VERSION "HNNBNNNYNNNNNNNNNNNNNNNNNNNNNNNNNNNNNNNNNN/4/%%%/4/'%**4NNN///"

NS_ :

BS_:

BU_: ABT_1_MIB_ab_Gen3 ABT_1_MQB BAP_Tester BT_1_MQB DU_1_MQB DU_2 DU_3 DU_4 ExBox Kombi_TT3 LSR_1 SCC1 SCC2 SDC1 SDC2 SFA TVTuner_ab_Gen3_JPN WLC_01 WLC_02 ZR_Entry ZR_High ZR_High_Korea ZR_High_TT3 ZR_MIB_OPTION_ab_Gen3 ZR_MIB_TOP_ab_Gen3 ZR_Standard

BO_ 2549940736 OBDC_Funktionaler_Req_All: 8 ZR_MIB_TOP_ab_Gen3
 SG_ OBDC_Funktionaler_Req_All_Data : 0|64@1+ (1,0) [0|1.84467440737096E+019] ""  WLC_02,WLC_01

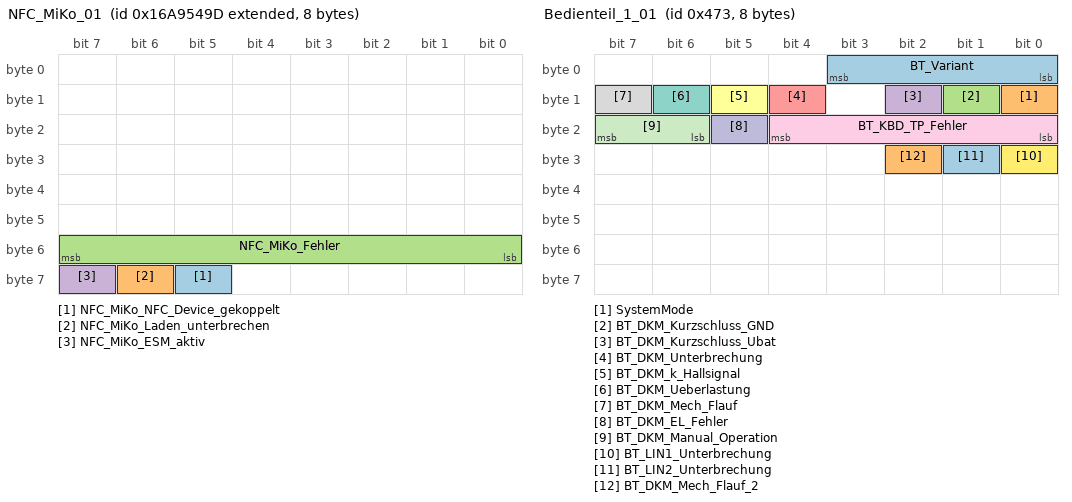
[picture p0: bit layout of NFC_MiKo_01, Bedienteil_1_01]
BO_ 2527679645 NFC_MiKo_01: 8 ZR_MIB_TOP_ab_Gen3
 SG_ NFC_MiKo_NFC_Device_gekoppelt : 61|1@1+ (1,0) [0|1] ""  WLC_01
 SG_ NFC_MiKo_Laden_unterbrechen : 62|1@1+ (1,0) [0|1] ""  WLC_01
 SG_ NFC_MiKo_Fehler : 48|8@1+ (1,0) [0|255] "" Vector__XXX
 SG_ NFC_MiKo_ESM_aktiv : 63|1@1+ (1,0) [0|1] "" Vector__XXX

BO_ 2583752965 ABT_1_SWDL_Req: 8 ABT_1_MQB
 SG_ ABT_1_SWDL_Req_Data : 0|64@1+ (1,0) [0|1.84467440737096E+019] ""  ZR_High,ZR_High_Korea,ZR_High_TT3,ZR_MIB_OPTION_ab_Gen3,ZR_MIB_TOP_ab_Gen3,ZR_Standard

BO_ 2583884037 ABT_1_SWDL_Resp: 8 ZR_High
 SG_ ABT_1_SWDL_Resp_Data : 0|64@1+ (1,0) [0|1.84467440737096E+019] ""  ABT_1_MQB

BO_ 2536714496 BAP_Audio_ASG_01: 8 Kombi_TT3
 SG_ BAP_Audio_ASG_01_Header : 0|8@1+ (1,0) [0|255] ""  ZR_High_TT3

BO_ 2536714497 BAP_Audio_ASG_02: 8 Kombi_TT3
 SG_ BAP_Audio_ASG_02_Header : 0|8@1+ (1,0) [0|255] ""  ZR_High_TT3

BO_ 2536714512 BAP_Audio_FSG_01: 8 ZR_High_TT3
 SG_ BAP_Audio_FSG_01_Header : 0|8@1+ (1,0) [0|255] ""  Kombi_TT3

BO_ 2536714513 BAP_Audio_FSG_02: 8 ZR_High_TT3
 SG_ BAP_Audio_FSG_02_Header : 0|8@1+ (1,0) [0|255] ""  Kombi_TT3

BO_ 2536767264 BAP_Debug_Cmd: 8 BAP_Tester
 SG_ BAP_Debug_Cmd : 0|16@1+ (1,0) [0|65535] ""  ExBox,Kombi_TT3,ZR_High_Korea,ZR_High_TT3

BO_ 2536767280 BAP_Debug_Data: 8 ExBox
 SG_ BAP_Debug_Data : 0|64@1+ (1,0) [0|1.84467440737096E+019] ""  BAP_Tester

BO_ 2536716288 BAP_ExBox_ASG_01: 8 ZR_High_Korea
 SG_ BAP_ExBox_ASG_01_Header : 0|8@1+ (1,0) [0|255] ""  ExBox

BO_ 2536716304 BAP_ExBox_FSG_01: 8 ExBox
 SG_ BAP_ExBox_FSG_01_Header : 0|8@1+ (1,0) [0|255] ""  ZR_High_Korea

BO_ 2536715264 BAP_MFL_ASG_01: 8 Kombi_TT3
 SG_ BAP_MFL_ASG_01_Header : 0|8@1+ (1,0) [0|255] ""  ZR_High_TT3

BO_ 2536715280 BAP_MFL_FSG_01: 8 ZR_High_TT3
 SG_ BAP_MFL_FSG_01_Header : 0|8@1+ (1,0) [0|255] ""  Kombi_TT3

BO_ 2536714752 BAP_Navigation_ASG_01: 8 Kombi_TT3
 SG_ BAP_Navigation_ASG_01_Header : 0|8@1+ (1,0) [0|255] ""  ExBox,ZR_High_TT3

BO_ 2536714753 BAP_Navigation_ASG_02: 8 Kombi_TT3
 SG_ BAP_Navigation_ASG_02_Header : 0|8@1+ (1,0) [0|255] ""  ExBox,ZR_High_TT3

BO_ 2536714754 BAP_Navigation_ASG_03: 8 ZR_High_Korea
 SG_ BAP_Navigation_ASG_03_Header : 0|8@1+ (1,0) [0|255] ""  ExBox

BO_ 2536714755 BAP_Navigation_ASG_04: 8 ZR_High_Korea
 SG_ BAP_Navigation_ASG_04_Header : 0|8@1+ (1,0) [0|255] ""  ExBox

BO_ 2536714768 BAP_Navigation_FSG_01: 8 ExBox
 SG_ BAP_Navigation_FSG_01_Header : 0|8@1+ (1,0) [0|255] ""  Kombi_TT3,ZR_High_Korea

BO_ 2536714769 BAP_Navigation_FSG_02: 8 ExBox
 SG_ BAP_Navigation_FSG_02_Header : 0|8@1+ (1,0) [0|255] ""  Kombi_TT3,ZR_High_Korea

BO_ 2536712448 BAP_Telefon2_ASG_01: 8 Kombi_TT3
 SG_ BAP_Telefon2_ASG_01_Header : 0|8@1+ (1,0) [0|255] ""  ExBox,ZR_High_TT3

BO_ 2536712464 BAP_Telefon2_FSG_01: 8 ExBox
 SG_ BAP_Telefon2_FSG_01_Header : 0|8@1+ (1,0) [0|255] ""  Kombi_TT3

BO_ 2536712192 BAP_Telefon_ASG_01: 8 Kombi_TT3
 SG_ BAP_Telefon_ASG_01_Header : 0|8@1+ (1,0) [0|255] ""  ExBox,ZR_High_TT3

BO_ 2536712193 BAP_Telefon_ASG_02: 8 Kombi_TT3
 SG_ BAP_Telefon_ASG_02_Header : 0|8@1+ (1,0) [0|255] ""  ExBox,ZR_High_TT3

BO_ 2536712194 BAP_Telefon_ASG_03: 8 ZR_High_Korea
 SG_ BAP_Telefon_ASG_03_Header : 0|8@1+ (1,0) [0|255] "Unit_None"  ExBox

BO_ 2536712195 BAP_Telefon_ASG_04: 8 ZR_High_Korea
 SG_ BAP_Telefon_ASG_04_Header : 0|8@1+ (1,0) [0|255] "Unit_None"  ExBox

BO_ 2536712208 BAP_Telefon_FSG_01: 8 ExBox
 SG_ BAP_Telefon_FSG_01_Header : 0|8@1+ (1,0) [0|255] ""  Kombi_TT3,ZR_High_Korea

BO_ 2536712209 BAP_Telefon_FSG_02: 8 ExBox
 SG_ BAP_Telefon_FSG_02_Header : 0|8@1+ (1,0) [0|255] ""  Kombi_TT3,ZR_High_Korea

BO_ 1139 Bedienteil_1_01: 8 BT_1_MQB
 SG_ BT_Variant : 0|4@1+ (1,0) [7|15] ""  ZR_Entry,ZR_High,ZR_High_Korea,ZR_High_TT3,ZR_MIB_OPTION_ab_Gen3,ZR_MIB_TOP_ab_Gen3,ZR_Standard
 SG_ SystemMode : 8|1@1+ (1,0) [0|1] ""  ZR_Entry,ZR_High,ZR_High_Korea,ZR_High_TT3,ZR_MIB_OPTION_ab_Gen3,ZR_MIB_TOP_ab_Gen3,ZR_Standard
 SG_ BT_DKM_Kurzschluss_GND : 9|1@1+ (1,0) [0|1] ""  ZR_Entry,ZR_High,ZR_High_Korea,ZR_High_TT3,ZR_MIB_OPTION_ab_Gen3,ZR_MIB_TOP_ab_Gen3,ZR_Standard
 SG_ BT_DKM_Kurzschluss_Ubat : 10|1@1+ (1,0) [0|1] ""  ZR_Entry,ZR_High,ZR_High_Korea,ZR_High_TT3,ZR_MIB_OPTION_ab_Gen3,ZR_MIB_TOP_ab_Gen3,ZR_Standard
 SG_ BT_DKM_Unterbrechung : 12|1@1+ (1,0) [0|1] ""  ZR_Entry,ZR_High,ZR_High_Korea,ZR_High_TT3,ZR_MIB_OPTION_ab_Gen3,ZR_MIB_TOP_ab_Gen3,ZR_Standard
 SG_ BT_DKM_k_Hallsignal : 13|1@1+ (1,0) [0|1] ""  ZR_Entry,ZR_High,ZR_High_Korea,ZR_High_TT3,ZR_MIB_OPTION_ab_Gen3,ZR_MIB_TOP_ab_Gen3,ZR_Standard
 SG_ BT_DKM_Ueberlastung : 14|1@1+ (1,0) [0|1] ""  ZR_Entry,ZR_High,ZR_High_Korea,ZR_High_TT3,ZR_MIB_OPTION_ab_Gen3,ZR_MIB_TOP_ab_Gen3,ZR_Standard
 SG_ BT_DKM_Mech_Flauf : 15|1@1+ (1,0) [0|1] ""  ZR_Entry,ZR_High,ZR_High_Korea,ZR_High_TT3,ZR_MIB_OPTION_ab_Gen3,ZR_MIB_TOP_ab_Gen3,ZR_Standard
 SG_ BT_KBD_TP_Fehler : 16|5@1+ (1,0) [1|31] ""  ZR_Entry,ZR_High,ZR_High_Korea,ZR_High_TT3,ZR_MIB_OPTION_ab_Gen3,ZR_MIB_TOP_ab_Gen3,ZR_Standard
 SG_ BT_DKM_EL_Fehler : 21|1@1+ (1,0) [0|1] ""  ZR_Entry,ZR_High,ZR_High_Korea,ZR_High_TT3,ZR_MIB_OPTION_ab_Gen3,ZR_MIB_TOP_ab_Gen3,ZR_Standard
 SG_ BT_DKM_Manual_Operation : 22|2@1+ (1,0) [0|3] ""  ZR_Entry,ZR_High,ZR_High_Korea,ZR_High_TT3,ZR_MIB_OPTION_ab_Gen3,ZR_MIB_TOP_ab_Gen3,ZR_Standard
 SG_ BT_LIN1_Unterbrechung : 24|1@1+ (1,0) [0|1] ""  ZR_Entry,ZR_High,ZR_High_Korea,ZR_High_TT3,ZR_MIB_OPTION_ab_Gen3,ZR_MIB_TOP_ab_Gen3,ZR_Standard
 SG_ BT_LIN2_Unterbrechung : 25|1@1+ (1,0) [0|1] ""  ZR_Entry,ZR_High,ZR_High_Korea,ZR_High_TT3,ZR_MIB_OPTION_ab_Gen3,ZR_MIB_TOP_ab_Gen3,ZR_Standard
 SG_ BT_DKM_Mech_Flauf_2 : 26|1@1+ (1,0) [0|1] ""  ZR_Entry,ZR_High,ZR_High_Korea,ZR_High_TT3,ZR_MIB_OPTION_ab_Gen3,ZR_MIB_TOP_ab_Gen3,ZR_Standard

BO_ 1635 BEM_02: 8 ZR_Entry
 SG_ BEM_02_Abschaltstufen : 0|3@1+ (1,0) [0|7] ""  ABT_1_MIB_ab_Gen3,ABT_1_MQB,BT_1_MQB,DU_3,DU_4,ExBox,LSR_1,SCC1,SCC2,SDC1,SDC2,WLC_01,WLC_02
 SG_ BEM_STH_Zielzeit : 3|4@1+ (5,0) [0|60] "Unit_Minut" Vector__XXX
 SG_ BEM_MMI_Vorwarnung : 7|1@1+ (1,0) [0|1] ""  BT_1_MQB,LSR_1,SCC1,SCC2,SDC1,SDC2
 SG_ BEM_HL_Kontingentierung : 8|6@1+ (50,-1000) [-1000|1000] "Unit_Watt" Vector__XXX
 SG_ NVEM_Freigabe_ZusBatt_Laden : 14|1@1+ (1,0) [0|1] "" Vector__XXX
 SG_ NVEM_Anf_SD_schalten : 15|1@1+ (1,0) [0|1] "" Vector__XXX
 SG_ BEM_Generatordiagnose : 16|2@1+ (1,0) [0|3] "" Vector__XXX
 SG_ BEM_Red_Innengeblaese : 18|2@1+ (1,0) [0|3] "" Vector__XXX
 SG_ BEM_STH_Einschaltverbot : 20|1@1+ (1,0) [0|1] "" Vector__XXX
 SG_ BEM_HL_Regelung_Status : 21|3@1+ (1,0) [0|7] "" Vector__XXX
 SG_ BEM_Ladezustand : 24|4@1+ (10,0) [0|100] "Unit_PerCent" Vector__XXX
 SG_ BEM_Batteriediagnose : 28|3@1+ (1,0) [0|7] "" Vector__XXX
 SG_ MIB_Stromsparmodus : 31|1@1+ (1,0) [0|1] "" Vector__XXX
 SG_ BEM_DFM : 32|5@1+ (3.225,0.025) [0.025|100] "" Vector__XXX
 SG_ BEM_REK_aktiv : 37|1@1+ (1,0) [0|1] "" Vector__XXX
 SG_ BEM_EMLIN_ungueltig : 38|1@1+ (1,0) [0|1] "" Vector__XXX
 SG_ BEM_Batt_Ab : 39|1@1+ (1,0) [0|1] "" Vector__XXX
 SG_ BEM_UBDM : 40|8@1+ (0.05,5) [5.05|17.7] "Unit_Volt" Vector__XXX
 SG_ BEM_UGenSoll : 48|6@1+ (0.1,10.6) [10.6|16] "Unit_Volt" Vector__XXX
 SG_ BEM_Anf_KL15_schalten : 54|2@1+ (1,0) [0|3] "" Vector__XXX
 SG_ NVEM_Batterie_Service : 56|2@1+ (1,0) [0|3] "" Vector__XXX
 SG_ NVEM_Freigabe_OnlineUpdate : 58|1@1+ (1,0) [0|1] "" Vector__XXX

BO_ 2583752709 BT_1_SWDL_Req: 8 BT_1_MQB
 SG_ BT_1_SWDL_Req_Data : 0|64@1+ (1,0) [0|1.84467440737096E+019] ""  ZR_Entry,ZR_High,ZR_High_Korea,ZR_High_TT3,ZR_MIB_OPTION_ab_Gen3,ZR_MIB_TOP_ab_Gen3,ZR_Standard

BO_ 2583883781 BT_1_SWDL_Resp: 8 ZR_Entry
 SG_ BT_1_SWDL_Resp_Data : 0|64@1+ (1,0) [0|1.84467440737096E+019] ""  BT_1_MQB

BO_ 2617215754 DEV_ABT_1_Gen3_Tx_01: 8 ABT_1_MIB_ab_Gen3
 SG_ DEV_ABT_1_Gen3_Tx_01_Data : 0|64@1+ (1,0) [0|1.84467440737096E+019] "" Vector__XXX

BO_ 2617215755 DEV_ABT_1_Gen3_Tx_02: 8 ABT_1_MIB_ab_Gen3
 SG_ DEV_ABT_1_Gen3_Tx_02_Data : 0|64@1+ (1,0) [0|1.84467440737096E+019] "" Vector__XXX

BO_ 2617215756 DEV_ABT_1_Gen3_Tx_03: 8 ABT_1_MIB_ab_Gen3
 SG_ DEV_ABT_1_Gen3_Tx_03_Data : 0|64@1+ (1,0) [0|1.84467440737096E+019] "" Vector__XXX

BO_ 2617215757 DEV_ABT_1_Gen3_Tx_04: 8 ABT_1_MIB_ab_Gen3
 SG_ DEV_ABT_1_Gen3_Tx_04_Data : 0|64@1+ (1,0) [0|1.84467440737096E+019] "" Vector__XXX

BO_ 2617215744 DEV_ABT_1_Req_00: 8 Vector__XXX
 SG_ DEV_ABT_1_Req_00 : 0|64@1+ (1,0) [0|1.84467440737096E+019] ""  ABT_1_MIB_ab_Gen3,ABT_1_MQB

BO_ 2617215748 DEV_ABT_1_Req_04: 8 Vector__XXX
 SG_ DEV_ABT_1_Req_04_Data : 0|64@1+ (1,0) [0|1.84467440737096E+019] ""  ABT_1_MIB_ab_Gen3,ABT_1_MQB

BO_ 2617215745 DEV_ABT_1_Resp_01: 8 ABT_1_MIB_ab_Gen3
 SG_ DEV_ABT_1_Resp_01 : 0|64@1+ (1,0) [0|1.84467440737096E+019] "" Vector__XXX

BO_ 2617215746 DEV_ABT_1_Resp_02: 8 ABT_1_MIB_ab_Gen3
 SG_ DEV_ABT_1_Resp_02 : 0|64@1+ (1,0) [0|1.84467440737096E+019] "" Vector__XXX

BO_ 2617215747 DEV_ABT_1_Resp_03: 8 ABT_1_MIB_ab_Gen3
 SG_ DEV_ABT_1_Resp_03 : 0|64@1+ (1,0) [0|1.84467440737096E+019] "" Vector__XXX

BO_ 2617215749 DEV_ABT_1_Resp_04: 8 ABT_1_MIB_ab_Gen3
 SG_ DEV_ABT_1_Resp_04_Data : 0|64@1+ (1,0) [0|1.84467440737096E+019] "" Vector__XXX

BO_ 2617213696 DEV_BT_1_Req_01: 8 Vector__XXX
 SG_ DEV_BT_1_Req_01 : 0|64@1+ (1,0) [0|1.84467440737096E+019] ""  BT_1_MQB

BO_ 2617213697 DEV_BT_1_Resp_01: 8 BT_1_MQB
 SG_ DEV_BT_1_Resp_01 : 0|64@1+ (1,0) [0|1.84467440737096E+019] "" Vector__XXX

BO_ 2617213698 DEV_BT_1_Tx_00: 8 BT_1_MQB
 SG_ DEV_BT_1_Tx_00 : 0|64@1+ (1,0) [0|1.84467440737096E+019] "" Vector__XXX

BO_ 2617213699 DEV_BT_1_Tx_01: 8 BT_1_MQB
 SG_ DEV_BT_1_Tx_01 : 0|64@1+ (1,0) [0|1.84467440737096E+019] "" Vector__XXX

BO_ 2617213700 DEV_BT_1_Tx_02: 8 BT_1_MQB
 SG_ DEV_BT_1_Tx_02 : 0|64@1+ (1,0) [0|1.84467440737096E+019] "" Vector__XXX

BO_ 2617217792 DEV_DU_1_Req_00: 8 Vector__XXX
 SG_ DEV_DU_1_Req_00_Data : 0|64@1+ (1,0) [0|1.84467440737096E+019] ""  DU_1_MQB

BO_ 2617217795 DEV_DU_1_Req_01: 8 Vector__XXX
 SG_ DEV_DU_1_Req_01_Data : 0|64@1+ (1,0) [0|1.84467440737096E+019] ""  DU_1_MQB

BO_ 2617217796 DEV_DU_1_Req_02: 8 Vector__XXX
 SG_ DEV_DU_1_Req_02_Data : 0|64@1+ (1,0) [0|1.84467440737096E+019] ""  DU_1_MQB

BO_ 2617217798 DEV_DU_1_Req_03: 8 Vector__XXX
 SG_ DEV_DU_1_Req_03_Data : 0|64@1+ (1,0) [0|1.84467440737096E+019] ""  DU_1_MQB

BO_ 2617217799 DEV_DU_1_Req_04: 8 Vector__XXX
 SG_ DEV_DU_1_Req_04_Data : 0|64@1+ (1,0) [0|1.84467440737096E+019] ""  DU_1_MQB

BO_ 2617217800 DEV_DU_1_Req_05: 8 Vector__XXX
 SG_ DEV_DU_1_Req_05_Data : 0|64@1+ (1,0) [0|1.84467440737096E+019] ""  DU_1_MQB

BO_ 2617217801 DEV_DU_1_Req_06: 8 Vector__XXX
 SG_ DEV_DU_1_Req_06_Data : 0|64@1+ (1,0) [0|1.84467440737096E+019] ""  DU_1_MQB

BO_ 2617217802 DEV_DU_1_Req_07: 8 Vector__XXX
 SG_ DEV_DU_1_Req_07_Data : 0|64@1+ (1,0) [0|1.84467440737096E+019] ""  DU_1_MQB

BO_ 2617217803 DEV_DU_1_Req_08: 8 Vector__XXX
 SG_ DEV_DU_1_Req_08_Data : 0|64@1+ (1,0) [0|1.84467440737096E+019] ""  DU_1_MQB

BO_ 2617217804 DEV_DU_1_Req_09: 8 Vector__XXX
 SG_ DEV_DU_1_Req_09_Data : 0|64@1+ (1,0) [0|1.84467440737096E+019] ""  DU_1_MQB

BO_ 2617217797 DEV_DU_1_Resp_00: 8 DU_1_MQB
 SG_ DEV_DU_1_Resp_00_Data : 0|64@1+ (1,0) [0|1.84467440737096E+019] "" Vector__XXX

BO_ 2617217793 DEV_DU_1_Resp_01: 8 DU_1_MQB
 SG_ DEV_DU_1_Resp_01_Data : 0|64@1+ (1,0) [0|1.84467440737096E+019] "" Vector__XXX

BO_ 2617217794 DEV_DU_1_Resp_02: 8 DU_1_MQB
 SG_ DEV_DU_1_Resp_02_Data : 0|64@1+ (1,0) [0|1.84467440737096E+019] "" Vector__XXX

BO_ 2617217805 DEV_DU_1_Resp_03: 8 DU_1_MQB
 SG_ DEV_DU_1_Resp_03_Data : 0|64@1+ (1,0) [0|1.84467440737096E+019] "" Vector__XXX

BO_ 2617217806 DEV_DU_1_Resp_04: 8 DU_1_MQB
 SG_ DEV_DU_1_Resp_04_Data : 0|64@1+ (1,0) [0|1.84467440737096E+019] "" Vector__XXX

BO_ 2617217807 DEV_DU_1_Resp_05: 8 DU_1_MQB
 SG_ DEV_DU_1_Resp_05_Data : 0|64@1+ (1,0) [0|1.84467440737096E+019] "" Vector__XXX

BO_ 2617217808 DEV_DU_1_Resp_06: 8 DU_1_MQB
 SG_ DEV_DU_1_Resp_06_Data : 0|64@1+ (1,0) [0|1.84467440737096E+019] "" Vector__XXX

BO_ 2617217809 DEV_DU_1_Resp_07: 8 DU_1_MQB
 SG_ DEV_DU_1_Resp_07_Data : 0|64@1+ (1,0) [0|1.84467440737096E+019] "" Vector__XXX

BO_ 2617217810 DEV_DU_1_Resp_08: 8 DU_1_MQB
 SG_ DEV_DU_1_Resp_08_Data : 0|64@1+ (1,0) [0|1.84467440737096E+019] "" Vector__XXX

BO_ 2617217811 DEV_DU_1_Resp_09: 8 DU_1_MQB
 SG_ DEV_DU_1_Resp_09_Data : 0|64@1+ (1,0) [0|1.84467440737096E+019] "" Vector__XXX

BO_ 2617223936 DEV_DU_2_Req_00: 8 Vector__XXX
 SG_ DEV_DU_2_Req_00_Data : 0|64@1+ (1,0) [0|1.84467440737096E+019] ""  DU_2

BO_ 2617223939 DEV_DU_2_Req_01: 8 Vector__XXX
 SG_ DEV_DU_2_Req_01_Data : 0|64@1+ (1,0) [0|1.84467440737096E+019] ""  DU_2

BO_ 2617223940 DEV_DU_2_Req_02: 8 Vector__XXX
 SG_ DEV_DU_2_Req_02_Data : 0|64@1+ (1,0) [0|1.84467440737096E+019] ""  DU_2

BO_ 2617223942 DEV_DU_2_Req_03: 8 Vector__XXX
 SG_ DEV_DU_2_Req_03_Data : 0|64@1+ (1,0) [0|1.84467440737096E+019] ""  DU_2

BO_ 2617223943 DEV_DU_2_Req_04: 8 Vector__XXX
 SG_ DEV_DU_2_Req_04_Data : 0|64@1+ (1,0) [0|1.84467440737096E+019] ""  DU_2

BO_ 2617223944 DEV_DU_2_Req_05: 8 Vector__XXX
 SG_ DEV_DU_2_Req_05_Data : 0|64@1+ (1,0) [0|1.84467440737096E+019] ""  DU_2

BO_ 2617223945 DEV_DU_2_Req_06: 8 Vector__XXX
 SG_ DEV_DU_2_Req_06_Data : 0|64@1+ (1,0) [0|1.84467440737096E+019] ""  DU_2

BO_ 2617223946 DEV_DU_2_Req_07: 8 Vector__XXX
 SG_ DEV_DU_2_Req_07_Data : 0|64@1+ (1,0) [0|1.84467440737096E+019] ""  DU_2

BO_ 2617223947 DEV_DU_2_Req_08: 8 Vector__XXX
 SG_ DEV_DU_2_Req_08_Data : 0|64@1+ (1,0) [0|1.84467440737096E+019] ""  DU_2

BO_ 2617223948 DEV_DU_2_Req_09: 8 Vector__XXX
 SG_ DEV_DU_2_Req_09_Data : 0|64@1+ (1,0) [0|1.84467440737096E+019] ""  DU_2

BO_ 2617223941 DEV_DU_2_Resp_00: 8 DU_2
 SG_ DEV_DU_2_Resp_00_Data : 0|64@1+ (1,0) [0|1.84467440737096E+019] "" Vector__XXX

BO_ 2617223937 DEV_DU_2_Resp_01: 8 DU_2
 SG_ DEV_DU_2_Resp_01_Data : 0|64@1+ (1,0) [0|1.84467440737096E+019] "" Vector__XXX

BO_ 2617223938 DEV_DU_2_Resp_02: 8 DU_2
 SG_ DEV_DU_2_Resp_02_Data : 0|64@1+ (1,0) [0|1.84467440737096E+019] "" Vector__XXX

BO_ 2617223949 DEV_DU_2_Resp_03: 8 DU_2
 SG_ DEV_DU_2_Resp_03_Data : 0|64@1+ (1,0) [0|1.84467440737096E+019] "" Vector__XXX

BO_ 2617223950 DEV_DU_2_Resp_04: 8 DU_2
 SG_ DEV_DU_2_Resp_04_Data : 0|64@1+ (1,0) [0|1.84467440737096E+019] "" Vector__XXX

BO_ 2617223951 DEV_DU_2_Resp_05: 8 DU_2
 SG_ DEV_DU_2_Resp_05_Data : 0|64@1+ (1,0) [0|1.84467440737096E+019] "" Vector__XXX

BO_ 2617223952 DEV_DU_2_Resp_06: 8 DU_2
 SG_ DEV_DU_2_Resp_06_Data : 0|64@1+ (1,0) [0|1.84467440737096E+019] "" Vector__XXX

BO_ 2617223953 DEV_DU_2_Resp_07: 8 DU_2
 SG_ DEV_DU_2_Resp_07_Data : 0|64@1+ (1,0) [0|1.84467440737096E+019] "" Vector__XXX

BO_ 2617223954 DEV_DU_2_Resp_08: 8 DU_2
 SG_ DEV_DU_2_Resp_08_Data : 0|64@1+ (1,0) [0|1.84467440737096E+019] "" Vector__XXX

BO_ 2617223955 DEV_DU_2_Resp_09: 8 DU_2
 SG_ DEV_DU_2_Resp_09_Data : 0|64@1+ (1,0) [0|1.84467440737096E+019] "" Vector__XXX

BO_ 2617152256 DEV_LSR_1_Req_01: 8 Vector__XXX
 SG_ DEV_LSR_1_Req_01 : 0|64@1+ (1,0) [0|1.84467440737096E+019] ""  LSR_1

BO_ 2617152257 DEV_LSR_1_Resp_01: 8 LSR_1
 SG_ DEV_LSR_1_Resp_01 : 0|64@1+ (1,0) [0|1.84467440737096E+019] "" Vector__XXX

BO_ 2617152258 DEV_LSR_1_Resp_02: 8 LSR_1
 SG_ DEV_LSR_1_Resp_02 : 0|64@1+ (1,0) [0|1.84467440737096E+019] "" Vector__XXX

BO_ 2617070336 DEV_SCC1_Req_00: 8 SCC1
 SG_ DEV_SCC_01_Req_00 : 0|64@1+ (1,0) [0|1.84467440737096E+019] "" Vector__XXX

BO_ 2617070337 DEV_SCC1_Resp_01: 8 SCC1
 SG_ DEV_SCC1_Resp_01 : 0|64@1+ (1,0) [0|1.84467440737096E+019] "" Vector__XXX

BO_ 2617070338 DEV_SCC1_Resp_02: 8 SCC1
 SG_ DEV_SCC1_Resp_02 : 0|64@1+ (1,0) [0|1.84467440737096E+019] "" Vector__XXX

BO_ 2617072384 DEV_SCC2_Req_00: 8 SCC2
 SG_ DEV_SCC2_Req_00 : 0|64@1+ (1,0) [0|1.84467440737096E+019] "" Vector__XXX

BO_ 2617072385 DEV_SCC2_Resp_01: 8 SCC2
 SG_ DEV_SCC2_Resp_01 : 0|64@1+ (1,0) [0|1.84467440737096E+019] "" Vector__XXX

BO_ 2617072386 DEV_SCC2_Resp_02: 8 SCC2
 SG_ DEV_SCC2_Resp_02 : 0|64@1+ (1,0) [0|1.84467440737096E+019] "" Vector__XXX

BO_ 2617064192 DEV_SDC1_Req_00: 8 Vector__XXX
 SG_ DEV_SDC1_Req_00 : 0|64@1+ (1,0) [0|1.84467440737096E+019] ""  SDC1

BO_ 2617064193 DEV_SDC1_Resp_01: 8 SDC1
 SG_ DEV_SDC1_Resp_01 : 0|64@1+ (1,0) [0|1.84467440737096E+019] "" Vector__XXX

BO_ 2617064194 DEV_SDC1_Resp_02: 8 SDC1
 SG_ DEV_SDC1_Resp_02 : 0|64@1+ (1,0) [0|1.84467440737096E+019] "" Vector__XXX

BO_ 2617066240 DEV_SDC2_Req_00: 8 Vector__XXX
 SG_ DEV_SDC2_Req_00 : 0|64@1+ (1,0) [0|1.84467440737096E+019] ""  SDC2

BO_ 2617066241 DEV_SDC2_Resp_01: 8 SDC2
 SG_ DEV_SDC2_Resp_01 : 0|64@1+ (1,0) [0|1.84467440737096E+019] "" Vector__XXX

BO_ 2617066242 DEV_SDC2_Resp_02: 8 SDC2
 SG_ DEV_SDC2_Resp_02 : 0|64@1+ (1,0) [0|1.84467440737096E+019] "" Vector__XXX

BO_ 2617219597 DEV_ZR_Req_0D: 8 Vector__XXX
 SG_ DEV_ZR_Req_0D_Data : 0|64@1+ (1,0) [0|1] ""  ZR_High_Korea,ZR_High_TT3

BO_ 2617219584 DEV_ZR_Resp_00: 8 ZR_High_Korea
 SG_ DEV_ZR_Resp_00_Data : 0|64@1+ (1,0) [0|1] "" Vector__XXX

BO_ 2617219604 DEV_ZR_Tx_14: 8 ZR_Entry
 SG_ DEV_ZR_Tx_14_Data : 0|64@1+ (1,0) [0|1] "" Vector__XXX

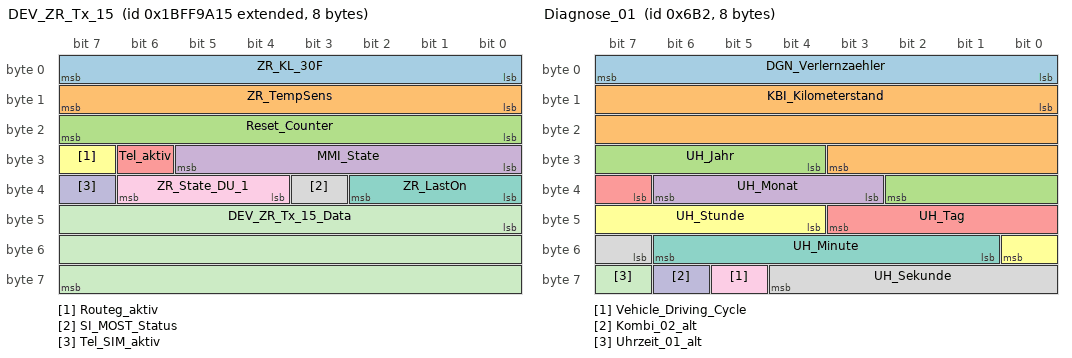
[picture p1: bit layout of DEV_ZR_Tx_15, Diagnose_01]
BO_ 2617219605 DEV_ZR_Tx_15: 8 ZR_Entry
 SG_ ZR_KL_30F : 0|8@1+ (0.1,0) [0|25.3] "Unit_Volt" Vector__XXX
 SG_ ZR_TempSens : 8|8@1+ (1,-55) [-55|127] "Unit_DegreCelsi" Vector__XXX
 SG_ Reset_Counter : 16|8@1+ (1,0) [0|253] "" Vector__XXX
 SG_ MMI_State : 24|6@1+ (1,0) [0|63] "" Vector__XXX
 SG_ Tel_aktiv : 30|1@1+ (1,0) [0|1] "" Vector__XXX
 SG_ Routeg_aktiv : 31|1@1+ (1,0) [0|1] "" Vector__XXX
 SG_ ZR_LastOn : 32|3@1+ (1,0) [0|6] "" Vector__XXX
 SG_ SI_MOST_Status : 35|1@1+ (1,0) [0|1] "" Vector__XXX
 SG_ ZR_State_DU_1 : 36|3@1+ (1,0) [0|7] "" Vector__XXX
 SG_ Tel_SIM_aktiv : 39|1@1+ (1,0) [0|1] "" Vector__XXX
 SG_ DEV_ZR_Tx_15_Data : 40|24@1+ (1,0) [0|1] "" Vector__XXX

BO_ 2549880334 DIA_ABT_1_Req: 8 Vector__XXX
 SG_ DIA_ABT_1_Req_Data : 0|64@1+ (1,0) [0|1.84467440737096E+019] ""  ABT_1_MIB_ab_Gen3

BO_ 2550011406 DIA_ABT_1_Resp: 8 ABT_1_MIB_ab_Gen3
 SG_ DIA_ABT_1_Resp_Data : 0|64@1+ (1,0) [0|1.84467440737096E+019] "" Vector__XXX

BO_ 2549880610 DIA_SCON1_Req: 8 ZR_High
 SG_ DIA_SCON1_Req_Data : 0|64@1+ (1,0) [0|1.84467440737096E+019] ""  SCC1

BO_ 2550011682 DIA_SCON1_Resp: 8 SCC1
 SG_ DIA_SCON1_Resp_Data : 0|64@1+ (1,0) [0|1.84467440737096E+019] ""  ZR_High

BO_ 2549880611 DIA_SCON2_Req: 8 ZR_High
 SG_ DIA_SCON2_Req_Data : 0|64@1+ (1,0) [0|1.84467440737096E+019] ""  SCC2

BO_ 2550011683 DIA_SCON2_Resp: 8 SCC2
 SG_ DIA_SCON2_Resp_Data : 0|64@1+ (1,0) [0|1.84467440737096E+019] ""  ZR_High

BO_ 2549880473 DIA_SD3_Req: 8 ZR_High
 SG_ DIA_SD3_Req_Data : 0|64@1+ (1,0) [0|1.84467440737096E+019] ""  SDC1

BO_ 2550011545 DIA_SD3_Resp: 8 SDC1
 SG_ DIA_SD3_Resp_Data : 0|64@1+ (1,0) [0|1.84467440737096E+019] ""  ZR_High

BO_ 2549880474 DIA_SD4_Req: 8 ZR_High
 SG_ DIA_SD4_Req_Data : 0|64@1+ (1,0) [0|1.84467440737096E+019] ""  SDC2

BO_ 2550011546 DIA_SD4_Resp: 8 SDC2
 SG_ DIA_SD4_Resp_Data : 0|64@1+ (1,0) [0|1.84467440737096E+019] ""  ZR_High

BO_ 2549876238 Diag_ABT_1_Req: 8 ZR_High
 SG_ Diag_ABT_1_Req_Data : 0|64@1+ (1,0) [0|1.84467440737096E+019] ""  ABT_1_MIB_ab_Gen3,ABT_1_MQB

BO_ 2550007310 Diag_ABT_1_Resp: 8 ABT_1_MIB_ab_Gen3
 SG_ Diag_ABT_1_Resp_Data : 0|64@1+ (1,0) [0|1.84467440737096E+019] ""  ZR_High,ZR_High_Korea,ZR_High_TT3,ZR_MIB_OPTION_ab_Gen3,ZR_MIB_TOP_ab_Gen3,ZR_Standard

BO_ 2549876295 Diag_BT_1_Req: 8 ZR_Entry
 SG_ Diag_BT_1_Req_Data : 0|64@1+ (1,0) [0|1.84467440737096E+019] ""  BT_1_MQB

BO_ 2550007367 Diag_BT_1_Resp: 8 BT_1_MQB
 SG_ Diag_BT_1_Resp_Data : 0|64@1+ (1,0) [0|1.84467440737096E+019] ""  ZR_Entry,ZR_High,ZR_High_Korea,ZR_High_TT3,ZR_MIB_OPTION_ab_Gen3,ZR_MIB_TOP_ab_Gen3,ZR_Standard

BO_ 2549876278 Diag_DU_1_Req: 8 ZR_Entry
 SG_ Diag_DU_1_Req_Data : 0|64@1+ (1,0) [0|1.84467440737096E+019] ""  DU_1_MQB

BO_ 2550007350 Diag_DU_1_Resp: 8 DU_1_MQB
 SG_ Diag_DU_1_Resp_Data : 0|64@1+ (1,0) [0|1.84467440737096E+019] ""  ZR_Entry,ZR_High,ZR_High_Korea,ZR_High_TT3,ZR_MIB_OPTION_ab_Gen3,ZR_MIB_TOP_ab_Gen3,ZR_Standard

BO_ 2549876379 Diag_DU_2_Req: 8 ZR_High
 SG_ Diag_DU_2_Req_Data : 0|64@1+ (1,0) [0|1.84467440737096E+019] ""  DU_2

BO_ 2550007451 Diag_DU_2_Resp: 8 DU_2
 SG_ Diag_DU_2_Resp_Data : 0|64@1+ (1,0) [0|1.84467440737096E+019] ""  ZR_High,ZR_MIB_OPTION_ab_Gen3,ZR_MIB_TOP_ab_Gen3,ZR_Standard

BO_ 2549876381 Diag_DU_3_Req: 8 ZR_High
 SG_ Diag_DU_3_Req_Data : 0|64@1+ (1,0) [0|1.84467440737096E+019] ""  DU_3

BO_ 2550007453 Diag_DU_3_Resp: 8 DU_3
 SG_ Diag_DU_3_Resp_Data : 0|64@1+ (1,0) [0|1.84467440737096E+019] ""  ZR_High,ZR_MIB_TOP_ab_Gen3

BO_ 2549876382 Diag_DU_4_Req: 8 ZR_High
 SG_ Diag_DU_4_Req_Data : 0|64@1+ (1,0) [0|1.84467440737096E+019] ""  DU_4

BO_ 2550007454 Diag_DU_4_Resp: 8 DU_4
 SG_ Diag_DU_4_Resp_Data : 0|64@1+ (1,0) [0|1.84467440737096E+019] ""  ZR_High

BO_ 2549876371 Diag_LSR_1_Req: 8 ZR_High
 SG_ Diag_LSR_1_Req_Data : 0|64@1+ (1,0) [0|1.84467440737096E+019] ""  LSR_1

BO_ 2550007443 Diag_LSR_1_Resp: 8 LSR_1
 SG_ Diag_LSR_1_Resp_Data : 0|64@1+ (1,0) [0|1.84467440737096E+019] ""  ZR_High,ZR_MIB_OPTION_ab_Gen3,ZR_MIB_TOP_ab_Gen3,ZR_Standard

BO_ 1714 Diagnose_01: 8 ZR_High
 SG_ DGN_Verlernzaehler : 0|8@1+ (1,0) [0|254] ""  ABT_1_MIB_ab_Gen3,ExBox,SCC1,SCC2,SDC1,SDC2
 SG_ KBI_Kilometerstand : 8|20@1+ (1,0) [0|1048573] "Unit_KiloMeter"  ABT_1_MIB_ab_Gen3,ExBox,SCC1,SCC2,SDC1,SDC2
 SG_ UH_Jahr : 28|7@1+ (1,2000) [2000|2127] "Unit_Year"  DU_1_MQB,DU_2,WLC_01,WLC_02,ABT_1_MIB_ab_Gen3,DU_4,ExBox,SCC1,SCC2,SDC1,SDC2,TVTuner_ab_Gen3_JPN
 SG_ UH_Monat : 35|4@1+ (1,0) [1|12] "Unit_Month"  DU_2,DU_1_MQB,WLC_01,WLC_02,ABT_1_MIB_ab_Gen3,DU_4,ExBox,SCC1,SCC2,SDC1,SDC2,TVTuner_ab_Gen3_JPN
 SG_ UH_Tag : 39|5@1+ (1,0) [1|31] "Unit_Day"  DU_1_MQB,DU_2,WLC_01,WLC_02,ABT_1_MIB_ab_Gen3,DU_4,ExBox,SCC1,SCC2,SDC1,SDC2,TVTuner_ab_Gen3_JPN
 SG_ UH_Stunde : 44|5@1+ (1,0) [0|23] "Unit_Hours"  DU_1_MQB,DU_2,WLC_01,WLC_02,ABT_1_MIB_ab_Gen3,DU_4,ExBox,SCC1,SCC2,SDC1,SDC2,TVTuner_ab_Gen3_JPN
 SG_ UH_Minute : 49|6@1+ (1,0) [0|59] "Unit_Minut"  DU_1_MQB,DU_2,WLC_01,WLC_02,ABT_1_MIB_ab_Gen3,DU_4,ExBox,SCC1,SCC2,SDC1,SDC2,TVTuner_ab_Gen3_JPN
 SG_ UH_Sekunde : 55|6@1+ (1,0) [0|59] "Unit_Secon"  DU_1_MQB,DU_2,WLC_01,WLC_02,ABT_1_MIB_ab_Gen3,DU_4,ExBox,SCC1,SCC2,SDC1,SDC2,TVTuner_ab_Gen3_JPN
 SG_ Vehicle_Driving_Cycle : 61|1@1+ (1,0) [0|1] ""  ABT_1_MIB_ab_Gen3
 SG_ Kombi_02_alt : 62|1@1+ (1,0) [0|1] ""  WLC_01,WLC_02,ABT_1_MIB_ab_Gen3,ExBox,SCC1,SCC2,SDC1,SDC2
 SG_ Uhrzeit_01_alt : 63|1@1+ (1,0) [0|1] ""  WLC_01,WLC_02,ABT_1_MIB_ab_Gen3,ExBox,SCC1,SCC2,SDC1,SDC2

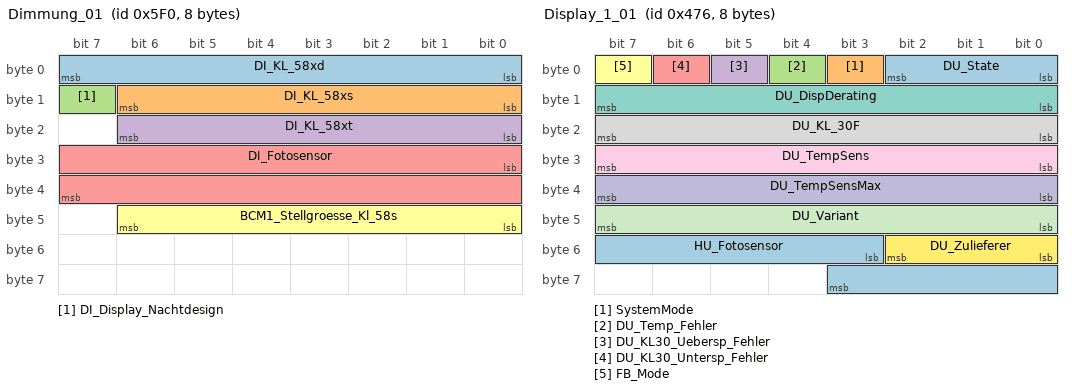
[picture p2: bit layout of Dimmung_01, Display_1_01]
BO_ 1520 Dimmung_01: 8 ZR_Entry
 SG_ DI_KL_58xd : 0|8@1+ (1,0) [0|253] ""  SCC1,ABT_1_MIB_ab_Gen3,ABT_1_MQB,BT_1_MQB,DU_1_MQB,DU_2,DU_3,DU_4,ExBox,LSR_1,SDC1,SDC2
 SG_ DI_KL_58xs : 8|7@1+ (1,0) [0|100] "Unit_PerCent"  SCC1,ABT_1_MIB_ab_Gen3,ABT_1_MQB,BT_1_MQB,DU_1_MQB,DU_2,DU_3,DU_4,ExBox,LSR_1,SDC1,SDC2
 SG_ DI_Display_Nachtdesign : 15|1@1+ (1,0) [0|1] ""  DU_2,DU_3,DU_4,ExBox
 SG_ DI_KL_58xt : 16|7@1+ (1,0) [0|100] "Unit_PerCent" Vector__XXX
 SG_ DI_Fotosensor : 24|16@1+ (1,0) [0|65535] "" Vector__XXX
 SG_ BCM1_Stellgroesse_Kl_58s : 40|7@1+ (1,0) [0|100] "" Vector__XXX

BO_ 1142 Display_1_01: 8 ABT_1_MIB_ab_Gen3
 SG_ DU_State : 0|3@1+ (1,0) [0|7] ""  ZR_Entry,ZR_High,ZR_High_Korea,ZR_High_TT3,ZR_MIB_OPTION_ab_Gen3,ZR_MIB_TOP_ab_Gen3,ZR_Standard
 SG_ SystemMode : 3|1@1+ (1,0) [0|1] ""  ZR_Entry,ZR_High,ZR_High_Korea,ZR_High_TT3,ZR_MIB_OPTION_ab_Gen3,ZR_MIB_TOP_ab_Gen3,ZR_Standard
 SG_ DU_Temp_Fehler : 4|1@1+ (1,0) [0|1] ""  ZR_Entry,ZR_High,ZR_High_Korea,ZR_High_TT3,ZR_MIB_OPTION_ab_Gen3,ZR_MIB_TOP_ab_Gen3,ZR_Standard
 SG_ DU_KL30_Uebersp_Fehler : 5|1@1+ (1,0) [0|1] ""  ZR_Entry,ZR_High,ZR_High_Korea,ZR_High_TT3,ZR_MIB_OPTION_ab_Gen3,ZR_MIB_TOP_ab_Gen3,ZR_Standard
 SG_ DU_KL30_Untersp_Fehler : 6|1@1+ (1,0) [0|1] ""  ZR_Entry,ZR_High,ZR_High_Korea,ZR_High_TT3,ZR_MIB_OPTION_ab_Gen3,ZR_MIB_TOP_ab_Gen3,ZR_Standard
 SG_ FB_Mode : 7|1@1+ (1,0) [0|1] "" Vector__XXX
 SG_ DU_DispDerating : 8|8@1+ (1,0) [0|100] "Unit_PerCent"  DU_2,DU_4,ZR_Entry,ZR_High,ZR_High_Korea,ZR_High_TT3,ZR_MIB_OPTION_ab_Gen3,ZR_MIB_TOP_ab_Gen3,ZR_Standard
 SG_ DU_KL_30F : 16|8@1+ (0.1,0) [0|25.3] "Unit_Volt"  ZR_Entry,ZR_High,ZR_High_Korea,ZR_High_TT3,ZR_MIB_OPTION_ab_Gen3,ZR_MIB_TOP_ab_Gen3,ZR_Standard
 SG_ DU_TempSens : 24|8@1+ (1,-55) [-55|127] "Unit_DegreCelsi"  BT_1_MQB,ZR_Entry,ZR_High,ZR_High_Korea,ZR_High_TT3,ZR_MIB_OPTION_ab_Gen3,ZR_MIB_TOP_ab_Gen3,ZR_Standard
 SG_ DU_TempSensMax : 32|8@1+ (1,-55) [-55|127] "Unit_DegreCelsi"  ZR_Entry,ZR_High,ZR_High_Korea,ZR_High_TT3,ZR_MIB_OPTION_ab_Gen3,ZR_MIB_TOP_ab_Gen3,ZR_Standard
 SG_ DU_Variant : 40|8@1+ (1,0) [0|253] ""  BT_1_MQB,ZR_Entry,ZR_High,ZR_High_Korea,ZR_High_TT3,ZR_MIB_OPTION_ab_Gen3,ZR_MIB_TOP_ab_Gen3,ZR_Standard
 SG_ DU_Zulieferer : 48|3@1+ (1,0) [0|7] ""  ZR_Entry,ZR_High,ZR_High_Korea,ZR_High_TT3,ZR_MIB_OPTION_ab_Gen3,ZR_MIB_TOP_ab_Gen3,ZR_Standard
 SG_ HU_Fotosensor : 51|9@1+ (0.25,0) [0|100] "Unit_PerCent"  ZR_High,ZR_MIB_OPTION_ab_Gen3,ZR_MIB_TOP_ab_Gen3,ZR_Standard

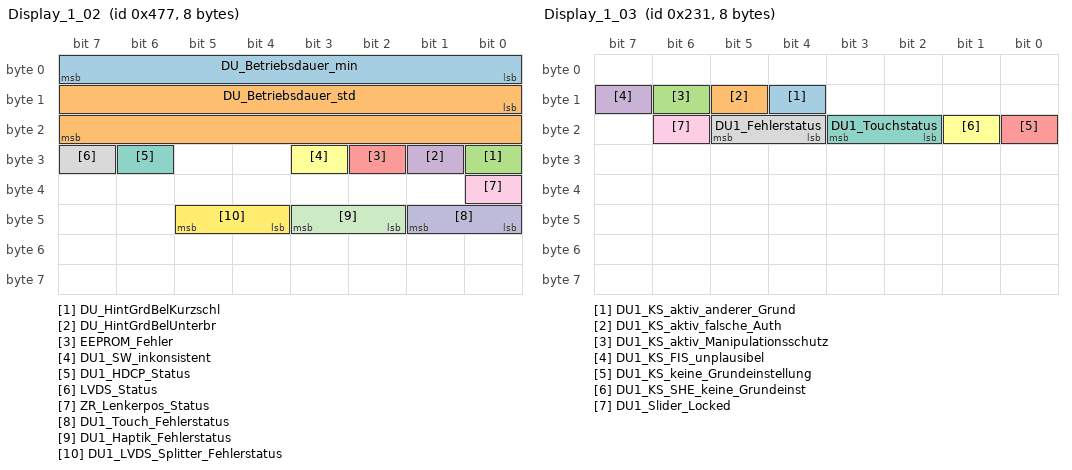
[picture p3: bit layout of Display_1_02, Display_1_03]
BO_ 1143 Display_1_02: 8 ABT_1_MIB_ab_Gen3
 SG_ DU_Betriebsdauer_min : 0|8@1+ (1,0) [0|59] "Unit_Minut"  ZR_Entry,ZR_High,ZR_High_Korea,ZR_High_TT3,ZR_MIB_OPTION_ab_Gen3,ZR_MIB_TOP_ab_Gen3,ZR_Standard
 SG_ DU_Betriebsdauer_std : 8|16@1+ (1,0) [0|65533] "Unit_Hours"  ZR_Entry,ZR_High,ZR_High_Korea,ZR_High_TT3,ZR_MIB_OPTION_ab_Gen3,ZR_MIB_TOP_ab_Gen3,ZR_Standard
 SG_ DU_HintGrdBelKurzschl : 24|1@1+ (1,0) [0|1] ""  ZR_Entry,ZR_High,ZR_High_Korea,ZR_High_TT3,ZR_MIB_OPTION_ab_Gen3,ZR_MIB_TOP_ab_Gen3,ZR_Standard
 SG_ DU_HintGrdBelUnterbr : 25|1@1+ (1,0) [0|1] ""  ZR_Entry,ZR_High,ZR_High_Korea,ZR_High_TT3,ZR_MIB_OPTION_ab_Gen3,ZR_MIB_TOP_ab_Gen3,ZR_Standard
 SG_ EEPROM_Fehler : 26|1@1+ (1,0) [0|1] ""  ZR_Entry,ZR_High,ZR_High_Korea,ZR_High_TT3,ZR_MIB_OPTION_ab_Gen3,ZR_MIB_TOP_ab_Gen3,ZR_Standard
 SG_ DU1_SW_inkonsistent : 27|1@1+ (1,0) [0|1] ""  ZR_Entry,ZR_High,ZR_High_Korea,ZR_High_TT3,ZR_MIB_OPTION_ab_Gen3,ZR_MIB_TOP_ab_Gen3,ZR_Standard
 SG_ DU1_HDCP_Status : 30|1@1+ (1,0) [0|1] ""  ZR_Entry,ZR_High,ZR_High_Korea,ZR_High_TT3,ZR_MIB_OPTION_ab_Gen3,ZR_MIB_TOP_ab_Gen3,ZR_Standard
 SG_ LVDS_Status : 31|1@1+ (1,0) [0|1] ""  ZR_Entry,ZR_High,ZR_High_Korea,ZR_High_TT3,ZR_MIB_OPTION_ab_Gen3,ZR_MIB_TOP_ab_Gen3,ZR_Standard
 SG_ ZR_Lenkerpos_Status : 32|1@1+ (1,0) [0|1] "" Vector__XXX
 SG_ DU1_Touch_Fehlerstatus : 40|2@1+ (1,0) [0|3] ""  ZR_Entry,ZR_High,ZR_High_Korea,ZR_High_TT3,ZR_MIB_OPTION_ab_Gen3,ZR_MIB_TOP_ab_Gen3,ZR_Standard
 SG_ DU1_Haptik_Fehlerstatus : 42|2@1+ (1,0) [0|3] ""  ZR_Entry,ZR_High,ZR_High_Korea,ZR_High_TT3,ZR_MIB_OPTION_ab_Gen3,ZR_MIB_TOP_ab_Gen3,ZR_Standard
 SG_ DU1_LVDS_Splitter_Fehlerstatus : 44|2@1+ (1,0) [0|3] ""  ZR_Entry,ZR_High,ZR_High_Korea,ZR_High_TT3,ZR_MIB_OPTION_ab_Gen3,ZR_MIB_TOP_ab_Gen3,ZR_Standard

BO_ 561 Display_1_03: 8 ABT_1_MIB_ab_Gen3
 SG_ DU1_KS_aktiv_anderer_Grund : 12|1@1+ (1,0) [0|1] ""  ZR_MIB_OPTION_ab_Gen3
 SG_ DU1_KS_aktiv_falsche_Auth : 13|1@1+ (1,0) [0|1] ""  ZR_MIB_OPTION_ab_Gen3
 SG_ DU1_KS_aktiv_Manipulationsschutz : 14|1@1+ (1,0) [0|1] ""  ZR_MIB_OPTION_ab_Gen3
 SG_ DU1_KS_FIS_unplausibel : 15|1@1+ (1,0) [0|1] ""  ZR_MIB_OPTION_ab_Gen3
 SG_ DU1_KS_keine_Grundeinstellung : 16|1@1+ (1,0) [0|1] ""  ZR_MIB_OPTION_ab_Gen3
 SG_ DU1_KS_SHE_keine_Grundeinst : 17|1@1+ (1,0) [0|1] ""  ZR_MIB_OPTION_ab_Gen3
 SG_ DU1_Touchstatus : 18|2@1+ (1,0) [0|3] "" Vector__XXX
 SG_ DU1_Fehlerstatus : 20|2@1+ (1,0) [0|3] "" Vector__XXX
 SG_ DU1_Slider_Locked : 22|1@1+ (1,0) [0|1] "" Vector__XXX

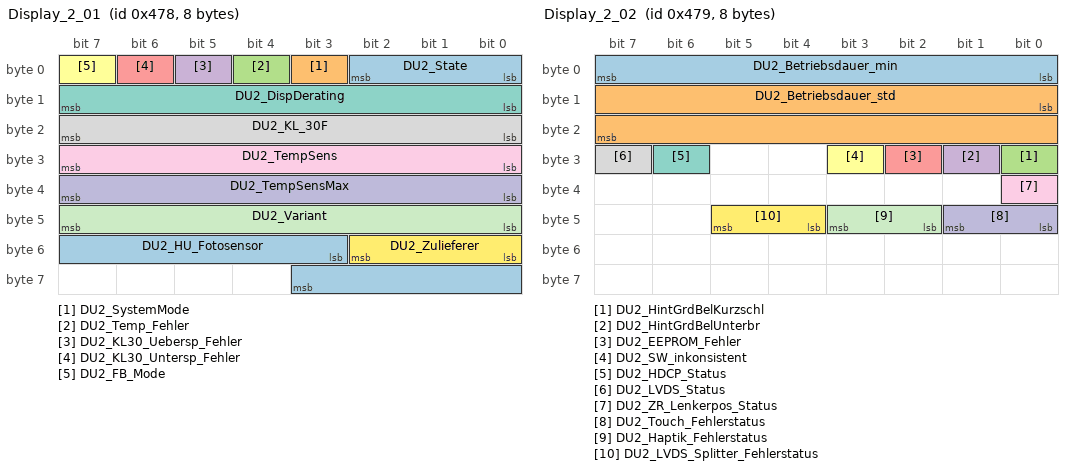
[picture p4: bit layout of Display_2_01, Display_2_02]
BO_ 1144 Display_2_01: 8 DU_2
 SG_ DU2_State : 0|3@1+ (1,0) [0|7] ""  ZR_High,ZR_MIB_OPTION_ab_Gen3,ZR_MIB_TOP_ab_Gen3,ZR_Standard
 SG_ DU2_SystemMode : 3|1@1+ (1,0) [0|1] ""  ZR_High,ZR_MIB_OPTION_ab_Gen3,ZR_MIB_TOP_ab_Gen3,ZR_Standard
 SG_ DU2_Temp_Fehler : 4|1@1+ (1,0) [0|1] ""  ZR_High,ZR_MIB_OPTION_ab_Gen3,ZR_MIB_TOP_ab_Gen3,ZR_Standard
 SG_ DU2_KL30_Uebersp_Fehler : 5|1@1+ (1,0) [0|1] ""  ZR_High,ZR_MIB_OPTION_ab_Gen3,ZR_MIB_TOP_ab_Gen3,ZR_Standard
 SG_ DU2_KL30_Untersp_Fehler : 6|1@1+ (1,0) [0|1] ""  ZR_High,ZR_MIB_OPTION_ab_Gen3,ZR_MIB_TOP_ab_Gen3,ZR_Standard
 SG_ DU2_FB_Mode : 7|1@1+ (1,0) [0|1] ""  ZR_High,ZR_MIB_OPTION_ab_Gen3,ZR_MIB_TOP_ab_Gen3,ZR_Standard
 SG_ DU2_DispDerating : 8|8@1+ (1,0) [0|100] "Unit_PerCent"  DU_1_MQB,ZR_High,ZR_MIB_OPTION_ab_Gen3,ZR_MIB_TOP_ab_Gen3,ZR_Standard
 SG_ DU2_KL_30F : 16|8@1+ (0.1,0) [0|25.3] "Unit_Volt"  ZR_High,ZR_MIB_OPTION_ab_Gen3,ZR_MIB_TOP_ab_Gen3,ZR_Standard
 SG_ DU2_TempSens : 24|8@1+ (1,-55) [-55|127] "Unit_DegreCelsi"  ZR_High,ZR_MIB_OPTION_ab_Gen3,ZR_MIB_TOP_ab_Gen3,ZR_Standard
 SG_ DU2_TempSensMax : 32|8@1+ (1,-55) [-55|127] "Unit_DegreCelsi"  ZR_High,ZR_MIB_OPTION_ab_Gen3,ZR_MIB_TOP_ab_Gen3,ZR_Standard
 SG_ DU2_Variant : 40|8@1+ (1,0) [0|253] ""  ZR_High,ZR_MIB_OPTION_ab_Gen3,ZR_MIB_TOP_ab_Gen3,ZR_Standard
 SG_ DU2_Zulieferer : 48|3@1+ (1,0) [0|7] ""  ZR_High,ZR_MIB_OPTION_ab_Gen3,ZR_MIB_TOP_ab_Gen3,ZR_Standard
 SG_ DU2_HU_Fotosensor : 51|9@1+ (0.25,0) [0|100] "Unit_PerCent"  ZR_High,ZR_MIB_OPTION_ab_Gen3,ZR_MIB_TOP_ab_Gen3,ZR_Standard

BO_ 1145 Display_2_02: 8 DU_2
 SG_ DU2_Betriebsdauer_min : 0|8@1+ (1,0) [0|59] "Unit_Minut"  ZR_High,ZR_MIB_OPTION_ab_Gen3,ZR_MIB_TOP_ab_Gen3,ZR_Standard
 SG_ DU2_Betriebsdauer_std : 8|16@1+ (1,0) [0|65533] "Unit_Hours"  ZR_High,ZR_MIB_OPTION_ab_Gen3,ZR_MIB_TOP_ab_Gen3,ZR_Standard
 SG_ DU2_HintGrdBelKurzschl : 24|1@1+ (1,0) [0|1] ""  ZR_High,ZR_MIB_OPTION_ab_Gen3,ZR_MIB_TOP_ab_Gen3,ZR_Standard
 SG_ DU2_HintGrdBelUnterbr : 25|1@1+ (1,0) [0|1] ""  ZR_High,ZR_MIB_OPTION_ab_Gen3,ZR_MIB_TOP_ab_Gen3,ZR_Standard
 SG_ DU2_EEPROM_Fehler : 26|1@1+ (1,0) [0|1] ""  ZR_High,ZR_MIB_OPTION_ab_Gen3,ZR_MIB_TOP_ab_Gen3,ZR_Standard
 SG_ DU2_SW_inkonsistent : 27|1@1+ (1,0) [0|1] ""  ZR_High,ZR_MIB_OPTION_ab_Gen3,ZR_MIB_TOP_ab_Gen3,ZR_Standard
 SG_ DU2_HDCP_Status : 30|1@1+ (1,0) [0|1] ""  ZR_High,ZR_MIB_OPTION_ab_Gen3,ZR_MIB_TOP_ab_Gen3,ZR_Standard
 SG_ DU2_LVDS_Status : 31|1@1+ (1,0) [0|1] ""  ZR_High,ZR_MIB_OPTION_ab_Gen3,ZR_MIB_TOP_ab_Gen3,ZR_Standard
 SG_ DU2_ZR_Lenkerpos_Status : 32|1@1+ (1,0) [0|1] ""  ZR_High,ZR_MIB_OPTION_ab_Gen3,ZR_MIB_TOP_ab_Gen3,ZR_Standard
 SG_ DU2_Touch_Fehlerstatus : 40|2@1+ (1,0) [0|3] ""  ZR_High,ZR_MIB_OPTION_ab_Gen3,ZR_MIB_TOP_ab_Gen3,ZR_Standard
 SG_ DU2_Haptik_Fehlerstatus : 42|2@1+ (1,0) [0|3] ""  ZR_High,ZR_MIB_OPTION_ab_Gen3,ZR_MIB_TOP_ab_Gen3,ZR_Standard
 SG_ DU2_LVDS_Splitter_Fehlerstatus : 44|2@1+ (1,0) [0|3] ""  ZR_High,ZR_MIB_OPTION_ab_Gen3,ZR_MIB_TOP_ab_Gen3,ZR_Standard

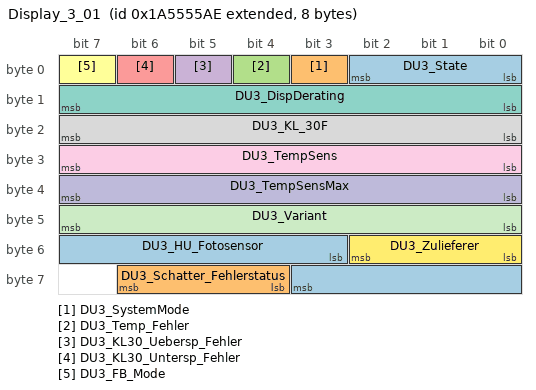
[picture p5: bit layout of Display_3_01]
BO_ 2589283758 Display_3_01: 8 DU_3
 SG_ DU3_State : 0|3@1+ (1,0) [0|7] ""  ZR_High,ZR_MIB_TOP_ab_Gen3
 SG_ DU3_SystemMode : 3|1@1+ (1,0) [0|1] ""  ZR_High,ZR_MIB_TOP_ab_Gen3
 SG_ DU3_Temp_Fehler : 4|1@1+ (1,0) [0|1] ""  ZR_High,ZR_MIB_TOP_ab_Gen3
 SG_ DU3_KL30_Uebersp_Fehler : 5|1@1+ (1,0) [0|1] ""  ZR_High,ZR_MIB_TOP_ab_Gen3
 SG_ DU3_KL30_Untersp_Fehler : 6|1@1+ (1,0) [0|1] ""  ZR_High,ZR_MIB_TOP_ab_Gen3
 SG_ DU3_FB_Mode : 7|1@1+ (1,0) [0|1] ""  ZR_High,ZR_MIB_TOP_ab_Gen3
 SG_ DU3_DispDerating : 8|8@1+ (1,0) [0|100] "Unit_PerCent"  ZR_High,ZR_MIB_TOP_ab_Gen3
 SG_ DU3_KL_30F : 16|8@1+ (0.1,0) [0|25.3] "Unit_Volt"  ZR_High,ZR_MIB_TOP_ab_Gen3
 SG_ DU3_TempSens : 24|8@1+ (1,-55) [-55|127] "Unit_DegreCelsi"  ZR_High,ZR_MIB_TOP_ab_Gen3
 SG_ DU3_TempSensMax : 32|8@1+ (1,-55) [-55|127] "Unit_DegreCelsi"  ZR_High,ZR_MIB_TOP_ab_Gen3
 SG_ DU3_Variant : 40|8@1+ (1,0) [0|253] ""  ZR_High,ZR_MIB_TOP_ab_Gen3
 SG_ DU3_Zulieferer : 48|3@1+ (1,0) [0|7] ""  ZR_High,ZR_MIB_TOP_ab_Gen3
 SG_ DU3_HU_Fotosensor : 51|9@1+ (0.25,0) [0.25|100] "Unit_PerCent"  ZR_High,ZR_MIB_TOP_ab_Gen3
 SG_ DU3_Schatter_Fehlerstatus : 60|3@1+ (1,0) [0|7] ""  ZR_High,ZR_MIB_TOP_ab_Gen3

BO_TX_BU_ 2549940736 : ZR_High,ZR_MIB_TOP_ab_Gen3;
BO_TX_BU_ 2527679645 : ZR_High,ZR_MIB_TOP_ab_Gen3;
BO_TX_BU_ 2583884037 : ZR_High,ZR_High_Korea,ZR_High_TT3,ZR_MIB_OPTION_ab_Gen3,ZR_MIB_TOP_ab_Gen3,ZR_Standard;
BO_TX_BU_ 2536767280 : ExBox,Kombi_TT3,ZR_High_Korea,ZR_High_TT3;
BO_TX_BU_ 2536714752 : Kombi_TT3,ZR_High_Korea;
BO_TX_BU_ 2536714753 : Kombi_TT3,ZR_High_Korea;
BO_TX_BU_ 2536714768 : ExBox,ZR_High_TT3;
BO_TX_BU_ 2536714769 : ExBox,ZR_High_TT3;
BO_TX_BU_ 2536712464 : ExBox,ZR_High_TT3;
BO_TX_BU_ 2536712192 : Kombi_TT3,ZR_High_Korea;
BO_TX_BU_ 2536712193 : Kombi_TT3,ZR_High_Korea;
BO_TX_BU_ 2536712208 : ExBox,ZR_High_TT3;
BO_TX_BU_ 2536712209 : ExBox,ZR_High_TT3;
BO_TX_BU_ 1635 : ZR_Entry,ZR_High,ZR_High_Korea,ZR_High_TT3,ZR_MIB_OPTION_ab_Gen3,ZR_MIB_TOP_ab_Gen3,ZR_Standard;
BO_TX_BU_ 2583883781 : ZR_Entry,ZR_High,ZR_High_Korea,ZR_High_TT3,ZR_MIB_OPTION_ab_Gen3,ZR_MIB_TOP_ab_Gen3,ZR_Standard;
BO_TX_BU_ 2617215745 : ABT_1_MIB_ab_Gen3,ABT_1_MQB;
BO_TX_BU_ 2617215746 : ABT_1_MIB_ab_Gen3,ABT_1_MQB;
BO_TX_BU_ 2617215747 : ABT_1_MIB_ab_Gen3,ABT_1_MQB;
BO_TX_BU_ 2617215749 : ABT_1_MIB_ab_Gen3,ABT_1_MQB;
BO_TX_BU_ 2617219584 : ZR_High_Korea,ZR_High_TT3;
BO_TX_BU_ 2617219604 : ZR_Entry,ZR_High,ZR_High_Korea,ZR_High_TT3,ZR_MIB_OPTION_ab_Gen3,ZR_MIB_TOP_ab_Gen3,ZR_Standard;
BO_TX_BU_ 2617219605 : ZR_Entry,ZR_High,ZR_High_Korea,ZR_High_TT3,ZR_MIB_OPTION_ab_Gen3,ZR_MIB_TOP_ab_Gen3,ZR_Standard;
BO_TX_BU_ 2549876238 : ZR_High,ZR_High_Korea,ZR_High_TT3,ZR_MIB_OPTION_ab_Gen3,ZR_MIB_TOP_ab_Gen3,ZR_Standard;
BO_TX_BU_ 2550007310 : ABT_1_MIB_ab_Gen3,ABT_1_MQB;
BO_TX_BU_ 2549876295 : ZR_Entry,ZR_High,ZR_High_Korea,ZR_High_TT3,ZR_MIB_OPTION_ab_Gen3,ZR_MIB_TOP_ab_Gen3,ZR_Standard;
BO_TX_BU_ 2549876278 : ZR_Entry,ZR_High,ZR_High_Korea,ZR_High_TT3,ZR_MIB_OPTION_ab_Gen3,ZR_MIB_TOP_ab_Gen3,ZR_Standard;
BO_TX_BU_ 2549876379 : ZR_High,ZR_MIB_OPTION_ab_Gen3,ZR_MIB_TOP_ab_Gen3,ZR_Standard;
BO_TX_BU_ 2549876381 : ZR_High,ZR_MIB_TOP_ab_Gen3;
BO_TX_BU_ 2549876371 : ZR_High,ZR_MIB_OPTION_ab_Gen3,ZR_MIB_TOP_ab_Gen3,ZR_Standard;
BO_TX_BU_ 1714 : ZR_High,ZR_High_Korea,ZR_MIB_OPTION_ab_Gen3,ZR_MIB_TOP_ab_Gen3;
BO_TX_BU_ 1520 : ZR_Entry,ZR_High,ZR_High_Korea,ZR_High_TT3,ZR_MIB_OPTION_ab_Gen3,ZR_MIB_TOP_ab_Gen3,ZR_Standard;
BO_TX_BU_ 1142 : ABT_1_MIB_ab_Gen3,ABT_1_MQB,DU_1_MQB;
BO_TX_BU_ 1143 : ABT_1_MIB_ab_Gen3,ABT_1_MQB,DU_1_MQB;

CM_ "MIB_MIBCAN_V1.18F Generated by BusNet_NG_Produktiv 9.10.2";
CM_ BU_ ABT_1_MQB "Anzeige Bedienteil 1";
CM_ BU_ BT_1_MQB "Audi MIB key panel";
CM_ BU_ DU_3 "Anzeigeeinheit 3 für Multimediasystem PAG (Display Unit 3 For Multimedia System PAG)";
CM_ BU_ ExBox "Externe Box.
Diese wird nur in der MIB High Korea Variante verwendet.";
CM_ BU_ Kombi_TT3 "Kombiinstrument für Audi TT3";
CM_ BU_ LSR_1 "Lautstärkeregler 1";
CM_ BU_ SCC1 "Drahtloses Bedienteil 1 (SmartControlCarrier 1)";
CM_ BU_ SCC2 "Drahtloses Bedienteil 1 (SmartControlCarrier 2)";
CM_ BU_ SDC1 "Smart Display Carrier (HL)";
CM_ BU_ SDC2 "Smart Display Carrier (HR)";
CM_ BU_ SFA "Sonderfahrzeugassistent (Gateway für die Anbindung von externem Zubehör)";
CM_ BU_ TVTuner_ab_Gen3_JPN "Nachrüstlösung für Markt Japan! 
keine Diagnose! k
ein Teilnehmer von Signal- bzw. Service orientierter Kommunikation; 

Auschließlich Audio-Video Ströme am Zentralrechner!
passives NM am MIBCAN
passiv Empfang Diagnose_01 (Uhrzeit)";
CM_ BU_ WLC_01 "Wireless Charger 1 - Ladegerät 1 für mobile Endgeräte - Charger 1 Mobile Devices";
CM_ BU_ WLC_02 "Wireless Charger 2 - Ladegerät 2 für mobile Endgeräte - Charger 2 Mobile Devices";
CM_ BU_ ZR_High "MIB

Folgende T-Module müssen für die Routing-Matrix exportiert werden.
MLBevo:
	TModul_ZR_Basis_MOST_MLBevo
  	TModul_ZR_MIBCAN
MLB:
	TModul_ZR_Basis_MOST_MLB
	TModul_ZR_MIBCAN";
CM_ BU_ ZR_High_Korea "Korea variante des ZR High mit Exbox

Folgende T-Module müssen für die Routing-Matrix exportiert werden.
MLBevo:
	TModul_ZR_Basis_MOST_MLBevo
  	TModul_ZR_MIBCAN
	TModul_ZR_Korea_BAP
	TModul_ZR_Korea_Basis";
CM_ BU_ ZR_High_TT3 "MIB
ZR High Variante für das TT3 Projekt";
CM_ BU_ ZR_MIB_OPTION_ab_Gen3 "Zentralrechner ab MIB3";
CM_ BU_ ZR_Standard "MIB Standard

Folgende T-Module müssen für die Routing-Matrix exportiert werden.
MLBevo:
	TModul_ZR_Basis_MOST_MLBevo
  	TModul_ZR_MIBCAN
";
CM_ SG_ 2527679645 NFC_MiKo_NFC_Device_gekoppelt "Ein NFC-Device ist im Empfangsbereich und der NFC-Reader hat eine aktive Verbindung aufgebaut.";
CM_ SG_ 2527679645 NFC_MiKo_Laden_unterbrechen "Anforderung seitens Mittelkonsolen-STG das Laden in der Phonebox zu unterbrechen";
CM_ SG_ 2527679645 NFC_MiKo_Fehler "Das Steuergeraet hat einen Fehler und ist nicht komplett einsatzfaehig.";
CM_ SG_ 2527679645 NFC_MiKo_ESM_aktiv "Energiesparmodus ist aktiv, z.B. nach 72h Fahrzeugstillstand";
CM_ SG_ 2583752965 ABT_1_SWDL_Req_Data "Softwaredownload über ISO TP.";
CM_ SG_ 2583884037 ABT_1_SWDL_Resp_Data "Softwaredownload über ISO TP.";
CM_ SG_ 2536716288 BAP_ExBox_ASG_01_Header "Kommunikation Zentralrechner External Box im MIB";
CM_ SG_ 2536716304 BAP_ExBox_FSG_01_Header "Kommunikation Zentralrechner External Box im MIB";
CM_ SG_ 2536712448 BAP_Telefon2_ASG_01_Header "MQB AUDI: keine Verwendung im ZR Entry";
CM_ SG_ 2536712464 BAP_Telefon2_FSG_01_Header "MQB AUDI: keine Verwendung im ZR Entry";
CM_ SG_ 2536712192 BAP_Telefon_ASG_01_Header "MQB AUDI: keine Verwendung im ZR Entry";
CM_ SG_ 2536712193 BAP_Telefon_ASG_02_Header "MQB AUDI: keine Verwendung im ZR Entry";
CM_ SG_ 2536712194 BAP_Telefon_ASG_03_Header "Telefon Anzeigesteuergeraet
Head-Up";
CM_ SG_ 2536712195 BAP_Telefon_ASG_04_Header "Telefon Anzeigesteuergeraet
MMI<->Head-Up Display";
CM_ SG_ 2536712208 BAP_Telefon_FSG_01_Header "MQB AUDI: keine Verwendung im ZR Entry";
CM_ SG_ 2536712209 BAP_Telefon_FSG_02_Header "MQB AUDI: keine Verwendung im ZR Entry";
CM_ SG_ 1139 BT_Variant "Identifiziert die Variante des MMI-Bedienteils";
CM_ SG_ 1139 BT_DKM_Kurzschluss_GND "Drehkinematik Fehler - Rechte oder Linke Seite an GND kurzgeschlossen";
CM_ SG_ 1139 BT_DKM_Kurzschluss_Ubat "Drehkinematik Fehler - Rechte oder Linke Seite an Ubat kurzgeschlossen";
CM_ SG_ 1139 BT_DKM_Unterbrechung "Drehkinematik Fehler- Unterbrechung der Motorleitung
Bürsten abgenutzt; Bedingung: Minimalstrom wird nicht erreicht";
CM_ SG_ 1139 BT_DKM_k_Hallsignal "Drehkinematik Fehler- Mechanik Blockade / kein Hallsignal";
CM_ SG_ 1139 BT_DKM_Ueberlastung "Drehkinematik Fehler- Motor-Übertemperatur
Schwergängigkeit, zu häufige Benutzung";
CM_ SG_ 1139 BT_DKM_Mech_Flauf "Drehkinematik Fehler - Mechanischer Fehler: Gerissenes Seil, Zahnrad lose auf Achse, etc.";
CM_ SG_ 1139 BT_KBD_TP_Fehler "TouchPad Fehler - 
0 kein_Fehler
1 BT_TP_Allgemeiner_Fehler
2 TP_Kommunikations_Fehler
4 TP_Checksum_Fehler
8 TP_Software_inkonsistent
16 BT_TP_Spannungs_Fehler
";
CM_ SG_ 1139 BT_DKM_EL_Fehler "Drehkinematik Fehler - Kurzschluss Motorleitung";
CM_ SG_ 1139 BT_DKM_Manual_Operation "(1) Der Benutzer hat am ausgefahrenen Display gedrückt und die DKM fährt selbsttätig ein. !!! Spec Änderung: Display fährt selber ein !!!
(2) Der Benutzer hat das eingefahrene Display berührt und die DKM fährt selbsttätig aus. !!! Vorhalt für zukünftige ";
CM_ SG_ 1139 BT_LIN1_Unterbrechung "LIN Slave 1 (VolSteller) Fehler- Unterbrechung der Kommunikation; Bedingung: keine Reaktion auf Master-Requests";
CM_ SG_ 1139 BT_LIN2_Unterbrechung "LIN Slave 2 (PresetLeiste) Fehler- Unterbrechung der Kommunikation; Bedingung: keine Reaktion auf Master-Requests";
CM_ SG_ 1139 BT_DKM_Mech_Flauf_2 "Drehkinematik Fehler - Mechanischer Fehler: Gerissenes Seil, Zahnrad lose auf Achse, etc. (für Bentley DKM)";
CM_ BO_ 1635 "DLC=8 ab D4 gültig";
CM_ SG_ 1635 BEM_02_Abschaltstufen "Abschaltstufen des Ruhestrommanagements (Initialisierungswert aus EEprom)

Stufe 0 (keine Einschraenkungen)
Stufe 1 (Abschaltung Hochstromverbraucher)
Stufe 2 (Infotainmentabschaltung)
Stufe 3 (Wake-Up-Sperre)

Für den Transport- und Ruhestrommessm";
CM_ SG_ 1635 BEM_STH_Zielzeit "Maximal mögliche Zeit für den Standheizungsbetrieb, um die Startfähigkeit nicht zu gefährden";
CM_ SG_ 1635 BEM_MMI_Vorwarnung "Anzeige Vorwarnung MMI-Abschaltung (Initialisierungswert aus EEprom)
						 
						  
															  
																																																						  
																												 
				  
					  
																			 
";
CM_ SG_ 1635 BEM_HL_Kontingentierung "Leistungskontingente für Heizsysteme";
CM_ SG_ 1635 NVEM_Freigabe_ZusBatt_Laden "NVEM gibt die Freigabe zum Schließen des Laderelais im Ruhebetrieb (z.B. bei Verwendung eines Ladegerätes)";
CM_ SG_ 1635 NVEM_Anf_SD_schalten "Anforderung Nachlauf für den Steckdosenbetrieb
Initialisierungswert aus EEprom";
CM_ SG_ 1635 BEM_Generatordiagnose "Ansteuerung Generatorwarnleuchte im Kombi
";
CM_ SG_ 1635 BEM_Red_Innengeblaese "Reduzierung Innengebläse
";
CM_ SG_ 1635 BEM_STH_Einschaltverbot "Einschränkung Standheizung/-lüftung durch BEM: Setzt der BEM das Bit, dann darf die Standheizung nicht mehr einschalten
(Die Standheizung muss aber nicht abschalten, sondern darf weiterbrennen)
(Initialisierungswert aus EEprom)
";
CM_ SG_ 1635 BEM_HL_Regelung_Status "Status Regelung Heizleistung
";
CM_ SG_ 1635 BEM_Ladezustand "Ladezustand der Niedervoltbatterie
";
CM_ SG_ 1635 BEM_Batteriediagnose "Anzeige von Textwarnungen";
CM_ SG_ 1635 MIB_Stromsparmodus "Signal beschreibt die Aktivierung für den Stromsparmodus beim MIB.
Bei AUS (= 0) gibt es keine weitere Anforderung an die MIB-Komponenten.
Bei EIN (= 1) werden alle MIB Komponenten in einen Stromsparmodus versetzt.";
CM_ SG_ 1635 BEM_DFM "Generatorauslastungsgrad, vom Generator über LIN an das Gateway gesandt. Das Motorsteuergerät regelt auf dieses Signal die PTC, das Energiemanagement im BSG/BCM kalkuliert die Bordnetzauslastung";
CM_ SG_ 1635 BEM_REK_aktiv "Rekuperationsfreigabe vom Energiemanagement
0x0 = keine Rekuperationsfreigabe
0x1 = Rekuperationsfreigabe";
CM_ SG_ 1635 BEM_EMLIN_ungueltig "Energie-Lin - Signale sind ungültig vom Slave Batteriedatenmodul oder Generator
0 = Signale gültig
1 = Signale ungültig";
CM_ SG_ 1635 BEM_Batt_Ab "Batterieverbindungskontrolle:
0x0: Batterie am Bordnetz
0x1: Batterie ab erkannt";
CM_ SG_ 1635 BEM_UBDM "Batteriespannung, gemessen vom Batteriedatenmodul";
CM_ SG_ 1635 BEM_UGenSoll "Sollspannungsvorgabe an den Generator, beinhaltet temperaturoptimierte Batterieladung und Rekuperation";
CM_ SG_ 1635 BEM_Anf_KL15_schalten "Abschaltempfehlung bzw. Verhinderung der automatischen Abschaltung Kl15 durch das BCM";
CM_ SG_ 1635 NVEM_Batterie_Service "Anforderung einer Batterie-Service - Anzeige / Anforderung an die Werkstatt über MOD";
CM_ SG_ 1635 NVEM_Freigabe_OnlineUpdate "Freigabe für Online-Update durch Energiemanagement";
CM_ SG_ 2583752709 BT_1_SWDL_Req_Data "Softwaredownload über ISO TP.";
CM_ SG_ 2583883781 BT_1_SWDL_Resp_Data "Softwaredownload über ISO TP.";
CM_ SG_ 2617219605 ZR_KL_30F "Gemessene Versorgungsspannung des Zentralrechners.
";
CM_ SG_ 2617219605 ZR_TempSens "Aktueller Temperaturwert des Zentralrechners";
CM_ SG_ 2617219605 MMI_State "Powerstate des Zentralrechners. MMI_Off wird im Zustand dead mode gesendet.";
CM_ SG_ 2617219605 Tel_aktiv "Aktives Telefonat oder mute pin aktiv
";
CM_ SG_ 2617219605 Routeg_aktiv "Routenführung aktiv
";
CM_ SG_ 2617219605 ZR_LastOn "LastOn state des Zentralrechners
";
CM_ SG_ 2617219605 SI_MOST_Status "Das Signal gibt den Zustand des MOST wieder.";
CM_ SG_ 2617219605 ZR_State_DU_1 "Kontrollbit für Display, Hintergrundbeleuchtung aus, Hintergrundbeleuchtung an, Energiesparmodus.
";
CM_ SG_ 2617219605 Tel_SIM_aktiv "SimKarte eingelegt

";
CM_ SG_ 2549880334 DIA_ABT_1_Req_Data "DK2F Flash Diagnosezugriff";
CM_ SG_ 2550011406 DIA_ABT_1_Resp_Data "DK2F Flash Diagnosezugriff";
CM_ BO_ 2549880610 "Drahtloses Bedienteil 1 für Multimediasystem Request Channel";
CM_ BO_ 2550011682 "Drahtloses Bedienteil 1 für Multimediasystem Response Channel";
CM_ BO_ 2549880611 "Drahtloses Bedienteil 2 für Multimediasystem Request Channel";
CM_ BO_ 2550011683 "Drahtloses Bedienteil 2 für Multimediasystem Response Channel";
CM_ BO_ 2549880473 "Anzeingeeinheit 3 für Multimediasystem Request Channel";
CM_ BO_ 2550011545 "Anzeingeeinheit 3 für Multimediasystem Response Channel";
CM_ BO_ 2549880474 "Anzeingeeinheit 4 für Multimediasystem Request Channel";
CM_ BO_ 2550011546 "Anzeingeeinheit 4 für Multimediasystem Response Channel";
CM_ SG_ 2549876238 Diag_ABT_1_Req_Data "Diagnosezugriff DK4Master auf Slave";
CM_ SG_ 2550007310 Diag_ABT_1_Resp_Data "Diagnosezugriff DK4Master auf Slave";
CM_ SG_ 2549876381 Diag_DU_3_Req_Data "Diagnosezugriff DK4Master auf Slave";
CM_ SG_ 2550007453 Diag_DU_3_Resp_Data "Diagnosezugriff DK4Master auf Slave";
CM_ SG_ 2549876382 Diag_DU_4_Req_Data "Diagnosezugriff DK4Master auf Slave";
CM_ SG_ 2550007454 Diag_DU_4_Resp_Data "Diagnosezugriff DK4Master auf Slave";
CM_ SG_ 1714 DGN_Verlernzaehler "wrap around 254 --> 0";
CM_ SG_ 1714 KBI_Kilometerstand "Fehler wird ausgegeben, falls Kilometerstand nicht restaurierbar
";
CM_ SG_ 1714 UH_Monat "0x0D, 0xF =  Werte ungültig
0x0E = Relatives Datum (nur VW)";
CM_ SG_ 1714 UH_Tag "0x0: reserviert bei VW";
CM_ SG_ 1714 UH_Stunde "0x18 - 0x1F = Werte ungültig";
CM_ SG_ 1714 UH_Minute "0x3C- 0x3f = Werte ungültig";
CM_ SG_ 1714 UH_Sekunde "0x3C- 0x3f = Werte ungültig";
CM_ SG_ 1714 Vehicle_Driving_Cycle "Optimierung der Inbetriebnahme von Steuergeräten in einem Teilverbau in der Produktion.
Siehe VW80114. Signal bildet (durch eine Gateway-Funktion) den Inhalt des Signals OBD_Driving_Cycle ab.";
CM_ SG_ 1714 Uhrzeit_01_alt "
";
CM_ BO_ 1520 "ab MQB nach abgestimmten FLH Dimmung";
CM_ SG_ 1520 DI_KL_58xd "Klemme 58xd Display- und Funktionsbeleuchtung
Mit der Klemme 58xd wird die Helligkeit der Display- und der Funktionsbeleuchtungen der Schalter gesteuert.
Im Detail beschrieben im 'Funktionslastenheft Dimmung MQB'.";
CM_ SG_ 1520 DI_KL_58xs "Suchbeleuchtung Schalter
EIN-AUS-Schaltalgorithmus der allgemeinen Schaltersuchbeleuchtung. 
Im Detail beschrieben im 'Funktionslastenheft Dimmung MQB'.
";
CM_ SG_ 1520 DI_Display_Nachtdesign "Für Displays sind oft  automatische Umschaltungen von Tag-/Nachtdesign vorgesehen.
Es gibt jedoch Zustände, an denen auch tagsüber das Abblendlicht eingeschaltet ist.
z.B. Dauerfahrlicht, Geschwindigkeitsabhängiges 'Licht-An-Bei-Autobahn', 'Regenlicht',";
CM_ SG_ 1520 DI_KL_58xt "Timergesteuerte Suchbeleuchtung
Der EIN-AUS-Schaltalgorithmus für die vor- und nachlaufende Schaltersuchbeleuchtungen beim Ein- & Aussteigen; z.B.: Start/Stop-Taster.
Im Detail beschrieben im 'Funktionslastenheft Dimmung MQB'.";
CM_ SG_ 1520 DI_Fotosensor "Helligkeitswert Fotosensor
Für die Dimmung relevanter Wert zur Sensierung der Umgebungshelligkeit
Im Detail beschrieben im 'Funktionslastenheft Dimmung MQB'.";
CM_ SG_ 1520 BCM1_Stellgroesse_Kl_58s "Rohwert Dimmpoti";
CM_ SG_ 1142 DU_State "Power state des Displays.";
CM_ SG_ 1142 DU_Temp_Fehler "Die Display Unit hat einen Temperaturfehler erkannt.";
CM_ SG_ 1142 DU_KL30_Uebersp_Fehler "Display Unit Erkannter Überspannungsfehler";
CM_ SG_ 1142 DU_KL30_Untersp_Fehler "Display Unit Erkannter Unterspannungsfehler";
CM_ SG_ 1142 FB_Mode "Steuergerät ist im Fernbedienmodus";
CM_ SG_ 1142 DU_DispDerating "Begrenzung der Verlustleistung in Abhaengigkeit der Temperatur";
CM_ SG_ 1142 DU_KL_30F "Gemessene Versorgungsspannung des Displays.
";
CM_ SG_ 1142 DU_TempSens "Display Unit aktueller Temperaturwert";
CM_ SG_ 1142 DU_TempSensMax "Gespeicherte maximale Sensortemperatur . Wert bleibt über Ruhestrom erhalten.";
CM_ SG_ 1142 DU_Variant "Variante der Display Unit
siehe MIB_ABT_EEPROM-AdjustDeviceNr_V01E_20100715_woj.xls";
CM_ SG_ 1142 DU_Zulieferer "Zulieferer des Displays.
Je nach eingesetztem Display müssen für das HMI unterschiedliche Grafiken verwendet werden damit die angezeigten Bilder immer identisch aussehen.";
CM_ SG_ 1142 HU_Fotosensor "Messwert Fotosensor der Headunit (PCM bzw. CDR) 
logarithmisch verzerrt (siehe Funktionsbeschreibung Nachtdesign - entsprechend Audi-Spec)
PCM/CDR_Signal";
CM_ SG_ 1143 DU_Betriebsdauer_min "Display Betriebsdauer Minutenanteil";
CM_ SG_ 1143 DU_Betriebsdauer_std "Display Betriebsdauer Stundenanteil";
CM_ SG_ 1143 DU_HintGrdBelKurzschl "Hintergrundbeleuchtung hat einen Kurzschluß.";
CM_ SG_ 1143 DU_HintGrdBelUnterbr "Ueber Strommessungen, mindestens ein LED Strang unterbrochen.";
CM_ SG_ 1143 EEPROM_Fehler "EEPROM Defekt erkannt.";
CM_ SG_ 1143 DU1_SW_inkonsistent "SW_inkonsistent= 1 SW Status ist inkonsistent - Fehler
SW_inkonsistent = 0 kien Fehler - SW ist konsistent";
CM_ SG_ 1143 DU1_HDCP_Status "Aktueller HDCP Status";
CM_ SG_ 1143 LVDS_Status "LVDS_Lock= 1 Statussignal in der DU Ein valides Videosignal zum Anzeigen liegt an 
LVDS_Unlocked = 0 kein Videosignal liegt an ";
CM_ SG_ 1143 ZR_Lenkerpos_Status "Im ABT gespeicherte Lenkradposition. Die Lenkradposition wird wie im Signal ZR_Lenkerposition gesendet nach einer Qualifizierungszeit von voraussichtlich 10 Botschaften übernommen.";
CM_ SG_ 1143 DU1_Touch_Fehlerstatus "Touch_Fehlerstatus = 0 kein Fehler erkannt
Touch_Fehlerstatus = 1 SW Fehler erkannt
Touch_Fehlerstatus = 2 HW Fehler erkannt";
CM_ SG_ 1143 DU1_Haptik_Fehlerstatus "Haptik_Fehlerstatus = 0 kein Fehler erkannt
Haptik_Fehlerstatus = 1 SW Fehler erkannt
Haptik_Fehlerstatus = 2 HW Fehler erkannt";
CM_ SG_ 1143 DU1_LVDS_Splitter_Fehlerstatus "LVDS_Splitter_Fehlerstatus = 0 kein Fehler erkannt
LVDS_Splitter_Fehlerstatus = 1 SW Fehler erkannt
LVDS_Splitter_Fehlerstatus = 2 HW Fehler erkannt";
CM_ SG_ 561 DU1_KS_aktiv_anderer_Grund "DTC Display Unit Komponentenschutz - Aktiv (anderer Grund)";
CM_ SG_ 561 DU1_KS_aktiv_falsche_Auth "DTC Display Unit Komponentenschutz - Aktiv (Falschauthentifikation)";
CM_ SG_ 561 DU1_KS_aktiv_Manipulationsschutz "DTC Display Unit Komponentenschutz - Aktiv (Manipulationsschutz)";
CM_ SG_ 561 DU1_KS_FIS_unplausibel "DTC Display Unit Komponentenschutz - FAZIT-Identifikation unplausibel";
CM_ SG_ 561 DU1_KS_keine_Grundeinstellung "DTC Display Unit Komponentenschutz - keine oder falsche Grundeinstellung";
CM_ SG_ 561 DU1_KS_SHE_keine_Grundeinst "DTC Display Unit Komponentenschutz - SHE-Schlüssel keine oder falsche Grundeinstellung";
CM_ SG_ 561 DU1_Touchstatus "Status if display unit (DU) is touched or not.";
CM_ SG_ 561 DU1_Fehlerstatus "Indicates the error status of the ABT.";
CM_ SG_ 561 DU1_Slider_Locked "Gives Status from ABT slider if slider is locked or unlocked. Signal mapped according to the hard wiring between ABT and DiETa.";
CM_ SG_ 1144 DU2_State "Power state des Displays.";
CM_ SG_ 1144 DU2_Temp_Fehler "Die Display Unit hat einen Temperaturfehler erkannt.";
CM_ SG_ 1144 DU2_KL30_Uebersp_Fehler "Display Unit Erkannter Überspannungsfehler";
CM_ SG_ 1144 DU2_KL30_Untersp_Fehler "Display Unit Erkannter Unterspannungsfehler";
CM_ SG_ 1144 DU2_FB_Mode "Steuergerät ist im Fernbedienmodus";
CM_ SG_ 1144 DU2_DispDerating "Begrenzung der Verlustleistung in Abhaengigkeit der Temperatur";
CM_ SG_ 1144 DU2_KL_30F "Gemessene Versorgungsspannung des Displays.
";
CM_ SG_ 1144 DU2_TempSens "Display Unit aktueller Temperaturwert";
CM_ SG_ 1144 DU2_TempSensMax "Gespeicherte maximale Sensortemperatur . Wert bleibt über Ruhestrom erhalten.";
CM_ SG_ 1144 DU2_Variant "Variante der Display Unit
siehe MIB_ABT_EEPROM-AdjustDeviceNr_V01E_20100715_woj.xls";
CM_ SG_ 1144 DU2_Zulieferer "Zulieferer des Displays.
Je nach eingesetztem Display müssen für das HMI unterschiedliche Grafiken verwendet werden damit die angezeigten Bilder immer identisch aussehen.";
CM_ SG_ 1144 DU2_HU_Fotosensor "Messwert Fotosensor der Headunit (PCM bzw. CDR) 
logarithmisch verzerrt (siehe Funktionsbeschreibung Nachtdesign - entsprechend Audi-Spec)
PCM/CDR_Signal";
CM_ SG_ 1145 DU2_Betriebsdauer_min "Display Betriebsdauer Minutenanteil";
CM_ SG_ 1145 DU2_Betriebsdauer_std "Display Betriebsdauer Stundenanteil";
CM_ SG_ 1145 DU2_HintGrdBelKurzschl "Hintergrundbeleuchtung hat einen Kurzschluß.";
CM_ SG_ 1145 DU2_HintGrdBelUnterbr "Ueber Strommessungen, mindestens ein LED Strang unterbrochen.";
CM_ SG_ 1145 DU2_EEPROM_Fehler "EEPROM Defekt erkannt.";
CM_ SG_ 1145 DU2_SW_inkonsistent "SW_inkonsistent= 1 SW Status ist inkonsistent - Fehler
SW_inkonsistent = 0 kien Fehler - SW ist konsistent";
CM_ SG_ 1145 DU2_HDCP_Status "Aktueller HDCP Status";
CM_ SG_ 1145 DU2_LVDS_Status "LVDS_Lock= 1 Statussignal in der DU Ein valides Videosignal zum Anzeigen liegt an 
LVDS_Unlocked = 0 kein Videosignal liegt an ";
CM_ SG_ 1145 DU2_ZR_Lenkerpos_Status "Im ABT gespeicherte Lenkradposition. Die Lenkradposition wird wie im Signal ZR_Lenkerposition gesendet nach einer Qualifizierungszeit von voraussichtlich 10 Botschaften übernommen.";
CM_ SG_ 1145 DU2_Touch_Fehlerstatus "Touch_Fehlerstatus = 0 kein Fehler erkannt
Touch_Fehlerstatus = 1 SW Fehler erkannt
Touch_Fehlerstatus = 2 HW Fehler erkannt";
CM_ SG_ 1145 DU2_Haptik_Fehlerstatus "Haptik_Fehlerstatus = 0 kein Fehler erkannt
Haptik_Fehlerstatus = 1 SW Fehler erkannt
Haptik_Fehlerstatus = 2 HW Fehler erkannt";
CM_ SG_ 1145 DU2_LVDS_Splitter_Fehlerstatus "LVDS_Splitter_Fehlerstatus = 0 kein Fehler erkannt
LVDS_Splitter_Fehlerstatus = 1 SW Fehler erkannt
LVDS_Splitter_Fehlerstatus = 2 HW Fehler erkannt";
CM_ SG_ 2589283758 DU3_State "Power state des Displays.";
CM_ SG_ 2589283758 DU3_SystemMode "Fehlende Beschreibung (Import)";
CM_ SG_ 2589283758 DU3_Temp_Fehler "Die Display Unit hat einen Temperaturfehler erkannt.";
CM_ SG_ 2589283758 DU3_KL30_Uebersp_Fehler "Display Unit Erkannter Überspannungsfehler";
CM_ SG_ 2589283758 DU3_KL30_Untersp_Fehler "Display Unit Erkannter Unterspannungsfehler";
CM_ SG_ 2589283758 DU3_FB_Mode "Steuergerät ist im Fernbedienmodus";
CM_ SG_ 2589283758 DU3_DispDerating "Begrenzung der Verlustleistung in Abhaengigkeit der Temperatur";
CM_ SG_ 2589283758 DU3_KL_30F "Gemessene Versorgungsspannung des Displays.";
CM_ SG_ 2589283758 DU3_TempSens "Display Unit aktueller Temperaturwert";
CM_ SG_ 2589283758 DU3_TempSensMax "Gespeicherte maximale Sensortemperatur.";
CM_ SG_ 2589283758 DU3_Variant "Variante der Display Unit
siehe MIB_ABT_EEPROM-AdjustDeviceNr_V01E_20100715_woj.xls";
CM_ SG_ 2589283758 DU3_Zulieferer "Zulieferer des Displays.
Je nach eingesetztem Display müssen für das HMI unterschiedliche Grafiken verwendet werden damit die angezeigten Bilder immer identisch aussehen.";
CM_ SG_ 2589283758 DU3_HU_Fotosensor "Messwert Fotosensor der Headunit (PCM bzw. CDR) 
logarithmisch verzerrt (siehe Funktionsbeschreibung Nachtdesign - entsprechend Audi-Spec)
PCM/CDR_Signal";
CM_ SG_ 2589283758 DU3_Schatter_Fehlerstatus "Schatter_Fehlerstatus = 0 kein Fehler erkannt
Schatter_Fehlerstatus = 1 SW Fehler erkannt
Schatter_Fehlerstatus = 2 HW Fehler erkannt";
BA_DEF_  "DBName" STRING ;
BA_DEF_  "GenNWMApBusSleep" STRING ;
BA_DEF_  "GenNWMApCanNormal" STRING ;
BA_DEF_  "GenNWMApCanOff" STRING ;
BA_DEF_  "GenNWMApCanOn" STRING ;
BA_DEF_  "GenNWMApCanSleep" STRING ;
BA_DEF_  "GenNWMApCanWakeUp" STRING ;
BA_DEF_  "GenNWMGotoMode_Awake" STRING ;
BA_DEF_  "GenNWMGotoMode_BusSleep" STRING ;
BA_DEF_  "GenNWMSleepTime" INT 0 1000000;
BA_DEF_  "GenNWMTalkNM" STRING ;
BA_DEF_  "Manufacturer" STRING ;
BA_DEF_  "NmhBaseAddress" HEX 0 536870911;
BA_DEF_  "NmhMessageCount" INT 0 1024;
BA_DEF_  "NmType" STRING ;
BA_DEF_  "VAGTP20_SetupMessageCount" INT 0 255;
BA_DEF_  "VAGTP20_SetupStartAddress" HEX 0 2047;
BA_DEF_  "VersionDay" INT 1 31;
BA_DEF_  "VersionMonth" INT 1 12;
BA_DEF_  "VersionWeek" INT 1 52;
BA_DEF_  "VersionYear" INT 0 99;
BA_DEF_  "VersionNumber" INT 0 65535;
BA_DEF_  "BusType" STRING ;
BA_DEF_  "Baudrate" INT 1 1000000;
BA_DEF_  "SamplePointMin" INT 1 100;
BA_DEF_  "SamplePointMax" INT 1 100;
BA_DEF_  "SyncJumpWidthMin" INT 1 4;
BA_DEF_  "SyncJumpWidthMax" INT 1 4;
BA_DEF_  "NBTMin" INT 1 30;
BA_DEF_  "NBTMax" INT 1 30;
BA_DEF_  "NmhTimeoutTimer" INT 0 65535;
BA_DEF_  "NmhWaitBusSleepTimer" INT 0 65535;
BA_DEF_  "NmhPrepareBusSleepTimer" INT 0 65535;
BA_DEF_  "NmhLongTimer" INT 0 65535;
BA_DEF_  "NmhNStart" INT 0 255;
BA_DEF_ BU_  "GenNodAutoGenDsp" ENUM  "No","Yes";
BA_DEF_ BU_  "GenNodAutoGenSnd" ENUM  "No","Yes";
BA_DEF_ BU_  "GenNodSleepTime" INT 0 1000000;
BA_DEF_ BU_  "ILUsed" ENUM  "No","Yes";
BA_DEF_ BU_  "ECUVariantDefault" ENUM  "No","Yes";
BA_DEF_ BU_  "ECUVariantGroup" STRING ;
BA_DEF_ BU_  "NodeLayerModules" STRING ;
BA_DEF_ BU_  "NmhNode" ENUM  "No","Yes";
BA_DEF_ BU_  "NmNode" ENUM  "No","Yes";
BA_DEF_ BO_  "DiagRequest" ENUM  "No","Yes";
BA_DEF_ BO_  "DiagResponse" ENUM  "No","Yes";
BA_DEF_ BO_  "DiagState" ENUM  "No","Yes";
BA_DEF_ BO_  "GenMsgChkConstant" HEX 0 4095;
BA_DEF_ BO_  "GenMsgCycleTime" INT 0 65535;
BA_DEF_ BO_  "GenMsgCycleTimeFast" INT 0 65535;
BA_DEF_ BO_  "GenMsgDelayTime" INT 0 100000;
BA_DEF_ BO_  "GenMsgILSupport" ENUM  "No","Yes";
BA_DEF_ BO_  "GenMsgNrOfRepetition" INT 0 100;
BA_DEF_ BO_  "GenMsgPDUConstants" STRING ;
BA_DEF_ BO_  "GenMsgSendType" ENUM  "Cyclic","not_used","not_used","not_used","not_used","not_used","not_used","IfActive","NoMsgSendType";
BA_DEF_ BO_  "GenMsgStartDelayTime" INT 0 100000;
BA_DEF_ BO_  "NmMessage" ENUM  "No","Yes";
BA_DEF_ BO_  "NmhMessage" ENUM  "No","Yes";
BA_DEF_ BO_  "MsgType" ENUM  "Application","NM ","NMH","TP2.0","ISO-TP ","BAP","EID","KS";
BA_DEF_ BO_  "VAGTP20_API" HEX 0 255;
BA_DEF_ BO_  "VAGTP20_DynConnection" ENUM  "No","Yes";
BA_DEF_ BO_  "VAGTP20_DynSetup" ENUM  "No","Yes";
BA_DEF_ BO_  "VAGTP20_StatConnection" ENUM  "No","Yes";
BA_DEF_ SG_  "GenSigActiveRepetitions" INT -2147483648 2147483647;
BA_DEF_ SG_  "GenSigInactiveValue" INT -2147483648 2147483647;
BA_DEF_ SG_  "GenSigSendType" ENUM  "Cyclic","OnWrite","OnWriteWithRepetition","OnChange","OnChangeWithRepetition","IfActive","IfActiveWithRepetition","NoSigSendType","OnChangeAndIfActive","OnChangeAndIfActiveWithRepetition";
BA_DEF_ SG_  "GenSigStartValue" INT -2147483648 2147483647;
BA_DEF_ SG_  "NWM-WakeupAllowed" ENUM  "No","Yes";
BA_DEF_ SG_  "GenSigFuncType" ENUM  "NoFunction","MsgCounter","CRC-8","XOR","XOR-2","DatedBit","SW-Kl15","CHK","Constant","Protocol","CRC-8-SAE_J1850","CRC-32","DataLength","DataID","MsgCounter16","SOK-Signatur";
BA_DEF_ SG_  "GenSigSwitchedByIgnition" ENUM  "No","Yes";
BA_DEF_ SG_  "Fehlerwert" HEX 0 2147483647;
BA_DEF_ SG_  "GenSigMissingSourceValue" HEX 0 2147483647;
BA_DEF_REL_ BU_SG_REL_  "GenSigTimeoutTime" INT 0 65535;
BA_DEF_DEF_  "DBName" "";
BA_DEF_DEF_  "GenNWMApBusSleep" "";
BA_DEF_DEF_  "GenNWMApCanNormal" "";
BA_DEF_DEF_  "GenNWMApCanOff" "";
BA_DEF_DEF_  "GenNWMApCanOn" "";
BA_DEF_DEF_  "GenNWMApCanSleep" "";
BA_DEF_DEF_  "GenNWMApCanWakeUp" "";
BA_DEF_DEF_  "GenNWMGotoMode_Awake" "";
BA_DEF_DEF_  "GenNWMGotoMode_BusSleep" "";
BA_DEF_DEF_  "GenNWMSleepTime" 0;
BA_DEF_DEF_  "GenNWMTalkNM" "";
BA_DEF_DEF_  "Manufacturer" "";
BA_DEF_DEF_  "NmhBaseAddress" 0;
BA_DEF_DEF_  "NmhMessageCount" 1;
BA_DEF_DEF_  "NmType" "None";
BA_DEF_DEF_  "VAGTP20_SetupMessageCount" 0;
BA_DEF_DEF_  "VAGTP20_SetupStartAddress" 0;
BA_DEF_DEF_  "VersionDay" 1;
BA_DEF_DEF_  "VersionMonth" 6;
BA_DEF_DEF_  "VersionWeek" 22;
BA_DEF_DEF_  "VersionYear" 18;
BA_DEF_DEF_  "VersionNumber" 0;
BA_DEF_DEF_  "BusType" "";
BA_DEF_DEF_  "Baudrate" 1;
BA_DEF_DEF_  "SamplePointMin" 1;
BA_DEF_DEF_  "SamplePointMax" 1;
BA_DEF_DEF_  "SyncJumpWidthMin" 1;
BA_DEF_DEF_  "SyncJumpWidthMax" 1;
BA_DEF_DEF_  "NBTMin" 10;
BA_DEF_DEF_  "NBTMax" 20;
BA_DEF_DEF_  "NmhTimeoutTimer" 0;
BA_DEF_DEF_  "NmhWaitBusSleepTimer" 0;
BA_DEF_DEF_  "NmhPrepareBusSleepTimer" 0;
BA_DEF_DEF_  "NmhLongTimer" 0;
BA_DEF_DEF_  "NmhNStart" 0;
BA_DEF_DEF_  "GenNodAutoGenDsp" "Yes";
BA_DEF_DEF_  "GenNodAutoGenSnd" "Yes";
BA_DEF_DEF_  "GenNodSleepTime" 0;
BA_DEF_DEF_  "ILUsed" "Yes";
BA_DEF_DEF_  "ECUVariantDefault" "Yes";
BA_DEF_DEF_  "ECUVariantGroup" "";
BA_DEF_DEF_  "NodeLayerModules" "";
BA_DEF_DEF_  "NmhNode" "Yes";
BA_DEF_DEF_  "NmNode" "No";
BA_DEF_DEF_  "DiagRequest" "No";
BA_DEF_DEF_  "DiagResponse" "No";
BA_DEF_DEF_  "DiagState" "No";
BA_DEF_DEF_  "GenMsgChkConstant" 0;
BA_DEF_DEF_  "GenMsgCycleTime" 0;
BA_DEF_DEF_  "GenMsgCycleTimeFast" 0;
BA_DEF_DEF_  "GenMsgDelayTime" 0;
BA_DEF_DEF_  "GenMsgILSupport" "No";
BA_DEF_DEF_  "GenMsgNrOfRepetition" 0;
BA_DEF_DEF_  "GenMsgPDUConstants" "";
BA_DEF_DEF_  "GenMsgSendType" "NoMsgSendType";
BA_DEF_DEF_  "GenMsgStartDelayTime" 0;
BA_DEF_DEF_  "NmMessage" "No";
BA_DEF_DEF_  "NmhMessage" "No";
BA_DEF_DEF_  "MsgType" "Application";
BA_DEF_DEF_  "VAGTP20_API" 0;
BA_DEF_DEF_  "VAGTP20_DynConnection" "No";
BA_DEF_DEF_  "VAGTP20_DynSetup" "No";
BA_DEF_DEF_  "VAGTP20_StatConnection" "No";
BA_DEF_DEF_  "GenSigActiveRepetitions" 0;
BA_DEF_DEF_  "GenSigInactiveValue" 0;
BA_DEF_DEF_  "GenSigSendType" "NoSigSendType";
BA_DEF_DEF_  "GenSigStartValue" 0;
BA_DEF_DEF_  "NWM-WakeupAllowed" "No";
BA_DEF_DEF_  "GenSigFuncType" "NoFunction";
BA_DEF_DEF_  "GenSigSwitchedByIgnition" "Yes";
BA_DEF_DEF_  "Fehlerwert" 0;
BA_DEF_DEF_  "GenSigMissingSourceValue" 0;
BA_DEF_DEF_REL_ "GenSigTimeoutTime" 0;
BA_ "NmhNStart" 20;
BA_ "NmhLongTimer" 200;
BA_ "NmhPrepareBusSleepTimer" 500;
BA_ "NmhWaitBusSleepTimer" 750;
BA_ "NmhTimeoutTimer" 1000;
BA_ "SyncJumpWidthMax" 4;
BA_ "SyncJumpWidthMin" 2;
BA_ "SamplePointMax" 84;
BA_ "SamplePointMin" 80;
BA_ "Baudrate" 500000;
BA_ "BusType" "CAN";
BA_ "VersionNumber" 18;
BA_ "VAGTP20_SetupStartAddress" 512;
BA_ "VAGTP20_SetupMessageCount" 128;
BA_ "NmType" "NM-High";
BA_ "NmhMessageCount" 256;
BA_ "NmhBaseAddress" 452984832;
BA_ "Manufacturer" "VAG";
BA_ "GenNWMTalkNM" "Nmh_ReqNetOn()";
BA_ "GenNWMSleepTime" 4000;
BA_ "GenNWMGotoMode_BusSleep" "Nmh_ReqNetOff()";
BA_ "GenNWMGotoMode_Awake" "Nmh_ReqNetOn()";
BA_ "GenNWMApCanWakeUp" "apCanWakeUp()";
BA_ "GenNWMApCanSleep" "apCanSleep()";
BA_ "GenNWMApCanOn" "NMIndnetOn()";
BA_ "GenNWMApCanOff" "NMIndnetOff()";
BA_ "GenNWMApCanNormal" "apCanNormal()";
BA_ "GenNWMApBusSleep" "NMIndNetSDN()";
BA_ "DBName" "MIB_MIBCAN";
BA_ "NodeLayerModules" BU_ ABT_1_MIB_ab_Gen3 "NMHigh.DLL";
BA_ "GenNodSleepTime" BU_ ABT_1_MIB_ab_Gen3 4000;
BA_ "NodeLayerModules" BU_ ABT_1_MQB "NMHigh.DLL";
BA_ "ECUVariantGroup" BU_ ABT_1_MQB "ABT";
BA_ "GenNodSleepTime" BU_ ABT_1_MQB 4000;
BA_ "NmhNode" BU_ BAP_Tester 0;
BA_ "ECUVariantGroup" BU_ BAP_Tester "BAP";
BA_ "GenNodSleepTime" BU_ BAP_Tester 4000;
BA_ "NodeLayerModules" BU_ BT_1_MQB "NMHigh.DLL";
BA_ "ECUVariantGroup" BU_ BT_1_MQB "ABT";
BA_ "ECUVariantDefault" BU_ BT_1_MQB 0;
BA_ "GenNodSleepTime" BU_ BT_1_MQB 4000;
BA_ "NodeLayerModules" BU_ DU_1_MQB "NMHigh.DLL";
BA_ "ECUVariantGroup" BU_ DU_1_MQB "ABT";
BA_ "ECUVariantDefault" BU_ DU_1_MQB 0;
BA_ "GenNodSleepTime" BU_ DU_1_MQB 4000;
BA_ "NodeLayerModules" BU_ DU_2 "NMHigh.DLL";
BA_ "GenNodSleepTime" BU_ DU_2 4000;
BA_ "NodeLayerModules" BU_ DU_3 "NMHigh.DLL";
BA_ "GenNodSleepTime" BU_ DU_3 4000;
BA_ "NodeLayerModules" BU_ DU_4 "NMHigh.DLL";
BA_ "GenNodSleepTime" BU_ DU_4 4000;
BA_ "NodeLayerModules" BU_ ExBox "NMHigh.DLL";
BA_ "ECUVariantGroup" BU_ ExBox "ABT";
BA_ "GenNodSleepTime" BU_ ExBox 4000;
BA_ "NodeLayerModules" BU_ Kombi_TT3 "NMHigh.DLL";
BA_ "ECUVariantGroup" BU_ Kombi_TT3 "Kombi";
BA_ "ECUVariantDefault" BU_ Kombi_TT3 0;
BA_ "GenNodSleepTime" BU_ Kombi_TT3 4000;
BA_ "NodeLayerModules" BU_ LSR_1 "NMHigh.DLL";
BA_ "GenNodSleepTime" BU_ LSR_1 4000;
BA_ "NodeLayerModules" BU_ SCC1 "NMHigh.DLL";
BA_ "ECUVariantGroup" BU_ SCC1 "SCC1";
BA_ "ECUVariantDefault" BU_ SCC1 0;
BA_ "GenNodSleepTime" BU_ SCC1 4000;
BA_ "NodeLayerModules" BU_ SCC2 "NMHigh.DLL";
BA_ "GenNodSleepTime" BU_ SCC2 4000;
BA_ "NodeLayerModules" BU_ SDC1 "NMHigh.DLL";
BA_ "GenNodSleepTime" BU_ SDC1 4000;
BA_ "NodeLayerModules" BU_ SDC2 "NMHigh.DLL";
BA_ "GenNodSleepTime" BU_ SDC2 4000;
BA_ "NodeLayerModules" BU_ SFA "NMHigh.DLL";
BA_ "ECUVariantGroup" BU_ SFA "SFA";
BA_ "GenNodSleepTime" BU_ SFA 4000;
BA_ "GenNodSleepTime" BU_ TVTuner_ab_Gen3_JPN 4000;
BA_ "NodeLayerModules" BU_ WLC_01 "NMHigh.DLL";
BA_ "GenNodSleepTime" BU_ WLC_01 4000;
BA_ "NodeLayerModules" BU_ WLC_02 "NMHigh.DLL";
BA_ "GenNodSleepTime" BU_ WLC_02 4000;
BA_ "NodeLayerModules" BU_ ZR_Entry "NMHigh.DLL";
BA_ "ECUVariantGroup" BU_ ZR_Entry "ZR";
BA_ "ECUVariantDefault" BU_ ZR_Entry 0;
BA_ "GenNodSleepTime" BU_ ZR_Entry 4000;
BA_ "NodeLayerModules" BU_ ZR_High "NMHigh.DLL";
BA_ "ECUVariantGroup" BU_ ZR_High "ZR";
BA_ "GenNodSleepTime" BU_ ZR_High 4000;
BA_ "NodeLayerModules" BU_ ZR_High_Korea "NMHigh.DLL";
BA_ "ECUVariantGroup" BU_ ZR_High_Korea "ZR";
BA_ "ECUVariantDefault" BU_ ZR_High_Korea 0;
BA_ "GenNodSleepTime" BU_ ZR_High_Korea 4000;
BA_ "NodeLayerModules" BU_ ZR_High_TT3 "NMHigh.DLL";
BA_ "ECUVariantGroup" BU_ ZR_High_TT3 "ZR";
BA_ "ECUVariantDefault" BU_ ZR_High_TT3 0;
BA_ "GenNodSleepTime" BU_ ZR_High_TT3 4000;
BA_ "NodeLayerModules" BU_ ZR_MIB_OPTION_ab_Gen3 "NMHigh.DLL";
BA_ "ECUVariantGroup" BU_ ZR_MIB_OPTION_ab_Gen3 "ZR";
BA_ "ECUVariantDefault" BU_ ZR_MIB_OPTION_ab_Gen3 0;
BA_ "GenNodSleepTime" BU_ ZR_MIB_OPTION_ab_Gen3 4000;
BA_ "NodeLayerModules" BU_ ZR_MIB_TOP_ab_Gen3 "NMHigh.DLL";
BA_ "ECUVariantGroup" BU_ ZR_MIB_TOP_ab_Gen3 "ZR";
BA_ "ECUVariantDefault" BU_ ZR_MIB_TOP_ab_Gen3 0;
BA_ "GenNodSleepTime" BU_ ZR_MIB_TOP_ab_Gen3 4000;
BA_ "NodeLayerModules" BU_ ZR_Standard "NMHigh.DLL";
BA_ "ECUVariantGroup" BU_ ZR_Standard "ZR";
BA_ "ECUVariantDefault" BU_ ZR_Standard 0;
BA_ "GenNodSleepTime" BU_ ZR_Standard 4000;
BA_ "GenMsgSendType" BO_ 2527679645 0;
BA_ "GenMsgILSupport" BO_ 2527679645 1;
BA_ "GenMsgCycleTime" BO_ 2527679645 200;
BA_ "MsgType" BO_ 2583752965 4;
BA_ "MsgType" BO_ 2583884037 4;
BA_ "MsgType" BO_ 2536714496 5;
BA_ "GenMsgSendType" BO_ 2536714496 7;
BA_ "GenMsgCycleTimeFast" BO_ 2536714496 30;
BA_ "MsgType" BO_ 2536714497 5;
BA_ "GenMsgSendType" BO_ 2536714497 7;
BA_ "GenMsgCycleTimeFast" BO_ 2536714497 50;
BA_ "MsgType" BO_ 2536714512 5;
BA_ "GenMsgSendType" BO_ 2536714512 7;
BA_ "GenMsgCycleTimeFast" BO_ 2536714512 30;
BA_ "GenMsgCycleTime" BO_ 2536714512 1000;
BA_ "MsgType" BO_ 2536714513 5;
BA_ "GenMsgSendType" BO_ 2536714513 7;
BA_ "GenMsgCycleTimeFast" BO_ 2536714513 10;
BA_ "GenMsgCycleTime" BO_ 2536714513 1000;
BA_ "MsgType" BO_ 2536767264 5;
BA_ "MsgType" BO_ 2536767280 5;
BA_ "MsgType" BO_ 2536716288 5;
BA_ "GenMsgSendType" BO_ 2536716288 7;
BA_ "GenMsgCycleTimeFast" BO_ 2536716288 80;
BA_ "MsgType" BO_ 2536716304 5;
BA_ "GenMsgSendType" BO_ 2536716304 7;
BA_ "GenMsgCycleTimeFast" BO_ 2536716304 50;
BA_ "GenMsgCycleTime" BO_ 2536716304 1000;
BA_ "MsgType" BO_ 2536715264 5;
BA_ "GenMsgSendType" BO_ 2536715264 7;
BA_ "GenMsgCycleTimeFast" BO_ 2536715264 80;
BA_ "MsgType" BO_ 2536715280 5;
BA_ "GenMsgSendType" BO_ 2536715280 7;
BA_ "GenMsgCycleTimeFast" BO_ 2536715280 50;
BA_ "GenMsgCycleTime" BO_ 2536715280 1000;
BA_ "MsgType" BO_ 2536714752 5;
BA_ "GenMsgSendType" BO_ 2536714752 7;
BA_ "GenMsgCycleTimeFast" BO_ 2536714752 30;
BA_ "MsgType" BO_ 2536714753 5;
BA_ "GenMsgSendType" BO_ 2536714753 7;
BA_ "GenMsgCycleTimeFast" BO_ 2536714753 50;
BA_ "MsgType" BO_ 2536714754 5;
BA_ "GenMsgSendType" BO_ 2536714754 7;
BA_ "GenMsgCycleTimeFast" BO_ 2536714754 30;
BA_ "MsgType" BO_ 2536714755 5;
BA_ "GenMsgSendType" BO_ 2536714755 7;
BA_ "GenMsgCycleTimeFast" BO_ 2536714755 50;
BA_ "MsgType" BO_ 2536714768 5;
BA_ "GenMsgSendType" BO_ 2536714768 7;
BA_ "GenMsgCycleTimeFast" BO_ 2536714768 30;
BA_ "GenMsgCycleTime" BO_ 2536714768 1000;
BA_ "MsgType" BO_ 2536714769 5;
BA_ "GenMsgSendType" BO_ 2536714769 7;
BA_ "GenMsgCycleTimeFast" BO_ 2536714769 10;
BA_ "GenMsgCycleTime" BO_ 2536714769 1000;
BA_ "MsgType" BO_ 2536712448 5;
BA_ "GenMsgSendType" BO_ 2536712448 7;
BA_ "GenMsgCycleTimeFast" BO_ 2536712448 80;
BA_ "MsgType" BO_ 2536712464 5;
BA_ "GenMsgSendType" BO_ 2536712464 7;
BA_ "GenMsgCycleTimeFast" BO_ 2536712464 50;
BA_ "GenMsgCycleTime" BO_ 2536712464 1000;
BA_ "MsgType" BO_ 2536712192 5;
BA_ "GenMsgSendType" BO_ 2536712192 7;
BA_ "GenMsgCycleTimeFast" BO_ 2536712192 30;
BA_ "MsgType" BO_ 2536712193 5;
BA_ "GenMsgSendType" BO_ 2536712193 7;
BA_ "GenMsgCycleTimeFast" BO_ 2536712193 50;
BA_ "MsgType" BO_ 2536712194 5;
BA_ "GenMsgSendType" BO_ 2536712194 7;
BA_ "GenMsgCycleTimeFast" BO_ 2536712194 30;
BA_ "MsgType" BO_ 2536712195 5;
BA_ "GenMsgSendType" BO_ 2536712195 7;
BA_ "GenMsgCycleTimeFast" BO_ 2536712195 50;
BA_ "MsgType" BO_ 2536712208 5;
BA_ "GenMsgSendType" BO_ 2536712208 7;
BA_ "GenMsgCycleTimeFast" BO_ 2536712208 30;
BA_ "GenMsgCycleTime" BO_ 2536712208 1000;
BA_ "MsgType" BO_ 2536712209 5;
BA_ "GenMsgSendType" BO_ 2536712209 7;
BA_ "GenMsgCycleTimeFast" BO_ 2536712209 10;
BA_ "GenMsgCycleTime" BO_ 2536712209 1000;
BA_ "GenMsgSendType" BO_ 1139 0;
BA_ "GenMsgILSupport" BO_ 1139 1;
BA_ "GenMsgDelayTime" BO_ 1139 40;
BA_ "GenMsgCycleTime" BO_ 1139 1000;
BA_ "GenMsgSendType" BO_ 1635 0;
BA_ "GenMsgILSupport" BO_ 1635 1;
BA_ "GenMsgCycleTime" BO_ 1635 100;
BA_ "MsgType" BO_ 2583752709 4;
BA_ "MsgType" BO_ 2583883781 4;
BA_ "MsgType" BO_ 2617215754 6;
BA_ "MsgType" BO_ 2617215755 6;
BA_ "MsgType" BO_ 2617215756 6;
BA_ "MsgType" BO_ 2617215757 6;
BA_ "MsgType" BO_ 2617215744 6;
BA_ "MsgType" BO_ 2617215748 6;
BA_ "MsgType" BO_ 2617215745 6;
BA_ "MsgType" BO_ 2617215746 6;
BA_ "MsgType" BO_ 2617215747 6;
BA_ "MsgType" BO_ 2617215749 6;
BA_ "MsgType" BO_ 2617213696 6;
BA_ "MsgType" BO_ 2617213697 6;
BA_ "MsgType" BO_ 2617213698 6;
BA_ "MsgType" BO_ 2617213699 6;
BA_ "MsgType" BO_ 2617213700 6;
BA_ "MsgType" BO_ 2617217792 6;
BA_ "MsgType" BO_ 2617217795 6;
BA_ "MsgType" BO_ 2617217796 6;
BA_ "MsgType" BO_ 2617217798 6;
BA_ "MsgType" BO_ 2617217799 6;
BA_ "MsgType" BO_ 2617217800 6;
BA_ "MsgType" BO_ 2617217801 6;
BA_ "MsgType" BO_ 2617217802 6;
BA_ "MsgType" BO_ 2617217803 6;
BA_ "MsgType" BO_ 2617217804 6;
BA_ "MsgType" BO_ 2617217797 6;
BA_ "MsgType" BO_ 2617217793 6;
BA_ "MsgType" BO_ 2617217794 6;
BA_ "MsgType" BO_ 2617217805 6;
BA_ "MsgType" BO_ 2617217806 6;
BA_ "MsgType" BO_ 2617217807 6;
BA_ "MsgType" BO_ 2617217808 6;
BA_ "MsgType" BO_ 2617217809 6;
BA_ "MsgType" BO_ 2617217810 6;
BA_ "MsgType" BO_ 2617217811 6;
BA_ "MsgType" BO_ 2617223936 6;
BA_ "MsgType" BO_ 2617223939 6;
BA_ "MsgType" BO_ 2617223940 6;
BA_ "MsgType" BO_ 2617223942 6;
BA_ "MsgType" BO_ 2617223943 6;
BA_ "MsgType" BO_ 2617223944 6;
BA_ "MsgType" BO_ 2617223945 6;
BA_ "MsgType" BO_ 2617223946 6;
BA_ "MsgType" BO_ 2617223947 6;
BA_ "MsgType" BO_ 2617223948 6;
BA_ "MsgType" BO_ 2617223941 6;
BA_ "MsgType" BO_ 2617223937 6;
BA_ "MsgType" BO_ 2617223938 6;
BA_ "MsgType" BO_ 2617223949 6;
BA_ "MsgType" BO_ 2617223950 6;
BA_ "MsgType" BO_ 2617223951 6;
BA_ "MsgType" BO_ 2617223952 6;
BA_ "MsgType" BO_ 2617223953 6;
BA_ "MsgType" BO_ 2617223954 6;
BA_ "MsgType" BO_ 2617223955 6;
BA_ "MsgType" BO_ 2617152256 6;
BA_ "MsgType" BO_ 2617152257 6;
BA_ "MsgType" BO_ 2617152258 6;
BA_ "MsgType" BO_ 2617070336 6;
BA_ "MsgType" BO_ 2617070337 6;
BA_ "MsgType" BO_ 2617070338 6;
BA_ "MsgType" BO_ 2617072384 6;
BA_ "MsgType" BO_ 2617072385 6;
BA_ "MsgType" BO_ 2617072386 6;
BA_ "MsgType" BO_ 2617064192 6;
BA_ "MsgType" BO_ 2617064193 6;
BA_ "MsgType" BO_ 2617064194 6;
BA_ "MsgType" BO_ 2617066240 6;
BA_ "MsgType" BO_ 2617066241 6;
BA_ "MsgType" BO_ 2617066242 6;
BA_ "MsgType" BO_ 2617219597 6;
BA_ "MsgType" BO_ 2617219584 6;
BA_ "MsgType" BO_ 2617219604 6;
BA_ "MsgType" BO_ 2617219605 6;
BA_ "GenMsgILSupport" BO_ 2617219605 1;
BA_ "GenMsgDelayTime" BO_ 2617219605 40;
BA_ "GenMsgCycleTime" BO_ 2617219605 1000;
BA_ "MsgType" BO_ 2549880334 4;
BA_ "DiagRequest" BO_ 2549880334 1;
BA_ "MsgType" BO_ 2550011406 4;
BA_ "DiagResponse" BO_ 2550011406 1;
BA_ "MsgType" BO_ 2549880610 4;
BA_ "MsgType" BO_ 2550011682 4;
BA_ "MsgType" BO_ 2549880611 4;
BA_ "MsgType" BO_ 2550011683 4;
BA_ "MsgType" BO_ 2549880473 4;
BA_ "DiagRequest" BO_ 2549880473 1;
BA_ "MsgType" BO_ 2550011545 4;
BA_ "DiagResponse" BO_ 2550011545 1;
BA_ "MsgType" BO_ 2549880474 4;
BA_ "DiagRequest" BO_ 2549880474 1;
BA_ "MsgType" BO_ 2550011546 4;
BA_ "DiagResponse" BO_ 2550011546 1;
BA_ "MsgType" BO_ 2549876238 4;
BA_ "DiagRequest" BO_ 2549876238 1;
BA_ "MsgType" BO_ 2550007310 4;
BA_ "DiagResponse" BO_ 2550007310 1;
BA_ "MsgType" BO_ 2549876295 4;
BA_ "DiagRequest" BO_ 2549876295 1;
BA_ "MsgType" BO_ 2550007367 4;
BA_ "DiagResponse" BO_ 2550007367 1;
BA_ "MsgType" BO_ 2549876278 4;
BA_ "DiagRequest" BO_ 2549876278 1;
BA_ "MsgType" BO_ 2550007350 4;
BA_ "DiagResponse" BO_ 2550007350 1;
BA_ "MsgType" BO_ 2549876379 4;
BA_ "DiagRequest" BO_ 2549876379 1;
BA_ "MsgType" BO_ 2550007451 4;
BA_ "DiagResponse" BO_ 2550007451 1;
BA_ "MsgType" BO_ 2549876381 4;
BA_ "DiagRequest" BO_ 2549876381 1;
BA_ "MsgType" BO_ 2550007453 4;
BA_ "DiagResponse" BO_ 2550007453 1;
BA_ "MsgType" BO_ 2549876371 4;
BA_ "DiagRequest" BO_ 2549876371 1;
BA_ "MsgType" BO_ 2550007443 4;
BA_ "DiagResponse" BO_ 2550007443 1;
BA_ "GenMsgSendType" BO_ 1714 0;
BA_ "GenMsgILSupport" BO_ 1714 1;
BA_ "GenMsgCycleTime" BO_ 1714 1000;
BA_ "GenMsgSendType" BO_ 1520 0;
BA_ "GenMsgILSupport" BO_ 1520 1;
BA_ "GenMsgDelayTime" BO_ 1520 50;
BA_ "GenMsgCycleTime" BO_ 1520 200;
BA_ "GenMsgSendType" BO_ 1142 0;
BA_ "GenMsgILSupport" BO_ 1142 1;
BA_ "GenMsgDelayTime" BO_ 1142 40;
BA_ "GenMsgCycleTime" BO_ 1142 1000;
BA_ "GenMsgSendType" BO_ 1143 0;
BA_ "GenMsgILSupport" BO_ 1143 1;
BA_ "GenMsgDelayTime" BO_ 1143 40;
BA_ "GenMsgCycleTime" BO_ 1143 1000;
BA_ "GenMsgSendType" BO_ 561 0;
BA_ "GenMsgILSupport" BO_ 561 1;
BA_ "GenMsgDelayTime" BO_ 561 20;
BA_ "GenMsgCycleTime" BO_ 561 200;
BA_ "GenMsgSendType" BO_ 1144 0;
BA_ "GenMsgILSupport" BO_ 1144 1;
BA_ "GenMsgDelayTime" BO_ 1144 40;
BA_ "GenMsgCycleTime" BO_ 1144 1000;
BA_ "GenMsgSendType" BO_ 1145 0;
BA_ "GenMsgILSupport" BO_ 1145 1;
BA_ "GenMsgDelayTime" BO_ 1145 40;
BA_ "GenMsgCycleTime" BO_ 1145 1000;
BA_ "GenMsgSendType" BO_ 2589283758 0;
BA_ "GenMsgILSupport" BO_ 2589283758 1;
BA_ "GenMsgDelayTime" BO_ 2589283758 40;
BA_ "GenMsgCycleTime" BO_ 2589283758 1000;
BA_ "GenSigSendType" SG_ 2549940736 OBDC_Funktionaler_Req_All_Data 3;
BA_ "GenSigFuncType" SG_ 2549940736 OBDC_Funktionaler_Req_All_Data 9;
BA_ "GenSigSwitchedByIgnition" SG_ 2549940736 OBDC_Funktionaler_Req_All_Data 0;
BA_ "GenSigSwitchedByIgnition" SG_ 2527679645 NFC_MiKo_NFC_Device_gekoppelt 0;
BA_ "GenSigSendType" SG_ 2527679645 NFC_MiKo_NFC_Device_gekoppelt 0;
BA_ "GenSigSwitchedByIgnition" SG_ 2527679645 NFC_MiKo_Laden_unterbrechen 0;
BA_ "GenSigSendType" SG_ 2527679645 NFC_MiKo_Laden_unterbrechen 0;
BA_ "GenSigSwitchedByIgnition" SG_ 2527679645 NFC_MiKo_Fehler 0;
BA_ "GenSigSendType" SG_ 2527679645 NFC_MiKo_Fehler 0;
BA_ "GenSigSwitchedByIgnition" SG_ 2527679645 NFC_MiKo_ESM_aktiv 0;
BA_ "GenSigSendType" SG_ 2527679645 NFC_MiKo_ESM_aktiv 0;
BA_ "GenSigSwitchedByIgnition" SG_ 2583752965 ABT_1_SWDL_Req_Data 0;
BA_ "GenSigSwitchedByIgnition" SG_ 2583884037 ABT_1_SWDL_Resp_Data 0;
BA_ "GenSigFuncType" SG_ 2583884037 ABT_1_SWDL_Resp_Data 9;
BA_ "GenSigSwitchedByIgnition" SG_ 2536714496 BAP_Audio_ASG_01_Header 0;
BA_ "GenSigSendType" SG_ 2536714496 BAP_Audio_ASG_01_Header 3;
BA_ "GenSigSwitchedByIgnition" SG_ 2536714497 BAP_Audio_ASG_02_Header 0;
BA_ "GenSigSendType" SG_ 2536714497 BAP_Audio_ASG_02_Header 3;
BA_ "GenSigSwitchedByIgnition" SG_ 2536714512 BAP_Audio_FSG_01_Header 0;
BA_ "GenSigSendType" SG_ 2536714512 BAP_Audio_FSG_01_Header 3;
BA_ "GenSigSwitchedByIgnition" SG_ 2536714513 BAP_Audio_FSG_02_Header 0;
BA_ "GenSigSendType" SG_ 2536714513 BAP_Audio_FSG_02_Header 3;
BA_ "GenSigSwitchedByIgnition" SG_ 2536767264 BAP_Debug_Cmd 0;
BA_ "GenSigSendType" SG_ 2536767264 BAP_Debug_Cmd 3;
BA_ "GenSigSwitchedByIgnition" SG_ 2536767280 BAP_Debug_Data 0;
BA_ "GenSigSendType" SG_ 2536767280 BAP_Debug_Data 3;
BA_ "GenSigSwitchedByIgnition" SG_ 2536716288 BAP_ExBox_ASG_01_Header 0;
BA_ "GenSigSendType" SG_ 2536716288 BAP_ExBox_ASG_01_Header 3;
BA_ "GenSigSwitchedByIgnition" SG_ 2536716304 BAP_ExBox_FSG_01_Header 0;
BA_ "GenSigSendType" SG_ 2536716304 BAP_ExBox_FSG_01_Header 3;
BA_ "GenSigSwitchedByIgnition" SG_ 2536715264 BAP_MFL_ASG_01_Header 0;
BA_ "GenSigSendType" SG_ 2536715264 BAP_MFL_ASG_01_Header 3;
BA_ "GenSigSwitchedByIgnition" SG_ 2536715280 BAP_MFL_FSG_01_Header 0;
BA_ "GenSigSendType" SG_ 2536715280 BAP_MFL_FSG_01_Header 3;
BA_ "GenSigSwitchedByIgnition" SG_ 2536714752 BAP_Navigation_ASG_01_Header 0;
BA_ "GenSigSendType" SG_ 2536714752 BAP_Navigation_ASG_01_Header 3;
BA_ "GenSigSwitchedByIgnition" SG_ 2536714753 BAP_Navigation_ASG_02_Header 0;
BA_ "GenSigSendType" SG_ 2536714753 BAP_Navigation_ASG_02_Header 3;
BA_ "GenSigSwitchedByIgnition" SG_ 2536714754 BAP_Navigation_ASG_03_Header 0;
BA_ "GenSigSendType" SG_ 2536714754 BAP_Navigation_ASG_03_Header 3;
BA_ "GenSigSwitchedByIgnition" SG_ 2536714755 BAP_Navigation_ASG_04_Header 0;
BA_ "GenSigSendType" SG_ 2536714755 BAP_Navigation_ASG_04_Header 3;
BA_ "GenSigSwitchedByIgnition" SG_ 2536714768 BAP_Navigation_FSG_01_Header 0;
BA_ "GenSigSendType" SG_ 2536714768 BAP_Navigation_FSG_01_Header 3;
BA_ "GenSigSwitchedByIgnition" SG_ 2536714769 BAP_Navigation_FSG_02_Header 0;
BA_ "GenSigSendType" SG_ 2536714769 BAP_Navigation_FSG_02_Header 3;
BA_ "GenSigSwitchedByIgnition" SG_ 2536712448 BAP_Telefon2_ASG_01_Header 0;
BA_ "GenSigSendType" SG_ 2536712448 BAP_Telefon2_ASG_01_Header 3;
BA_ "GenSigSwitchedByIgnition" SG_ 2536712464 BAP_Telefon2_FSG_01_Header 0;
BA_ "GenSigSendType" SG_ 2536712464 BAP_Telefon2_FSG_01_Header 3;
BA_ "GenSigSwitchedByIgnition" SG_ 2536712192 BAP_Telefon_ASG_01_Header 0;
BA_ "GenSigSendType" SG_ 2536712192 BAP_Telefon_ASG_01_Header 3;
BA_ "GenSigSwitchedByIgnition" SG_ 2536712193 BAP_Telefon_ASG_02_Header 0;
BA_ "GenSigSendType" SG_ 2536712193 BAP_Telefon_ASG_02_Header 3;
BA_ "GenSigSwitchedByIgnition" SG_ 2536712194 BAP_Telefon_ASG_03_Header 0;
BA_ "GenSigSendType" SG_ 2536712194 BAP_Telefon_ASG_03_Header 3;
BA_ "GenSigSwitchedByIgnition" SG_ 2536712195 BAP_Telefon_ASG_04_Header 0;
BA_ "GenSigSendType" SG_ 2536712195 BAP_Telefon_ASG_04_Header 3;
BA_ "GenSigSwitchedByIgnition" SG_ 2536712208 BAP_Telefon_FSG_01_Header 0;
BA_ "GenSigSendType" SG_ 2536712208 BAP_Telefon_FSG_01_Header 3;
BA_ "GenSigSwitchedByIgnition" SG_ 2536712209 BAP_Telefon_FSG_02_Header 0;
BA_ "GenSigSendType" SG_ 2536712209 BAP_Telefon_FSG_02_Header 3;
BA_ "GenSigSwitchedByIgnition" SG_ 1139 BT_Variant 0;
BA_ "GenSigSendType" SG_ 1139 BT_Variant 0;
BA_ "GenSigSwitchedByIgnition" SG_ 1139 SystemMode 0;
BA_ "GenSigSendType" SG_ 1139 SystemMode 3;
BA_ "Fehlerwert" SG_ 1139 BT_DKM_Kurzschluss_GND 1;
BA_ "GenSigSwitchedByIgnition" SG_ 1139 BT_DKM_Kurzschluss_GND 0;
BA_ "GenSigSendType" SG_ 1139 BT_DKM_Kurzschluss_GND 3;
BA_ "Fehlerwert" SG_ 1139 BT_DKM_Kurzschluss_Ubat 1;
BA_ "GenSigSwitchedByIgnition" SG_ 1139 BT_DKM_Kurzschluss_Ubat 0;
BA_ "GenSigSendType" SG_ 1139 BT_DKM_Kurzschluss_Ubat 3;
BA_ "Fehlerwert" SG_ 1139 BT_DKM_Unterbrechung 1;
BA_ "GenSigSwitchedByIgnition" SG_ 1139 BT_DKM_Unterbrechung 0;
BA_ "GenSigSendType" SG_ 1139 BT_DKM_Unterbrechung 3;
BA_ "Fehlerwert" SG_ 1139 BT_DKM_k_Hallsignal 1;
BA_ "GenSigSwitchedByIgnition" SG_ 1139 BT_DKM_k_Hallsignal 0;
BA_ "GenSigSendType" SG_ 1139 BT_DKM_k_Hallsignal 3;
BA_ "Fehlerwert" SG_ 1139 BT_DKM_Ueberlastung 1;
BA_ "GenSigSwitchedByIgnition" SG_ 1139 BT_DKM_Ueberlastung 0;
BA_ "GenSigSendType" SG_ 1139 BT_DKM_Ueberlastung 3;
BA_ "Fehlerwert" SG_ 1139 BT_DKM_Mech_Flauf 1;
BA_ "GenSigSwitchedByIgnition" SG_ 1139 BT_DKM_Mech_Flauf 0;
BA_ "GenSigSendType" SG_ 1139 BT_DKM_Mech_Flauf 3;
BA_ "GenSigSwitchedByIgnition" SG_ 1139 BT_KBD_TP_Fehler 0;
BA_ "GenSigSendType" SG_ 1139 BT_KBD_TP_Fehler 3;
BA_ "Fehlerwert" SG_ 1139 BT_DKM_EL_Fehler 1;
BA_ "GenSigSwitchedByIgnition" SG_ 1139 BT_DKM_EL_Fehler 0;
BA_ "GenSigSendType" SG_ 1139 BT_DKM_EL_Fehler 3;
BA_ "GenSigSwitchedByIgnition" SG_ 1139 BT_DKM_Manual_Operation 0;
BA_ "GenSigSendType" SG_ 1139 BT_DKM_Manual_Operation 3;
BA_ "Fehlerwert" SG_ 1139 BT_LIN1_Unterbrechung 1;
BA_ "GenSigSwitchedByIgnition" SG_ 1139 BT_LIN1_Unterbrechung 0;
BA_ "GenSigSendType" SG_ 1139 BT_LIN1_Unterbrechung 3;
BA_ "Fehlerwert" SG_ 1139 BT_LIN2_Unterbrechung 1;
BA_ "GenSigSwitchedByIgnition" SG_ 1139 BT_LIN2_Unterbrechung 0;
BA_ "GenSigSendType" SG_ 1139 BT_LIN2_Unterbrechung 3;
BA_ "Fehlerwert" SG_ 1139 BT_DKM_Mech_Flauf_2 1;
BA_ "GenSigSwitchedByIgnition" SG_ 1139 BT_DKM_Mech_Flauf_2 0;
BA_ "GenSigSendType" SG_ 1139 BT_DKM_Mech_Flauf_2 3;
BA_ "GenSigSwitchedByIgnition" SG_ 1635 BEM_02_Abschaltstufen 0;
BA_ "GenSigSendType" SG_ 1635 BEM_02_Abschaltstufen 0;
BA_ "Fehlerwert" SG_ 1635 BEM_STH_Zielzeit 15;
BA_ "GenSigSwitchedByIgnition" SG_ 1635 BEM_STH_Zielzeit 0;
BA_ "GenSigStartValue" SG_ 1635 BEM_STH_Zielzeit 14;
BA_ "GenSigSendType" SG_ 1635 BEM_STH_Zielzeit 0;
BA_ "GenSigSwitchedByIgnition" SG_ 1635 BEM_MMI_Vorwarnung 0;
BA_ "GenSigSendType" SG_ 1635 BEM_MMI_Vorwarnung 0;
BA_ "GenSigSwitchedByIgnition" SG_ 1635 BEM_HL_Kontingentierung 0;
BA_ "GenSigSendType" SG_ 1635 BEM_HL_Kontingentierung 0;
BA_ "GenSigSwitchedByIgnition" SG_ 1635 NVEM_Freigabe_ZusBatt_Laden 0;
BA_ "GenSigSendType" SG_ 1635 NVEM_Freigabe_ZusBatt_Laden 0;
BA_ "GenSigSwitchedByIgnition" SG_ 1635 NVEM_Anf_SD_schalten 0;
BA_ "GenSigSendType" SG_ 1635 NVEM_Anf_SD_schalten 0;
BA_ "GenSigSwitchedByIgnition" SG_ 1635 BEM_Generatordiagnose 0;
BA_ "GenSigSendType" SG_ 1635 BEM_Generatordiagnose 0;
BA_ "GenSigSwitchedByIgnition" SG_ 1635 BEM_Red_Innengeblaese 0;
BA_ "GenSigSendType" SG_ 1635 BEM_Red_Innengeblaese 0;
BA_ "GenSigSwitchedByIgnition" SG_ 1635 BEM_STH_Einschaltverbot 0;
BA_ "GenSigSendType" SG_ 1635 BEM_STH_Einschaltverbot 0;
BA_ "GenSigSwitchedByIgnition" SG_ 1635 BEM_HL_Regelung_Status 0;
BA_ "GenSigSendType" SG_ 1635 BEM_HL_Regelung_Status 0;
BA_ "Fehlerwert" SG_ 1635 BEM_Ladezustand 15;
BA_ "GenSigSwitchedByIgnition" SG_ 1635 BEM_Ladezustand 0;
BA_ "GenSigStartValue" SG_ 1635 BEM_Ladezustand 14;
BA_ "GenSigSendType" SG_ 1635 BEM_Ladezustand 0;
BA_ "Fehlerwert" SG_ 1635 BEM_Batteriediagnose 7;
BA_ "GenSigSwitchedByIgnition" SG_ 1635 BEM_Batteriediagnose 0;
BA_ "GenSigSendType" SG_ 1635 BEM_Batteriediagnose 0;
BA_ "GenSigSwitchedByIgnition" SG_ 1635 MIB_Stromsparmodus 0;
BA_ "GenSigSendType" SG_ 1635 MIB_Stromsparmodus 0;
BA_ "GenSigSwitchedByIgnition" SG_ 1635 BEM_DFM 0;
BA_ "GenSigSendType" SG_ 1635 BEM_DFM 0;
BA_ "GenSigSwitchedByIgnition" SG_ 1635 BEM_REK_aktiv 0;
BA_ "GenSigSendType" SG_ 1635 BEM_REK_aktiv 0;
BA_ "GenSigSwitchedByIgnition" SG_ 1635 BEM_EMLIN_ungueltig 0;
BA_ "GenSigSendType" SG_ 1635 BEM_EMLIN_ungueltig 0;
BA_ "GenSigSwitchedByIgnition" SG_ 1635 BEM_Batt_Ab 0;
BA_ "GenSigSendType" SG_ 1635 BEM_Batt_Ab 0;
BA_ "Fehlerwert" SG_ 1635 BEM_UBDM 255;
BA_ "GenSigSwitchedByIgnition" SG_ 1635 BEM_UBDM 0;
BA_ "GenSigSendType" SG_ 1635 BEM_UBDM 0;
BA_ "GenSigSwitchedByIgnition" SG_ 1635 BEM_UGenSoll 0;
BA_ "GenSigSendType" SG_ 1635 BEM_UGenSoll 0;
BA_ "GenSigSwitchedByIgnition" SG_ 1635 BEM_Anf_KL15_schalten 0;
BA_ "GenSigSendType" SG_ 1635 BEM_Anf_KL15_schalten 0;
BA_ "GenSigSwitchedByIgnition" SG_ 1635 NVEM_Batterie_Service 0;
BA_ "GenSigSendType" SG_ 1635 NVEM_Batterie_Service 0;
BA_ "GenSigSwitchedByIgnition" SG_ 1635 NVEM_Freigabe_OnlineUpdate 0;
BA_ "GenSigSendType" SG_ 1635 NVEM_Freigabe_OnlineUpdate 0;
BA_ "GenSigSwitchedByIgnition" SG_ 2583752709 BT_1_SWDL_Req_Data 0;
BA_ "GenSigSendType" SG_ 2583752709 BT_1_SWDL_Req_Data 3;
BA_ "GenSigSwitchedByIgnition" SG_ 2583883781 BT_1_SWDL_Resp_Data 0;
BA_ "GenSigFuncType" SG_ 2583883781 BT_1_SWDL_Resp_Data 9;
BA_ "GenSigSendType" SG_ 2583883781 BT_1_SWDL_Resp_Data 3;
BA_ "GenSigSwitchedByIgnition" SG_ 2617215754 DEV_ABT_1_Gen3_Tx_01_Data 0;
BA_ "GenSigSwitchedByIgnition" SG_ 2617215755 DEV_ABT_1_Gen3_Tx_02_Data 0;
BA_ "GenSigSwitchedByIgnition" SG_ 2617215756 DEV_ABT_1_Gen3_Tx_03_Data 0;
BA_ "GenSigSwitchedByIgnition" SG_ 2617215757 DEV_ABT_1_Gen3_Tx_04_Data 0;
BA_ "GenSigSwitchedByIgnition" SG_ 2617215744 DEV_ABT_1_Req_00 0;
BA_ "GenSigSwitchedByIgnition" SG_ 2617215748 DEV_ABT_1_Req_04_Data 0;
BA_ "GenSigSwitchedByIgnition" SG_ 2617215745 DEV_ABT_1_Resp_01 0;
BA_ "GenSigSwitchedByIgnition" SG_ 2617215746 DEV_ABT_1_Resp_02 0;
BA_ "GenSigSwitchedByIgnition" SG_ 2617215747 DEV_ABT_1_Resp_03 0;
BA_ "GenSigSwitchedByIgnition" SG_ 2617215749 DEV_ABT_1_Resp_04_Data 0;
BA_ "GenSigSwitchedByIgnition" SG_ 2617213696 DEV_BT_1_Req_01 0;
BA_ "GenSigSwitchedByIgnition" SG_ 2617213697 DEV_BT_1_Resp_01 0;
BA_ "GenSigSwitchedByIgnition" SG_ 2617213698 DEV_BT_1_Tx_00 0;
BA_ "GenSigSwitchedByIgnition" SG_ 2617213699 DEV_BT_1_Tx_01 0;
BA_ "GenSigSwitchedByIgnition" SG_ 2617213700 DEV_BT_1_Tx_02 0;
BA_ "GenSigSwitchedByIgnition" SG_ 2617217792 DEV_DU_1_Req_00_Data 0;
BA_ "GenSigSwitchedByIgnition" SG_ 2617217795 DEV_DU_1_Req_01_Data 0;
BA_ "GenSigSwitchedByIgnition" SG_ 2617217796 DEV_DU_1_Req_02_Data 0;
BA_ "GenSigSwitchedByIgnition" SG_ 2617217798 DEV_DU_1_Req_03_Data 0;
BA_ "GenSigSwitchedByIgnition" SG_ 2617217799 DEV_DU_1_Req_04_Data 0;
BA_ "GenSigSwitchedByIgnition" SG_ 2617217800 DEV_DU_1_Req_05_Data 0;
BA_ "GenSigSwitchedByIgnition" SG_ 2617217801 DEV_DU_1_Req_06_Data 0;
BA_ "GenSigSwitchedByIgnition" SG_ 2617217802 DEV_DU_1_Req_07_Data 0;
BA_ "GenSigSwitchedByIgnition" SG_ 2617217803 DEV_DU_1_Req_08_Data 0;
BA_ "GenSigSwitchedByIgnition" SG_ 2617217804 DEV_DU_1_Req_09_Data 0;
BA_ "GenSigSwitchedByIgnition" SG_ 2617217797 DEV_DU_1_Resp_00_Data 0;
BA_ "GenSigSwitchedByIgnition" SG_ 2617217793 DEV_DU_1_Resp_01_Data 0;
BA_ "GenSigSwitchedByIgnition" SG_ 2617217794 DEV_DU_1_Resp_02_Data 0;
BA_ "GenSigSwitchedByIgnition" SG_ 2617217805 DEV_DU_1_Resp_03_Data 0;
BA_ "GenSigSwitchedByIgnition" SG_ 2617217806 DEV_DU_1_Resp_04_Data 0;
BA_ "GenSigSwitchedByIgnition" SG_ 2617217807 DEV_DU_1_Resp_05_Data 0;
BA_ "GenSigSwitchedByIgnition" SG_ 2617217808 DEV_DU_1_Resp_06_Data 0;
BA_ "GenSigSwitchedByIgnition" SG_ 2617217809 DEV_DU_1_Resp_07_Data 0;
BA_ "GenSigSwitchedByIgnition" SG_ 2617217810 DEV_DU_1_Resp_08_Data 0;
BA_ "GenSigSwitchedByIgnition" SG_ 2617217811 DEV_DU_1_Resp_09_Data 0;
BA_ "GenSigSwitchedByIgnition" SG_ 2617223936 DEV_DU_2_Req_00_Data 0;
BA_ "GenSigSwitchedByIgnition" SG_ 2617223939 DEV_DU_2_Req_01_Data 0;
BA_ "GenSigSwitchedByIgnition" SG_ 2617223940 DEV_DU_2_Req_02_Data 0;
BA_ "GenSigSwitchedByIgnition" SG_ 2617223942 DEV_DU_2_Req_03_Data 0;
BA_ "GenSigSwitchedByIgnition" SG_ 2617223943 DEV_DU_2_Req_04_Data 0;
BA_ "GenSigSwitchedByIgnition" SG_ 2617223944 DEV_DU_2_Req_05_Data 0;
BA_ "GenSigSwitchedByIgnition" SG_ 2617223945 DEV_DU_2_Req_06_Data 0;
BA_ "GenSigSwitchedByIgnition" SG_ 2617223946 DEV_DU_2_Req_07_Data 0;
BA_ "GenSigSwitchedByIgnition" SG_ 2617223947 DEV_DU_2_Req_08_Data 0;
BA_ "GenSigSwitchedByIgnition" SG_ 2617223948 DEV_DU_2_Req_09_Data 0;
BA_ "GenSigSwitchedByIgnition" SG_ 2617223941 DEV_DU_2_Resp_00_Data 0;
BA_ "GenSigSwitchedByIgnition" SG_ 2617223937 DEV_DU_2_Resp_01_Data 0;
BA_ "GenSigSwitchedByIgnition" SG_ 2617223938 DEV_DU_2_Resp_02_Data 0;
BA_ "GenSigSwitchedByIgnition" SG_ 2617223949 DEV_DU_2_Resp_03_Data 0;
BA_ "GenSigSwitchedByIgnition" SG_ 2617223950 DEV_DU_2_Resp_04_Data 0;
BA_ "GenSigSwitchedByIgnition" SG_ 2617223951 DEV_DU_2_Resp_05_Data 0;
BA_ "GenSigSwitchedByIgnition" SG_ 2617223952 DEV_DU_2_Resp_06_Data 0;
BA_ "GenSigSwitchedByIgnition" SG_ 2617223953 DEV_DU_2_Resp_07_Data 0;
BA_ "GenSigSwitchedByIgnition" SG_ 2617223954 DEV_DU_2_Resp_08_Data 0;
BA_ "GenSigSwitchedByIgnition" SG_ 2617223955 DEV_DU_2_Resp_09_Data 0;
BA_ "GenSigSwitchedByIgnition" SG_ 2617152256 DEV_LSR_1_Req_01 0;
BA_ "GenSigSwitchedByIgnition" SG_ 2617152257 DEV_LSR_1_Resp_01 0;
BA_ "GenSigSwitchedByIgnition" SG_ 2617152258 DEV_LSR_1_Resp_02 0;
BA_ "GenSigSwitchedByIgnition" SG_ 2617070336 DEV_SCC_01_Req_00 0;
BA_ "GenSigSwitchedByIgnition" SG_ 2617070337 DEV_SCC1_Resp_01 0;
BA_ "GenSigSwitchedByIgnition" SG_ 2617070338 DEV_SCC1_Resp_02 0;
BA_ "GenSigSwitchedByIgnition" SG_ 2617072384 DEV_SCC2_Req_00 0;
BA_ "GenSigSwitchedByIgnition" SG_ 2617072385 DEV_SCC2_Resp_01 0;
BA_ "GenSigSwitchedByIgnition" SG_ 2617072386 DEV_SCC2_Resp_02 0;
BA_ "GenSigSwitchedByIgnition" SG_ 2617064192 DEV_SDC1_Req_00 0;
BA_ "GenSigSwitchedByIgnition" SG_ 2617064193 DEV_SDC1_Resp_01 0;
BA_ "GenSigSwitchedByIgnition" SG_ 2617064194 DEV_SDC1_Resp_02 0;
BA_ "GenSigSwitchedByIgnition" SG_ 2617066240 DEV_SDC2_Req_00 0;
BA_ "GenSigSwitchedByIgnition" SG_ 2617066241 DEV_SDC2_Resp_01 0;
BA_ "GenSigSwitchedByIgnition" SG_ 2617066242 DEV_SDC2_Resp_02 0;
BA_ "GenSigSwitchedByIgnition" SG_ 2617219597 DEV_ZR_Req_0D_Data 0;
BA_ "GenSigSwitchedByIgnition" SG_ 2617219584 DEV_ZR_Resp_00_Data 0;
BA_ "GenSigSwitchedByIgnition" SG_ 2617219604 DEV_ZR_Tx_14_Data 0;
BA_ "Fehlerwert" SG_ 2617219605 ZR_KL_30F 255;
BA_ "GenSigSwitchedByIgnition" SG_ 2617219605 ZR_KL_30F 0;
BA_ "GenSigStartValue" SG_ 2617219605 ZR_KL_30F 254;
BA_ "GenSigSendType" SG_ 2617219605 ZR_KL_30F 0;
BA_ "Fehlerwert" SG_ 2617219605 ZR_TempSens 255;
BA_ "GenSigSwitchedByIgnition" SG_ 2617219605 ZR_TempSens 0;
BA_ "GenSigStartValue" SG_ 2617219605 ZR_TempSens 254;
BA_ "GenSigSendType" SG_ 2617219605 ZR_TempSens 0;
BA_ "GenSigSwitchedByIgnition" SG_ 2617219605 Reset_Counter 0;
BA_ "GenSigStartValue" SG_ 2617219605 Reset_Counter 254;
BA_ "GenSigSendType" SG_ 2617219605 Reset_Counter 0;
BA_ "GenSigSwitchedByIgnition" SG_ 2617219605 MMI_State 0;
BA_ "GenSigSendType" SG_ 2617219605 MMI_State 3;
BA_ "GenSigSwitchedByIgnition" SG_ 2617219605 Tel_aktiv 0;
BA_ "GenSigSendType" SG_ 2617219605 Tel_aktiv 3;
BA_ "GenSigSwitchedByIgnition" SG_ 2617219605 Routeg_aktiv 0;
BA_ "GenSigSendType" SG_ 2617219605 Routeg_aktiv 3;
BA_ "GenSigSwitchedByIgnition" SG_ 2617219605 ZR_LastOn 0;
BA_ "GenSigStartValue" SG_ 2617219605 ZR_LastOn 7;
BA_ "GenSigSendType" SG_ 2617219605 ZR_LastOn 3;
BA_ "GenSigSwitchedByIgnition" SG_ 2617219605 SI_MOST_Status 0;
BA_ "GenSigSendType" SG_ 2617219605 SI_MOST_Status 3;
BA_ "GenSigSwitchedByIgnition" SG_ 2617219605 ZR_State_DU_1 0;
BA_ "GenSigSendType" SG_ 2617219605 ZR_State_DU_1 3;
BA_ "GenSigSwitchedByIgnition" SG_ 2617219605 Tel_SIM_aktiv 0;
BA_ "GenSigSendType" SG_ 2617219605 Tel_SIM_aktiv 3;
BA_ "GenSigSwitchedByIgnition" SG_ 2617219605 DEV_ZR_Tx_15_Data 0;
BA_ "GenSigSwitchedByIgnition" SG_ 2549880334 DIA_ABT_1_Req_Data 0;
BA_ "GenSigFuncType" SG_ 2549880334 DIA_ABT_1_Req_Data 9;
BA_ "GenSigSendType" SG_ 2549880334 DIA_ABT_1_Req_Data 3;
BA_ "GenSigSwitchedByIgnition" SG_ 2550011406 DIA_ABT_1_Resp_Data 0;
BA_ "GenSigFuncType" SG_ 2550011406 DIA_ABT_1_Resp_Data 9;
BA_ "GenSigSendType" SG_ 2550011406 DIA_ABT_1_Resp_Data 3;
BA_ "GenSigSwitchedByIgnition" SG_ 2549880610 DIA_SCON1_Req_Data 0;
BA_ "GenSigFuncType" SG_ 2549880610 DIA_SCON1_Req_Data 9;
BA_ "GenSigSwitchedByIgnition" SG_ 2550011682 DIA_SCON1_Resp_Data 0;
BA_ "GenSigFuncType" SG_ 2550011682 DIA_SCON1_Resp_Data 9;
BA_ "GenSigSwitchedByIgnition" SG_ 2549880611 DIA_SCON2_Req_Data 0;
BA_ "GenSigFuncType" SG_ 2549880611 DIA_SCON2_Req_Data 9;
BA_ "GenSigSwitchedByIgnition" SG_ 2550011683 DIA_SCON2_Resp_Data 0;
BA_ "GenSigFuncType" SG_ 2550011683 DIA_SCON2_Resp_Data 9;
BA_ "GenSigSwitchedByIgnition" SG_ 2549880473 DIA_SD3_Req_Data 0;
BA_ "GenSigFuncType" SG_ 2549880473 DIA_SD3_Req_Data 9;
BA_ "GenSigSwitchedByIgnition" SG_ 2550011545 DIA_SD3_Resp_Data 0;
BA_ "GenSigFuncType" SG_ 2550011545 DIA_SD3_Resp_Data 9;
BA_ "GenSigSwitchedByIgnition" SG_ 2549880474 DIA_SD4_Req_Data 0;
BA_ "GenSigFuncType" SG_ 2549880474 DIA_SD4_Req_Data 9;
BA_ "GenSigSwitchedByIgnition" SG_ 2550011546 DIA_SD4_Resp_Data 0;
BA_ "GenSigFuncType" SG_ 2550011546 DIA_SD4_Resp_Data 9;
BA_ "GenSigSwitchedByIgnition" SG_ 2549876238 Diag_ABT_1_Req_Data 0;
BA_ "GenSigSendType" SG_ 2549876238 Diag_ABT_1_Req_Data 3;
BA_ "GenSigSwitchedByIgnition" SG_ 2550007310 Diag_ABT_1_Resp_Data 0;
BA_ "GenSigSendType" SG_ 2550007310 Diag_ABT_1_Resp_Data 3;
BA_ "GenSigSwitchedByIgnition" SG_ 2549876295 Diag_BT_1_Req_Data 0;
BA_ "GenSigSendType" SG_ 2549876295 Diag_BT_1_Req_Data 3;
BA_ "GenSigSwitchedByIgnition" SG_ 2550007367 Diag_BT_1_Resp_Data 0;
BA_ "GenSigSendType" SG_ 2550007367 Diag_BT_1_Resp_Data 3;
BA_ "GenSigSwitchedByIgnition" SG_ 2549876278 Diag_DU_1_Req_Data 0;
BA_ "GenSigFuncType" SG_ 2549876278 Diag_DU_1_Req_Data 9;
BA_ "GenSigSendType" SG_ 2549876278 Diag_DU_1_Req_Data 3;
BA_ "GenSigSwitchedByIgnition" SG_ 2550007350 Diag_DU_1_Resp_Data 0;
BA_ "GenSigSendType" SG_ 2550007350 Diag_DU_1_Resp_Data 3;
BA_ "GenSigSwitchedByIgnition" SG_ 2549876379 Diag_DU_2_Req_Data 0;
BA_ "GenSigFuncType" SG_ 2549876379 Diag_DU_2_Req_Data 9;
BA_ "GenSigSwitchedByIgnition" SG_ 2550007451 Diag_DU_2_Resp_Data 0;
BA_ "GenSigSwitchedByIgnition" SG_ 2549876381 Diag_DU_3_Req_Data 0;
BA_ "GenSigSwitchedByIgnition" SG_ 2550007453 Diag_DU_3_Resp_Data 0;
BA_ "GenSigSwitchedByIgnition" SG_ 2549876382 Diag_DU_4_Req_Data 0;
BA_ "GenSigSendType" SG_ 2549876382 Diag_DU_4_Req_Data 3;
BA_ "GenSigSwitchedByIgnition" SG_ 2550007454 Diag_DU_4_Resp_Data 0;
BA_ "GenSigSendType" SG_ 2550007454 Diag_DU_4_Resp_Data 3;
BA_ "GenSigSwitchedByIgnition" SG_ 2549876371 Diag_LSR_1_Req_Data 0;
BA_ "GenSigFuncType" SG_ 2549876371 Diag_LSR_1_Req_Data 9;
BA_ "GenSigSwitchedByIgnition" SG_ 2550007443 Diag_LSR_1_Resp_Data 0;
BA_ "GenSigFuncType" SG_ 2550007443 Diag_LSR_1_Resp_Data 9;
BA_ "GenSigSwitchedByIgnition" SG_ 1714 DGN_Verlernzaehler 0;
BA_ "GenSigSendType" SG_ 1714 DGN_Verlernzaehler 0;
BA_ "Fehlerwert" SG_ 1714 KBI_Kilometerstand 1048575;
BA_ "GenSigSwitchedByIgnition" SG_ 1714 KBI_Kilometerstand 0;
BA_ "GenSigStartValue" SG_ 1714 KBI_Kilometerstand 1048574;
BA_ "GenSigSendType" SG_ 1714 KBI_Kilometerstand 0;
BA_ "GenSigSwitchedByIgnition" SG_ 1714 UH_Jahr 0;
BA_ "GenSigSendType" SG_ 1714 UH_Jahr 0;
BA_ "Fehlerwert" SG_ 1714 UH_Monat 15;
BA_ "GenSigSwitchedByIgnition" SG_ 1714 UH_Monat 0;
BA_ "GenSigSendType" SG_ 1714 UH_Monat 0;
BA_ "GenSigSwitchedByIgnition" SG_ 1714 UH_Tag 0;
BA_ "GenSigSendType" SG_ 1714 UH_Tag 0;
BA_ "GenSigSwitchedByIgnition" SG_ 1714 UH_Stunde 0;
BA_ "GenSigSendType" SG_ 1714 UH_Stunde 0;
BA_ "GenSigSwitchedByIgnition" SG_ 1714 UH_Minute 0;
BA_ "GenSigSendType" SG_ 1714 UH_Minute 0;
BA_ "GenSigSwitchedByIgnition" SG_ 1714 UH_Sekunde 0;
BA_ "GenSigSendType" SG_ 1714 UH_Sekunde 0;
BA_ "GenSigSwitchedByIgnition" SG_ 1714 Vehicle_Driving_Cycle 0;
BA_ "GenSigSendType" SG_ 1714 Vehicle_Driving_Cycle 0;
BA_ "GenSigSwitchedByIgnition" SG_ 1714 Kombi_02_alt 0;
BA_ "GenSigFuncType" SG_ 1714 Kombi_02_alt 5;
BA_ "GenSigStartValue" SG_ 1714 Kombi_02_alt 1;
BA_ "GenSigSendType" SG_ 1714 Kombi_02_alt 0;
BA_ "GenSigSwitchedByIgnition" SG_ 1714 Uhrzeit_01_alt 0;
BA_ "GenSigFuncType" SG_ 1714 Uhrzeit_01_alt 5;
BA_ "GenSigStartValue" SG_ 1714 Uhrzeit_01_alt 1;
BA_ "GenSigSendType" SG_ 1714 Uhrzeit_01_alt 0;
BA_ "Fehlerwert" SG_ 1520 DI_KL_58xd 255;
BA_ "GenSigSwitchedByIgnition" SG_ 1520 DI_KL_58xd 0;
BA_ "GenSigStartValue" SG_ 1520 DI_KL_58xd 254;
BA_ "GenSigSendType" SG_ 1520 DI_KL_58xd 3;
BA_ "Fehlerwert" SG_ 1520 DI_KL_58xs 127;
BA_ "GenSigSwitchedByIgnition" SG_ 1520 DI_KL_58xs 0;
BA_ "GenSigStartValue" SG_ 1520 DI_KL_58xs 126;
BA_ "GenSigSendType" SG_ 1520 DI_KL_58xs 3;
BA_ "GenSigSwitchedByIgnition" SG_ 1520 DI_Display_Nachtdesign 0;
BA_ "GenSigSendType" SG_ 1520 DI_Display_Nachtdesign 3;
BA_ "Fehlerwert" SG_ 1520 DI_KL_58xt 127;
BA_ "GenSigSwitchedByIgnition" SG_ 1520 DI_KL_58xt 0;
BA_ "GenSigStartValue" SG_ 1520 DI_KL_58xt 126;
BA_ "GenSigSendType" SG_ 1520 DI_KL_58xt 3;
BA_ "GenSigSwitchedByIgnition" SG_ 1520 DI_Fotosensor 0;
BA_ "GenSigSendType" SG_ 1520 DI_Fotosensor 3;
BA_ "Fehlerwert" SG_ 1520 BCM1_Stellgroesse_Kl_58s 127;
BA_ "GenSigSwitchedByIgnition" SG_ 1520 BCM1_Stellgroesse_Kl_58s 0;
BA_ "GenSigStartValue" SG_ 1520 BCM1_Stellgroesse_Kl_58s 126;
BA_ "GenSigSendType" SG_ 1520 BCM1_Stellgroesse_Kl_58s 3;
BA_ "GenSigSwitchedByIgnition" SG_ 1142 DU_State 0;
BA_ "GenSigSendType" SG_ 1142 DU_State 3;
BA_ "GenSigSwitchedByIgnition" SG_ 1142 SystemMode 0;
BA_ "GenSigSendType" SG_ 1142 SystemMode 3;
BA_ "Fehlerwert" SG_ 1142 DU_Temp_Fehler 1;
BA_ "GenSigSwitchedByIgnition" SG_ 1142 DU_Temp_Fehler 0;
BA_ "GenSigSendType" SG_ 1142 DU_Temp_Fehler 3;
BA_ "Fehlerwert" SG_ 1142 DU_KL30_Uebersp_Fehler 1;
BA_ "GenSigSwitchedByIgnition" SG_ 1142 DU_KL30_Uebersp_Fehler 0;
BA_ "GenSigSendType" SG_ 1142 DU_KL30_Uebersp_Fehler 3;
BA_ "Fehlerwert" SG_ 1142 DU_KL30_Untersp_Fehler 1;
BA_ "GenSigSwitchedByIgnition" SG_ 1142 DU_KL30_Untersp_Fehler 0;
BA_ "GenSigSendType" SG_ 1142 DU_KL30_Untersp_Fehler 3;
BA_ "GenSigSwitchedByIgnition" SG_ 1142 FB_Mode 0;
BA_ "GenSigSendType" SG_ 1142 FB_Mode 3;
BA_ "Fehlerwert" SG_ 1142 DU_DispDerating 255;
BA_ "GenSigSwitchedByIgnition" SG_ 1142 DU_DispDerating 0;
BA_ "GenSigStartValue" SG_ 1142 DU_DispDerating 254;
BA_ "GenSigSendType" SG_ 1142 DU_DispDerating 0;
BA_ "Fehlerwert" SG_ 1142 DU_KL_30F 255;
BA_ "GenSigSwitchedByIgnition" SG_ 1142 DU_KL_30F 0;
BA_ "GenSigStartValue" SG_ 1142 DU_KL_30F 254;
BA_ "GenSigSendType" SG_ 1142 DU_KL_30F 0;
BA_ "Fehlerwert" SG_ 1142 DU_TempSens 255;
BA_ "GenSigSwitchedByIgnition" SG_ 1142 DU_TempSens 0;
BA_ "GenSigStartValue" SG_ 1142 DU_TempSens 254;
BA_ "GenSigSendType" SG_ 1142 DU_TempSens 0;
BA_ "Fehlerwert" SG_ 1142 DU_TempSensMax 255;
BA_ "GenSigSwitchedByIgnition" SG_ 1142 DU_TempSensMax 0;
BA_ "GenSigStartValue" SG_ 1142 DU_TempSensMax 254;
BA_ "GenSigSendType" SG_ 1142 DU_TempSensMax 0;
BA_ "GenSigSwitchedByIgnition" SG_ 1142 DU_Variant 0;
BA_ "GenSigStartValue" SG_ 1142 DU_Variant 254;
BA_ "GenSigSendType" SG_ 1142 DU_Variant 0;
BA_ "GenSigSwitchedByIgnition" SG_ 1142 DU_Zulieferer 0;
BA_ "GenSigSendType" SG_ 1142 DU_Zulieferer 0;
BA_ "Fehlerwert" SG_ 1142 HU_Fotosensor 511;
BA_ "GenSigSwitchedByIgnition" SG_ 1142 HU_Fotosensor 0;
BA_ "GenSigStartValue" SG_ 1142 HU_Fotosensor 510;
BA_ "GenSigSendType" SG_ 1142 HU_Fotosensor 0;
BA_ "Fehlerwert" SG_ 1143 DU_Betriebsdauer_min 255;
BA_ "GenSigSwitchedByIgnition" SG_ 1143 DU_Betriebsdauer_min 0;
BA_ "GenSigStartValue" SG_ 1143 DU_Betriebsdauer_min 254;
BA_ "GenSigSendType" SG_ 1143 DU_Betriebsdauer_min 0;
BA_ "Fehlerwert" SG_ 1143 DU_Betriebsdauer_std 65535;
BA_ "GenSigSwitchedByIgnition" SG_ 1143 DU_Betriebsdauer_std 0;
BA_ "GenSigStartValue" SG_ 1143 DU_Betriebsdauer_std 65534;
BA_ "GenSigSendType" SG_ 1143 DU_Betriebsdauer_std 0;
BA_ "Fehlerwert" SG_ 1143 DU_HintGrdBelKurzschl 1;
BA_ "GenSigSwitchedByIgnition" SG_ 1143 DU_HintGrdBelKurzschl 0;
BA_ "GenSigSendType" SG_ 1143 DU_HintGrdBelKurzschl 3;
BA_ "Fehlerwert" SG_ 1143 DU_HintGrdBelUnterbr 1;
BA_ "GenSigSwitchedByIgnition" SG_ 1143 DU_HintGrdBelUnterbr 0;
BA_ "GenSigSendType" SG_ 1143 DU_HintGrdBelUnterbr 3;
BA_ "Fehlerwert" SG_ 1143 EEPROM_Fehler 1;
BA_ "GenSigSwitchedByIgnition" SG_ 1143 EEPROM_Fehler 0;
BA_ "GenSigSendType" SG_ 1143 EEPROM_Fehler 3;
BA_ "Fehlerwert" SG_ 1143 DU1_SW_inkonsistent 1;
BA_ "GenSigSwitchedByIgnition" SG_ 1143 DU1_SW_inkonsistent 0;
BA_ "GenSigSendType" SG_ 1143 DU1_SW_inkonsistent 0;
BA_ "Fehlerwert" SG_ 1143 DU1_HDCP_Status 1;
BA_ "GenSigSwitchedByIgnition" SG_ 1143 DU1_HDCP_Status 0;
BA_ "GenSigSendType" SG_ 1143 DU1_HDCP_Status 3;
BA_ "GenSigSwitchedByIgnition" SG_ 1143 LVDS_Status 0;
BA_ "GenSigSendType" SG_ 1143 LVDS_Status 3;
BA_ "GenSigSwitchedByIgnition" SG_ 1143 ZR_Lenkerpos_Status 0;
BA_ "GenSigSendType" SG_ 1143 ZR_Lenkerpos_Status 0;
BA_ "GenSigSwitchedByIgnition" SG_ 1143 DU1_Touch_Fehlerstatus 0;
BA_ "GenSigSendType" SG_ 1143 DU1_Touch_Fehlerstatus 0;
BA_ "GenSigSwitchedByIgnition" SG_ 1143 DU1_Haptik_Fehlerstatus 0;
BA_ "GenSigSendType" SG_ 1143 DU1_Haptik_Fehlerstatus 0;
BA_ "GenSigSwitchedByIgnition" SG_ 1143 DU1_LVDS_Splitter_Fehlerstatus 0;
BA_ "GenSigSendType" SG_ 1143 DU1_LVDS_Splitter_Fehlerstatus 0;
BA_ "Fehlerwert" SG_ 561 DU1_KS_aktiv_anderer_Grund 1;
BA_ "GenSigSwitchedByIgnition" SG_ 561 DU1_KS_aktiv_anderer_Grund 0;
BA_ "GenSigSendType" SG_ 561 DU1_KS_aktiv_anderer_Grund 3;
BA_ "Fehlerwert" SG_ 561 DU1_KS_aktiv_falsche_Auth 1;
BA_ "GenSigSwitchedByIgnition" SG_ 561 DU1_KS_aktiv_falsche_Auth 0;
BA_ "GenSigSendType" SG_ 561 DU1_KS_aktiv_falsche_Auth 3;
BA_ "Fehlerwert" SG_ 561 DU1_KS_aktiv_Manipulationsschutz 1;
BA_ "GenSigSwitchedByIgnition" SG_ 561 DU1_KS_aktiv_Manipulationsschutz 0;
BA_ "GenSigSendType" SG_ 561 DU1_KS_aktiv_Manipulationsschutz 3;
BA_ "Fehlerwert" SG_ 561 DU1_KS_FIS_unplausibel 1;
BA_ "GenSigSwitchedByIgnition" SG_ 561 DU1_KS_FIS_unplausibel 0;
BA_ "GenSigSendType" SG_ 561 DU1_KS_FIS_unplausibel 3;
BA_ "Fehlerwert" SG_ 561 DU1_KS_keine_Grundeinstellung 1;
BA_ "GenSigSwitchedByIgnition" SG_ 561 DU1_KS_keine_Grundeinstellung 0;
BA_ "GenSigSendType" SG_ 561 DU1_KS_keine_Grundeinstellung 3;
BA_ "Fehlerwert" SG_ 561 DU1_KS_SHE_keine_Grundeinst 1;
BA_ "GenSigSwitchedByIgnition" SG_ 561 DU1_KS_SHE_keine_Grundeinst 0;
BA_ "GenSigSendType" SG_ 561 DU1_KS_SHE_keine_Grundeinst 3;
BA_ "GenSigSwitchedByIgnition" SG_ 561 DU1_Touchstatus 0;
BA_ "GenSigSendType" SG_ 561 DU1_Touchstatus 3;
BA_ "GenSigSwitchedByIgnition" SG_ 561 DU1_Fehlerstatus 0;
BA_ "GenSigSendType" SG_ 561 DU1_Fehlerstatus 3;
BA_ "GenSigSwitchedByIgnition" SG_ 561 DU1_Slider_Locked 0;
BA_ "GenSigSendType" SG_ 561 DU1_Slider_Locked 3;
BA_ "GenSigSwitchedByIgnition" SG_ 1144 DU2_State 0;
BA_ "GenSigSendType" SG_ 1144 DU2_State 3;
BA_ "GenSigSwitchedByIgnition" SG_ 1144 DU2_SystemMode 0;
BA_ "GenSigSendType" SG_ 1144 DU2_SystemMode 3;
BA_ "Fehlerwert" SG_ 1144 DU2_Temp_Fehler 1;
BA_ "GenSigSwitchedByIgnition" SG_ 1144 DU2_Temp_Fehler 0;
BA_ "GenSigSendType" SG_ 1144 DU2_Temp_Fehler 3;
BA_ "Fehlerwert" SG_ 1144 DU2_KL30_Uebersp_Fehler 1;
BA_ "GenSigSwitchedByIgnition" SG_ 1144 DU2_KL30_Uebersp_Fehler 0;
BA_ "GenSigSendType" SG_ 1144 DU2_KL30_Uebersp_Fehler 3;
BA_ "Fehlerwert" SG_ 1144 DU2_KL30_Untersp_Fehler 1;
BA_ "GenSigSwitchedByIgnition" SG_ 1144 DU2_KL30_Untersp_Fehler 0;
BA_ "GenSigSendType" SG_ 1144 DU2_KL30_Untersp_Fehler 3;
BA_ "GenSigSwitchedByIgnition" SG_ 1144 DU2_FB_Mode 0;
BA_ "GenSigSendType" SG_ 1144 DU2_FB_Mode 3;
BA_ "Fehlerwert" SG_ 1144 DU2_DispDerating 255;
BA_ "GenSigSwitchedByIgnition" SG_ 1144 DU2_DispDerating 0;
BA_ "GenSigStartValue" SG_ 1144 DU2_DispDerating 254;
BA_ "GenSigSendType" SG_ 1144 DU2_DispDerating 0;
BA_ "Fehlerwert" SG_ 1144 DU2_KL_30F 255;
BA_ "GenSigSwitchedByIgnition" SG_ 1144 DU2_KL_30F 0;
BA_ "GenSigStartValue" SG_ 1144 DU2_KL_30F 254;
BA_ "GenSigSendType" SG_ 1144 DU2_KL_30F 0;
BA_ "Fehlerwert" SG_ 1144 DU2_TempSens 255;
BA_ "GenSigSwitchedByIgnition" SG_ 1144 DU2_TempSens 0;
BA_ "GenSigStartValue" SG_ 1144 DU2_TempSens 254;
BA_ "GenSigSendType" SG_ 1144 DU2_TempSens 0;
BA_ "Fehlerwert" SG_ 1144 DU2_TempSensMax 255;
BA_ "GenSigSwitchedByIgnition" SG_ 1144 DU2_TempSensMax 0;
BA_ "GenSigStartValue" SG_ 1144 DU2_TempSensMax 254;
BA_ "GenSigSendType" SG_ 1144 DU2_TempSensMax 0;
BA_ "GenSigSwitchedByIgnition" SG_ 1144 DU2_Variant 0;
BA_ "GenSigStartValue" SG_ 1144 DU2_Variant 254;
BA_ "GenSigSendType" SG_ 1144 DU2_Variant 0;
BA_ "GenSigSwitchedByIgnition" SG_ 1144 DU2_Zulieferer 0;
BA_ "GenSigSendType" SG_ 1144 DU2_Zulieferer 0;
BA_ "Fehlerwert" SG_ 1144 DU2_HU_Fotosensor 511;
BA_ "GenSigSwitchedByIgnition" SG_ 1144 DU2_HU_Fotosensor 0;
BA_ "GenSigStartValue" SG_ 1144 DU2_HU_Fotosensor 510;
BA_ "GenSigSendType" SG_ 1144 DU2_HU_Fotosensor 0;
BA_ "Fehlerwert" SG_ 1145 DU2_Betriebsdauer_min 255;
BA_ "GenSigSwitchedByIgnition" SG_ 1145 DU2_Betriebsdauer_min 0;
BA_ "GenSigStartValue" SG_ 1145 DU2_Betriebsdauer_min 254;
BA_ "GenSigSendType" SG_ 1145 DU2_Betriebsdauer_min 0;
BA_ "Fehlerwert" SG_ 1145 DU2_Betriebsdauer_std 65535;
BA_ "GenSigSwitchedByIgnition" SG_ 1145 DU2_Betriebsdauer_std 0;
BA_ "GenSigStartValue" SG_ 1145 DU2_Betriebsdauer_std 65534;
BA_ "GenSigSendType" SG_ 1145 DU2_Betriebsdauer_std 0;
BA_ "Fehlerwert" SG_ 1145 DU2_HintGrdBelKurzschl 1;
BA_ "GenSigSwitchedByIgnition" SG_ 1145 DU2_HintGrdBelKurzschl 0;
BA_ "GenSigSendType" SG_ 1145 DU2_HintGrdBelKurzschl 3;
BA_ "Fehlerwert" SG_ 1145 DU2_HintGrdBelUnterbr 1;
BA_ "GenSigSwitchedByIgnition" SG_ 1145 DU2_HintGrdBelUnterbr 0;
BA_ "GenSigSendType" SG_ 1145 DU2_HintGrdBelUnterbr 3;
BA_ "Fehlerwert" SG_ 1145 DU2_EEPROM_Fehler 1;
BA_ "GenSigSwitchedByIgnition" SG_ 1145 DU2_EEPROM_Fehler 0;
BA_ "GenSigSendType" SG_ 1145 DU2_EEPROM_Fehler 3;
BA_ "Fehlerwert" SG_ 1145 DU2_SW_inkonsistent 1;
BA_ "GenSigSwitchedByIgnition" SG_ 1145 DU2_SW_inkonsistent 0;
BA_ "GenSigSendType" SG_ 1145 DU2_SW_inkonsistent 0;
BA_ "Fehlerwert" SG_ 1145 DU2_HDCP_Status 1;
BA_ "GenSigSwitchedByIgnition" SG_ 1145 DU2_HDCP_Status 0;
BA_ "GenSigSendType" SG_ 1145 DU2_HDCP_Status 3;
BA_ "GenSigSwitchedByIgnition" SG_ 1145 DU2_LVDS_Status 0;
BA_ "GenSigSendType" SG_ 1145 DU2_LVDS_Status 3;
BA_ "GenSigSwitchedByIgnition" SG_ 1145 DU2_ZR_Lenkerpos_Status 0;
BA_ "GenSigSendType" SG_ 1145 DU2_ZR_Lenkerpos_Status 0;
BA_ "GenSigSwitchedByIgnition" SG_ 1145 DU2_Touch_Fehlerstatus 0;
BA_ "GenSigSendType" SG_ 1145 DU2_Touch_Fehlerstatus 0;
BA_ "GenSigSwitchedByIgnition" SG_ 1145 DU2_Haptik_Fehlerstatus 0;
BA_ "GenSigSendType" SG_ 1145 DU2_Haptik_Fehlerstatus 0;
BA_ "GenSigSwitchedByIgnition" SG_ 1145 DU2_LVDS_Splitter_Fehlerstatus 0;
BA_ "GenSigSendType" SG_ 1145 DU2_LVDS_Splitter_Fehlerstatus 0;
BA_ "GenSigSwitchedByIgnition" SG_ 2589283758 DU3_State 0;
BA_ "GenSigSendType" SG_ 2589283758 DU3_State 3;
BA_ "GenSigSwitchedByIgnition" SG_ 2589283758 DU3_SystemMode 0;
BA_ "GenSigSendType" SG_ 2589283758 DU3_SystemMode 3;
BA_ "Fehlerwert" SG_ 2589283758 DU3_Temp_Fehler 1;
BA_ "GenSigSwitchedByIgnition" SG_ 2589283758 DU3_Temp_Fehler 0;
BA_ "GenSigSendType" SG_ 2589283758 DU3_Temp_Fehler 3;
BA_ "Fehlerwert" SG_ 2589283758 DU3_KL30_Uebersp_Fehler 1;
BA_ "GenSigSwitchedByIgnition" SG_ 2589283758 DU3_KL30_Uebersp_Fehler 0;
BA_ "GenSigSendType" SG_ 2589283758 DU3_KL30_Uebersp_Fehler 3;
BA_ "Fehlerwert" SG_ 2589283758 DU3_KL30_Untersp_Fehler 1;
BA_ "GenSigSwitchedByIgnition" SG_ 2589283758 DU3_KL30_Untersp_Fehler 0;
BA_ "GenSigSendType" SG_ 2589283758 DU3_KL30_Untersp_Fehler 3;
BA_ "GenSigSwitchedByIgnition" SG_ 2589283758 DU3_FB_Mode 0;
BA_ "GenSigSendType" SG_ 2589283758 DU3_FB_Mode 3;
BA_ "Fehlerwert" SG_ 2589283758 DU3_DispDerating 255;
BA_ "GenSigSwitchedByIgnition" SG_ 2589283758 DU3_DispDerating 0;
BA_ "GenSigStartValue" SG_ 2589283758 DU3_DispDerating 254;
BA_ "GenSigSendType" SG_ 2589283758 DU3_DispDerating 0;
BA_ "Fehlerwert" SG_ 2589283758 DU3_KL_30F 255;
BA_ "GenSigSwitchedByIgnition" SG_ 2589283758 DU3_KL_30F 0;
BA_ "GenSigStartValue" SG_ 2589283758 DU3_KL_30F 254;
BA_ "GenSigSendType" SG_ 2589283758 DU3_KL_30F 0;
BA_ "Fehlerwert" SG_ 2589283758 DU3_TempSens 255;
BA_ "GenSigSwitchedByIgnition" SG_ 2589283758 DU3_TempSens 0;
BA_ "GenSigStartValue" SG_ 2589283758 DU3_TempSens 254;
BA_ "GenSigSendType" SG_ 2589283758 DU3_TempSens 0;
BA_ "Fehlerwert" SG_ 2589283758 DU3_TempSensMax 255;
BA_ "GenSigSwitchedByIgnition" SG_ 2589283758 DU3_TempSensMax 0;
BA_ "GenSigStartValue" SG_ 2589283758 DU3_TempSensMax 254;
BA_ "GenSigSendType" SG_ 2589283758 DU3_TempSensMax 0;
BA_ "GenSigSwitchedByIgnition" SG_ 2589283758 DU3_Variant 0;
BA_ "GenSigStartValue" SG_ 2589283758 DU3_Variant 254;
BA_ "GenSigSendType" SG_ 2589283758 DU3_Variant 0;
BA_ "GenSigSwitchedByIgnition" SG_ 2589283758 DU3_Zulieferer 0;
BA_ "GenSigSendType" SG_ 2589283758 DU3_Zulieferer 0;
BA_ "Fehlerwert" SG_ 2589283758 DU3_HU_Fotosensor 511;
BA_ "GenSigSwitchedByIgnition" SG_ 2589283758 DU3_HU_Fotosensor 0;
BA_ "GenSigStartValue" SG_ 2589283758 DU3_HU_Fotosensor 510;
BA_ "GenSigSendType" SG_ 2589283758 DU3_HU_Fotosensor 0;
BA_ "GenSigSwitchedByIgnition" SG_ 2589283758 DU3_Schatter_Fehlerstatus 0;
BA_ "GenSigSendType" SG_ 2589283758 DU3_Schatter_Fehlerstatus 3;
BA_REL_ "GenSigTimeoutTime" BU_SG_REL_ ZR_High_TT3 SG_ 2536714496 BAP_Audio_ASG_01_Header 500;
BA_REL_ "GenSigTimeoutTime" BU_SG_REL_ ZR_High_TT3 SG_ 2536714497 BAP_Audio_ASG_02_Header 500;
BA_REL_ "GenSigTimeoutTime" BU_SG_REL_ Kombi_TT3 SG_ 2536714512 BAP_Audio_FSG_01_Header 5000;
BA_REL_ "GenSigTimeoutTime" BU_SG_REL_ Kombi_TT3 SG_ 2536714513 BAP_Audio_FSG_02_Header 5000;
BA_REL_ "GenSigTimeoutTime" BU_SG_REL_ ExBox SG_ 2536716288 BAP_ExBox_ASG_01_Header 800;
BA_REL_ "GenSigTimeoutTime" BU_SG_REL_ ZR_High_Korea SG_ 2536716304 BAP_ExBox_FSG_01_Header 5000;
BA_REL_ "GenSigTimeoutTime" BU_SG_REL_ ZR_High_TT3 SG_ 2536715264 BAP_MFL_ASG_01_Header 800;
BA_REL_ "GenSigTimeoutTime" BU_SG_REL_ Kombi_TT3 SG_ 2536715280 BAP_MFL_FSG_01_Header 5000;
BA_REL_ "GenSigTimeoutTime" BU_SG_REL_ ExBox SG_ 2536714752 BAP_Navigation_ASG_01_Header 500;
BA_REL_ "GenSigTimeoutTime" BU_SG_REL_ ZR_High_TT3 SG_ 2536714752 BAP_Navigation_ASG_01_Header 500;
BA_REL_ "GenSigTimeoutTime" BU_SG_REL_ ExBox SG_ 2536714753 BAP_Navigation_ASG_02_Header 500;
BA_REL_ "GenSigTimeoutTime" BU_SG_REL_ ZR_High_TT3 SG_ 2536714753 BAP_Navigation_ASG_02_Header 500;
BA_REL_ "GenSigTimeoutTime" BU_SG_REL_ ExBox SG_ 2536714754 BAP_Navigation_ASG_03_Header 500;
BA_REL_ "GenSigTimeoutTime" BU_SG_REL_ ExBox SG_ 2536714755 BAP_Navigation_ASG_04_Header 500;
BA_REL_ "GenSigTimeoutTime" BU_SG_REL_ Kombi_TT3 SG_ 2536714768 BAP_Navigation_FSG_01_Header 5000;
BA_REL_ "GenSigTimeoutTime" BU_SG_REL_ Kombi_TT3 SG_ 2536714769 BAP_Navigation_FSG_02_Header 5000;
BA_REL_ "GenSigTimeoutTime" BU_SG_REL_ ExBox SG_ 2536712448 BAP_Telefon2_ASG_01_Header 800;
BA_REL_ "GenSigTimeoutTime" BU_SG_REL_ ZR_High_TT3 SG_ 2536712448 BAP_Telefon2_ASG_01_Header 800;
BA_REL_ "GenSigTimeoutTime" BU_SG_REL_ Kombi_TT3 SG_ 2536712464 BAP_Telefon2_FSG_01_Header 5000;
BA_REL_ "GenSigTimeoutTime" BU_SG_REL_ ExBox SG_ 2536712192 BAP_Telefon_ASG_01_Header 500;
BA_REL_ "GenSigTimeoutTime" BU_SG_REL_ ZR_High_TT3 SG_ 2536712192 BAP_Telefon_ASG_01_Header 500;
BA_REL_ "GenSigTimeoutTime" BU_SG_REL_ ExBox SG_ 2536712193 BAP_Telefon_ASG_02_Header 500;
BA_REL_ "GenSigTimeoutTime" BU_SG_REL_ ZR_High_TT3 SG_ 2536712193 BAP_Telefon_ASG_02_Header 500;
BA_REL_ "GenSigTimeoutTime" BU_SG_REL_ ExBox SG_ 2536712194 BAP_Telefon_ASG_03_Header 500;
BA_REL_ "GenSigTimeoutTime" BU_SG_REL_ ExBox SG_ 2536712195 BAP_Telefon_ASG_04_Header 500;
BA_REL_ "GenSigTimeoutTime" BU_SG_REL_ Kombi_TT3 SG_ 2536712208 BAP_Telefon_FSG_01_Header 5000;
BA_REL_ "GenSigTimeoutTime" BU_SG_REL_ Kombi_TT3 SG_ 2536712209 BAP_Telefon_FSG_02_Header 5000;
BA_REL_ "GenSigTimeoutTime" BU_SG_REL_ ZR_Entry SG_ 1139 BT_Variant 5000;
BA_REL_ "GenSigTimeoutTime" BU_SG_REL_ ZR_High SG_ 1139 BT_Variant 5000;
BA_REL_ "GenSigTimeoutTime" BU_SG_REL_ ZR_High_Korea SG_ 1139 BT_Variant 5000;
BA_REL_ "GenSigTimeoutTime" BU_SG_REL_ ZR_High_TT3 SG_ 1139 BT_Variant 5000;
BA_REL_ "GenSigTimeoutTime" BU_SG_REL_ ZR_MIB_OPTION_ab_Gen3 SG_ 1139 BT_Variant 5000;
BA_REL_ "GenSigTimeoutTime" BU_SG_REL_ ZR_MIB_TOP_ab_Gen3 SG_ 1139 BT_Variant 5000;
BA_REL_ "GenSigTimeoutTime" BU_SG_REL_ ZR_Standard SG_ 1139 BT_Variant 5000;
BA_REL_ "GenSigTimeoutTime" BU_SG_REL_ ZR_Entry SG_ 1139 SystemMode 5000;
BA_REL_ "GenSigTimeoutTime" BU_SG_REL_ ZR_High SG_ 1139 SystemMode 5000;
BA_REL_ "GenSigTimeoutTime" BU_SG_REL_ ZR_High_Korea SG_ 1139 SystemMode 5000;
BA_REL_ "GenSigTimeoutTime" BU_SG_REL_ ZR_High_TT3 SG_ 1139 SystemMode 5000;
BA_REL_ "GenSigTimeoutTime" BU_SG_REL_ ZR_MIB_OPTION_ab_Gen3 SG_ 1139 SystemMode 5000;
BA_REL_ "GenSigTimeoutTime" BU_SG_REL_ ZR_MIB_TOP_ab_Gen3 SG_ 1139 SystemMode 5000;
BA_REL_ "GenSigTimeoutTime" BU_SG_REL_ ZR_Standard SG_ 1139 SystemMode 5000;
BA_REL_ "GenSigTimeoutTime" BU_SG_REL_ ZR_Entry SG_ 1139 BT_DKM_Kurzschluss_GND 5000;
BA_REL_ "GenSigTimeoutTime" BU_SG_REL_ ZR_High SG_ 1139 BT_DKM_Kurzschluss_GND 5000;
BA_REL_ "GenSigTimeoutTime" BU_SG_REL_ ZR_High_Korea SG_ 1139 BT_DKM_Kurzschluss_GND 5000;
BA_REL_ "GenSigTimeoutTime" BU_SG_REL_ ZR_High_TT3 SG_ 1139 BT_DKM_Kurzschluss_GND 5000;
BA_REL_ "GenSigTimeoutTime" BU_SG_REL_ ZR_MIB_OPTION_ab_Gen3 SG_ 1139 BT_DKM_Kurzschluss_GND 5000;
BA_REL_ "GenSigTimeoutTime" BU_SG_REL_ ZR_MIB_TOP_ab_Gen3 SG_ 1139 BT_DKM_Kurzschluss_GND 5000;
BA_REL_ "GenSigTimeoutTime" BU_SG_REL_ ZR_Standard SG_ 1139 BT_DKM_Kurzschluss_GND 5000;
BA_REL_ "GenSigTimeoutTime" BU_SG_REL_ ZR_Entry SG_ 1139 BT_DKM_Kurzschluss_Ubat 5000;
BA_REL_ "GenSigTimeoutTime" BU_SG_REL_ ZR_High SG_ 1139 BT_DKM_Kurzschluss_Ubat 5000;
BA_REL_ "GenSigTimeoutTime" BU_SG_REL_ ZR_High_Korea SG_ 1139 BT_DKM_Kurzschluss_Ubat 5000;
BA_REL_ "GenSigTimeoutTime" BU_SG_REL_ ZR_High_TT3 SG_ 1139 BT_DKM_Kurzschluss_Ubat 5000;
BA_REL_ "GenSigTimeoutTime" BU_SG_REL_ ZR_MIB_OPTION_ab_Gen3 SG_ 1139 BT_DKM_Kurzschluss_Ubat 5000;
BA_REL_ "GenSigTimeoutTime" BU_SG_REL_ ZR_MIB_TOP_ab_Gen3 SG_ 1139 BT_DKM_Kurzschluss_Ubat 5000;
BA_REL_ "GenSigTimeoutTime" BU_SG_REL_ ZR_Standard SG_ 1139 BT_DKM_Kurzschluss_Ubat 5000;
BA_REL_ "GenSigTimeoutTime" BU_SG_REL_ ZR_Entry SG_ 1139 BT_DKM_Unterbrechung 5000;
BA_REL_ "GenSigTimeoutTime" BU_SG_REL_ ZR_High SG_ 1139 BT_DKM_Unterbrechung 5000;
BA_REL_ "GenSigTimeoutTime" BU_SG_REL_ ZR_High_Korea SG_ 1139 BT_DKM_Unterbrechung 5000;
BA_REL_ "GenSigTimeoutTime" BU_SG_REL_ ZR_High_TT3 SG_ 1139 BT_DKM_Unterbrechung 5000;
BA_REL_ "GenSigTimeoutTime" BU_SG_REL_ ZR_MIB_OPTION_ab_Gen3 SG_ 1139 BT_DKM_Unterbrechung 5000;
BA_REL_ "GenSigTimeoutTime" BU_SG_REL_ ZR_MIB_TOP_ab_Gen3 SG_ 1139 BT_DKM_Unterbrechung 5000;
BA_REL_ "GenSigTimeoutTime" BU_SG_REL_ ZR_Standard SG_ 1139 BT_DKM_Unterbrechung 5000;
BA_REL_ "GenSigTimeoutTime" BU_SG_REL_ ZR_Entry SG_ 1139 BT_DKM_k_Hallsignal 5000;
BA_REL_ "GenSigTimeoutTime" BU_SG_REL_ ZR_High SG_ 1139 BT_DKM_k_Hallsignal 5000;
BA_REL_ "GenSigTimeoutTime" BU_SG_REL_ ZR_High_Korea SG_ 1139 BT_DKM_k_Hallsignal 5000;
BA_REL_ "GenSigTimeoutTime" BU_SG_REL_ ZR_High_TT3 SG_ 1139 BT_DKM_k_Hallsignal 5000;
BA_REL_ "GenSigTimeoutTime" BU_SG_REL_ ZR_MIB_OPTION_ab_Gen3 SG_ 1139 BT_DKM_k_Hallsignal 5000;
BA_REL_ "GenSigTimeoutTime" BU_SG_REL_ ZR_MIB_TOP_ab_Gen3 SG_ 1139 BT_DKM_k_Hallsignal 5000;
BA_REL_ "GenSigTimeoutTime" BU_SG_REL_ ZR_Standard SG_ 1139 BT_DKM_k_Hallsignal 5000;
BA_REL_ "GenSigTimeoutTime" BU_SG_REL_ ZR_Entry SG_ 1139 BT_DKM_Ueberlastung 5000;
BA_REL_ "GenSigTimeoutTime" BU_SG_REL_ ZR_High SG_ 1139 BT_DKM_Ueberlastung 5000;
BA_REL_ "GenSigTimeoutTime" BU_SG_REL_ ZR_High_Korea SG_ 1139 BT_DKM_Ueberlastung 5000;
BA_REL_ "GenSigTimeoutTime" BU_SG_REL_ ZR_High_TT3 SG_ 1139 BT_DKM_Ueberlastung 5000;
BA_REL_ "GenSigTimeoutTime" BU_SG_REL_ ZR_MIB_OPTION_ab_Gen3 SG_ 1139 BT_DKM_Ueberlastung 5000;
BA_REL_ "GenSigTimeoutTime" BU_SG_REL_ ZR_MIB_TOP_ab_Gen3 SG_ 1139 BT_DKM_Ueberlastung 5000;
BA_REL_ "GenSigTimeoutTime" BU_SG_REL_ ZR_Standard SG_ 1139 BT_DKM_Ueberlastung 5000;
BA_REL_ "GenSigTimeoutTime" BU_SG_REL_ ZR_Entry SG_ 1139 BT_DKM_Mech_Flauf 5000;
BA_REL_ "GenSigTimeoutTime" BU_SG_REL_ ZR_High SG_ 1139 BT_DKM_Mech_Flauf 5000;
BA_REL_ "GenSigTimeoutTime" BU_SG_REL_ ZR_High_Korea SG_ 1139 BT_DKM_Mech_Flauf 5000;
BA_REL_ "GenSigTimeoutTime" BU_SG_REL_ ZR_High_TT3 SG_ 1139 BT_DKM_Mech_Flauf 5000;
BA_REL_ "GenSigTimeoutTime" BU_SG_REL_ ZR_MIB_OPTION_ab_Gen3 SG_ 1139 BT_DKM_Mech_Flauf 5000;
BA_REL_ "GenSigTimeoutTime" BU_SG_REL_ ZR_MIB_TOP_ab_Gen3 SG_ 1139 BT_DKM_Mech_Flauf 5000;
BA_REL_ "GenSigTimeoutTime" BU_SG_REL_ ZR_Standard SG_ 1139 BT_DKM_Mech_Flauf 5000;
BA_REL_ "GenSigTimeoutTime" BU_SG_REL_ ZR_Entry SG_ 1139 BT_KBD_TP_Fehler 5000;
BA_REL_ "GenSigTimeoutTime" BU_SG_REL_ ZR_High SG_ 1139 BT_KBD_TP_Fehler 5000;
BA_REL_ "GenSigTimeoutTime" BU_SG_REL_ ZR_High_Korea SG_ 1139 BT_KBD_TP_Fehler 5000;
BA_REL_ "GenSigTimeoutTime" BU_SG_REL_ ZR_High_TT3 SG_ 1139 BT_KBD_TP_Fehler 5000;
BA_REL_ "GenSigTimeoutTime" BU_SG_REL_ ZR_MIB_OPTION_ab_Gen3 SG_ 1139 BT_KBD_TP_Fehler 5000;
BA_REL_ "GenSigTimeoutTime" BU_SG_REL_ ZR_MIB_TOP_ab_Gen3 SG_ 1139 BT_KBD_TP_Fehler 5000;
BA_REL_ "GenSigTimeoutTime" BU_SG_REL_ ZR_Standard SG_ 1139 BT_KBD_TP_Fehler 5000;
BA_REL_ "GenSigTimeoutTime" BU_SG_REL_ ZR_Entry SG_ 1139 BT_DKM_EL_Fehler 5000;
BA_REL_ "GenSigTimeoutTime" BU_SG_REL_ ZR_High SG_ 1139 BT_DKM_EL_Fehler 5000;
BA_REL_ "GenSigTimeoutTime" BU_SG_REL_ ZR_High_Korea SG_ 1139 BT_DKM_EL_Fehler 5000;
BA_REL_ "GenSigTimeoutTime" BU_SG_REL_ ZR_High_TT3 SG_ 1139 BT_DKM_EL_Fehler 5000;
BA_REL_ "GenSigTimeoutTime" BU_SG_REL_ ZR_MIB_OPTION_ab_Gen3 SG_ 1139 BT_DKM_EL_Fehler 5000;
BA_REL_ "GenSigTimeoutTime" BU_SG_REL_ ZR_MIB_TOP_ab_Gen3 SG_ 1139 BT_DKM_EL_Fehler 5000;
BA_REL_ "GenSigTimeoutTime" BU_SG_REL_ ZR_Standard SG_ 1139 BT_DKM_EL_Fehler 5000;
BA_REL_ "GenSigTimeoutTime" BU_SG_REL_ ZR_Entry SG_ 1139 BT_DKM_Manual_Operation 5000;
BA_REL_ "GenSigTimeoutTime" BU_SG_REL_ ZR_High SG_ 1139 BT_DKM_Manual_Operation 5000;
BA_REL_ "GenSigTimeoutTime" BU_SG_REL_ ZR_High_Korea SG_ 1139 BT_DKM_Manual_Operation 5000;
BA_REL_ "GenSigTimeoutTime" BU_SG_REL_ ZR_High_TT3 SG_ 1139 BT_DKM_Manual_Operation 5000;
BA_REL_ "GenSigTimeoutTime" BU_SG_REL_ ZR_MIB_OPTION_ab_Gen3 SG_ 1139 BT_DKM_Manual_Operation 5000;
BA_REL_ "GenSigTimeoutTime" BU_SG_REL_ ZR_MIB_TOP_ab_Gen3 SG_ 1139 BT_DKM_Manual_Operation 5000;
BA_REL_ "GenSigTimeoutTime" BU_SG_REL_ ZR_Standard SG_ 1139 BT_DKM_Manual_Operation 5000;
BA_REL_ "GenSigTimeoutTime" BU_SG_REL_ ZR_Entry SG_ 1139 BT_LIN1_Unterbrechung 5000;
BA_REL_ "GenSigTimeoutTime" BU_SG_REL_ ZR_High SG_ 1139 BT_LIN1_Unterbrechung 5000;
BA_REL_ "GenSigTimeoutTime" BU_SG_REL_ ZR_High_Korea SG_ 1139 BT_LIN1_Unterbrechung 5000;
BA_REL_ "GenSigTimeoutTime" BU_SG_REL_ ZR_High_TT3 SG_ 1139 BT_LIN1_Unterbrechung 5000;
BA_REL_ "GenSigTimeoutTime" BU_SG_REL_ ZR_MIB_OPTION_ab_Gen3 SG_ 1139 BT_LIN1_Unterbrechung 5000;
BA_REL_ "GenSigTimeoutTime" BU_SG_REL_ ZR_MIB_TOP_ab_Gen3 SG_ 1139 BT_LIN1_Unterbrechung 5000;
BA_REL_ "GenSigTimeoutTime" BU_SG_REL_ ZR_Standard SG_ 1139 BT_LIN1_Unterbrechung 5000;
BA_REL_ "GenSigTimeoutTime" BU_SG_REL_ ZR_Entry SG_ 1139 BT_LIN2_Unterbrechung 5000;
BA_REL_ "GenSigTimeoutTime" BU_SG_REL_ ZR_High SG_ 1139 BT_LIN2_Unterbrechung 5000;
BA_REL_ "GenSigTimeoutTime" BU_SG_REL_ ZR_High_Korea SG_ 1139 BT_LIN2_Unterbrechung 5000;
BA_REL_ "GenSigTimeoutTime" BU_SG_REL_ ZR_High_TT3 SG_ 1139 BT_LIN2_Unterbrechung 5000;
BA_REL_ "GenSigTimeoutTime" BU_SG_REL_ ZR_MIB_OPTION_ab_Gen3 SG_ 1139 BT_LIN2_Unterbrechung 5000;
BA_REL_ "GenSigTimeoutTime" BU_SG_REL_ ZR_MIB_TOP_ab_Gen3 SG_ 1139 BT_LIN2_Unterbrechung 5000;
BA_REL_ "GenSigTimeoutTime" BU_SG_REL_ ZR_Standard SG_ 1139 BT_LIN2_Unterbrechung 5000;
BA_REL_ "GenSigTimeoutTime" BU_SG_REL_ ZR_Entry SG_ 1139 BT_DKM_Mech_Flauf_2 5000;
BA_REL_ "GenSigTimeoutTime" BU_SG_REL_ ZR_High SG_ 1139 BT_DKM_Mech_Flauf_2 5000;
BA_REL_ "GenSigTimeoutTime" BU_SG_REL_ ZR_High_Korea SG_ 1139 BT_DKM_Mech_Flauf_2 5000;
BA_REL_ "GenSigTimeoutTime" BU_SG_REL_ ZR_High_TT3 SG_ 1139 BT_DKM_Mech_Flauf_2 5000;
BA_REL_ "GenSigTimeoutTime" BU_SG_REL_ ZR_MIB_OPTION_ab_Gen3 SG_ 1139 BT_DKM_Mech_Flauf_2 5000;
BA_REL_ "GenSigTimeoutTime" BU_SG_REL_ ZR_MIB_TOP_ab_Gen3 SG_ 1139 BT_DKM_Mech_Flauf_2 5000;
BA_REL_ "GenSigTimeoutTime" BU_SG_REL_ ZR_Standard SG_ 1139 BT_DKM_Mech_Flauf_2 5000;
BA_REL_ "GenSigTimeoutTime" BU_SG_REL_ ABT_1_MIB_ab_Gen3 SG_ 1635 BEM_02_Abschaltstufen 1000;
BA_REL_ "GenSigTimeoutTime" BU_SG_REL_ ABT_1_MQB SG_ 1635 BEM_02_Abschaltstufen 1000;
BA_REL_ "GenSigTimeoutTime" BU_SG_REL_ BT_1_MQB SG_ 1635 BEM_02_Abschaltstufen 1000;
BA_REL_ "GenSigTimeoutTime" BU_SG_REL_ DU_3 SG_ 1635 BEM_02_Abschaltstufen 1000;
BA_REL_ "GenSigTimeoutTime" BU_SG_REL_ DU_4 SG_ 1635 BEM_02_Abschaltstufen 1000;
BA_REL_ "GenSigTimeoutTime" BU_SG_REL_ ExBox SG_ 1635 BEM_02_Abschaltstufen 1000;
BA_REL_ "GenSigTimeoutTime" BU_SG_REL_ LSR_1 SG_ 1635 BEM_02_Abschaltstufen 1000;
BA_REL_ "GenSigTimeoutTime" BU_SG_REL_ SCC1 SG_ 1635 BEM_02_Abschaltstufen 1000;
BA_REL_ "GenSigTimeoutTime" BU_SG_REL_ SCC2 SG_ 1635 BEM_02_Abschaltstufen 1000;
BA_REL_ "GenSigTimeoutTime" BU_SG_REL_ SDC1 SG_ 1635 BEM_02_Abschaltstufen 1000;
BA_REL_ "GenSigTimeoutTime" BU_SG_REL_ SDC2 SG_ 1635 BEM_02_Abschaltstufen 1000;
BA_REL_ "GenSigTimeoutTime" BU_SG_REL_ WLC_01 SG_ 1635 BEM_02_Abschaltstufen 1000;
BA_REL_ "GenSigTimeoutTime" BU_SG_REL_ WLC_02 SG_ 1635 BEM_02_Abschaltstufen 1000;
BA_REL_ "GenSigTimeoutTime" BU_SG_REL_ BT_1_MQB SG_ 1635 BEM_MMI_Vorwarnung 1000;
BA_REL_ "GenSigTimeoutTime" BU_SG_REL_ LSR_1 SG_ 1635 BEM_MMI_Vorwarnung 1000;
BA_REL_ "GenSigTimeoutTime" BU_SG_REL_ SCC1 SG_ 1635 BEM_MMI_Vorwarnung 1000;
BA_REL_ "GenSigTimeoutTime" BU_SG_REL_ SCC2 SG_ 1635 BEM_MMI_Vorwarnung 1000;
BA_REL_ "GenSigTimeoutTime" BU_SG_REL_ SDC1 SG_ 1635 BEM_MMI_Vorwarnung 1000;
BA_REL_ "GenSigTimeoutTime" BU_SG_REL_ SDC2 SG_ 1635 BEM_MMI_Vorwarnung 1000;
BA_REL_ "GenSigTimeoutTime" BU_SG_REL_ ABT_1_MIB_ab_Gen3 SG_ 1714 DGN_Verlernzaehler 5000;
BA_REL_ "GenSigTimeoutTime" BU_SG_REL_ ExBox SG_ 1714 DGN_Verlernzaehler 5000;
BA_REL_ "GenSigTimeoutTime" BU_SG_REL_ SCC1 SG_ 1714 DGN_Verlernzaehler 5000;
BA_REL_ "GenSigTimeoutTime" BU_SG_REL_ SCC2 SG_ 1714 DGN_Verlernzaehler 5000;
BA_REL_ "GenSigTimeoutTime" BU_SG_REL_ SDC1 SG_ 1714 DGN_Verlernzaehler 5000;
BA_REL_ "GenSigTimeoutTime" BU_SG_REL_ SDC2 SG_ 1714 DGN_Verlernzaehler 5000;
BA_REL_ "GenSigTimeoutTime" BU_SG_REL_ ABT_1_MIB_ab_Gen3 SG_ 1714 KBI_Kilometerstand 5000;
BA_REL_ "GenSigTimeoutTime" BU_SG_REL_ ExBox SG_ 1714 KBI_Kilometerstand 5000;
BA_REL_ "GenSigTimeoutTime" BU_SG_REL_ SCC1 SG_ 1714 KBI_Kilometerstand 5000;
BA_REL_ "GenSigTimeoutTime" BU_SG_REL_ SCC2 SG_ 1714 KBI_Kilometerstand 5000;
BA_REL_ "GenSigTimeoutTime" BU_SG_REL_ SDC1 SG_ 1714 KBI_Kilometerstand 5000;
BA_REL_ "GenSigTimeoutTime" BU_SG_REL_ SDC2 SG_ 1714 KBI_Kilometerstand 5000;
BA_REL_ "GenSigTimeoutTime" BU_SG_REL_ ABT_1_MIB_ab_Gen3 SG_ 1714 UH_Jahr 5000;
BA_REL_ "GenSigTimeoutTime" BU_SG_REL_ DU_4 SG_ 1714 UH_Jahr 5000;
BA_REL_ "GenSigTimeoutTime" BU_SG_REL_ ExBox SG_ 1714 UH_Jahr 5000;
BA_REL_ "GenSigTimeoutTime" BU_SG_REL_ SCC1 SG_ 1714 UH_Jahr 5000;
BA_REL_ "GenSigTimeoutTime" BU_SG_REL_ SCC2 SG_ 1714 UH_Jahr 5000;
BA_REL_ "GenSigTimeoutTime" BU_SG_REL_ SDC1 SG_ 1714 UH_Jahr 5000;
BA_REL_ "GenSigTimeoutTime" BU_SG_REL_ SDC2 SG_ 1714 UH_Jahr 5000;
BA_REL_ "GenSigTimeoutTime" BU_SG_REL_ TVTuner_ab_Gen3_JPN SG_ 1714 UH_Jahr 5000;
BA_REL_ "GenSigTimeoutTime" BU_SG_REL_ ABT_1_MIB_ab_Gen3 SG_ 1714 UH_Monat 5000;
BA_REL_ "GenSigTimeoutTime" BU_SG_REL_ DU_4 SG_ 1714 UH_Monat 5000;
BA_REL_ "GenSigTimeoutTime" BU_SG_REL_ ExBox SG_ 1714 UH_Monat 5000;
BA_REL_ "GenSigTimeoutTime" BU_SG_REL_ SCC1 SG_ 1714 UH_Monat 5000;
BA_REL_ "GenSigTimeoutTime" BU_SG_REL_ SCC2 SG_ 1714 UH_Monat 5000;
BA_REL_ "GenSigTimeoutTime" BU_SG_REL_ SDC1 SG_ 1714 UH_Monat 5000;
BA_REL_ "GenSigTimeoutTime" BU_SG_REL_ SDC2 SG_ 1714 UH_Monat 5000;
BA_REL_ "GenSigTimeoutTime" BU_SG_REL_ TVTuner_ab_Gen3_JPN SG_ 1714 UH_Monat 5000;
BA_REL_ "GenSigTimeoutTime" BU_SG_REL_ ABT_1_MIB_ab_Gen3 SG_ 1714 UH_Tag 5000;
BA_REL_ "GenSigTimeoutTime" BU_SG_REL_ DU_4 SG_ 1714 UH_Tag 5000;
BA_REL_ "GenSigTimeoutTime" BU_SG_REL_ ExBox SG_ 1714 UH_Tag 5000;
BA_REL_ "GenSigTimeoutTime" BU_SG_REL_ SCC1 SG_ 1714 UH_Tag 5000;
BA_REL_ "GenSigTimeoutTime" BU_SG_REL_ SCC2 SG_ 1714 UH_Tag 5000;
BA_REL_ "GenSigTimeoutTime" BU_SG_REL_ SDC1 SG_ 1714 UH_Tag 5000;
BA_REL_ "GenSigTimeoutTime" BU_SG_REL_ SDC2 SG_ 1714 UH_Tag 5000;
BA_REL_ "GenSigTimeoutTime" BU_SG_REL_ TVTuner_ab_Gen3_JPN SG_ 1714 UH_Tag 5000;
BA_REL_ "GenSigTimeoutTime" BU_SG_REL_ ABT_1_MIB_ab_Gen3 SG_ 1714 UH_Stunde 5000;
BA_REL_ "GenSigTimeoutTime" BU_SG_REL_ DU_4 SG_ 1714 UH_Stunde 5000;
BA_REL_ "GenSigTimeoutTime" BU_SG_REL_ ExBox SG_ 1714 UH_Stunde 5000;
BA_REL_ "GenSigTimeoutTime" BU_SG_REL_ SCC1 SG_ 1714 UH_Stunde 5000;
BA_REL_ "GenSigTimeoutTime" BU_SG_REL_ SCC2 SG_ 1714 UH_Stunde 5000;
BA_REL_ "GenSigTimeoutTime" BU_SG_REL_ SDC1 SG_ 1714 UH_Stunde 5000;
BA_REL_ "GenSigTimeoutTime" BU_SG_REL_ SDC2 SG_ 1714 UH_Stunde 5000;
BA_REL_ "GenSigTimeoutTime" BU_SG_REL_ TVTuner_ab_Gen3_JPN SG_ 1714 UH_Stunde 5000;
BA_REL_ "GenSigTimeoutTime" BU_SG_REL_ ABT_1_MIB_ab_Gen3 SG_ 1714 UH_Minute 5000;
BA_REL_ "GenSigTimeoutTime" BU_SG_REL_ DU_4 SG_ 1714 UH_Minute 5000;
BA_REL_ "GenSigTimeoutTime" BU_SG_REL_ ExBox SG_ 1714 UH_Minute 5000;
BA_REL_ "GenSigTimeoutTime" BU_SG_REL_ SCC1 SG_ 1714 UH_Minute 5000;
BA_REL_ "GenSigTimeoutTime" BU_SG_REL_ SCC2 SG_ 1714 UH_Minute 5000;
BA_REL_ "GenSigTimeoutTime" BU_SG_REL_ SDC1 SG_ 1714 UH_Minute 5000;
BA_REL_ "GenSigTimeoutTime" BU_SG_REL_ SDC2 SG_ 1714 UH_Minute 5000;
BA_REL_ "GenSigTimeoutTime" BU_SG_REL_ TVTuner_ab_Gen3_JPN SG_ 1714 UH_Minute 5000;
BA_REL_ "GenSigTimeoutTime" BU_SG_REL_ ABT_1_MIB_ab_Gen3 SG_ 1714 UH_Sekunde 5000;
BA_REL_ "GenSigTimeoutTime" BU_SG_REL_ DU_4 SG_ 1714 UH_Sekunde 5000;
BA_REL_ "GenSigTimeoutTime" BU_SG_REL_ ExBox SG_ 1714 UH_Sekunde 5000;
BA_REL_ "GenSigTimeoutTime" BU_SG_REL_ SCC1 SG_ 1714 UH_Sekunde 5000;
BA_REL_ "GenSigTimeoutTime" BU_SG_REL_ SCC2 SG_ 1714 UH_Sekunde 5000;
BA_REL_ "GenSigTimeoutTime" BU_SG_REL_ SDC1 SG_ 1714 UH_Sekunde 5000;
BA_REL_ "GenSigTimeoutTime" BU_SG_REL_ SDC2 SG_ 1714 UH_Sekunde 5000;
BA_REL_ "GenSigTimeoutTime" BU_SG_REL_ TVTuner_ab_Gen3_JPN SG_ 1714 UH_Sekunde 5000;
BA_REL_ "GenSigTimeoutTime" BU_SG_REL_ ABT_1_MIB_ab_Gen3 SG_ 1714 Vehicle_Driving_Cycle 5000;
BA_REL_ "GenSigTimeoutTime" BU_SG_REL_ ABT_1_MIB_ab_Gen3 SG_ 1714 Kombi_02_alt 5000;
BA_REL_ "GenSigTimeoutTime" BU_SG_REL_ ExBox SG_ 1714 Kombi_02_alt 5000;
BA_REL_ "GenSigTimeoutTime" BU_SG_REL_ SCC1 SG_ 1714 Kombi_02_alt 5000;
BA_REL_ "GenSigTimeoutTime" BU_SG_REL_ SCC2 SG_ 1714 Kombi_02_alt 5000;
BA_REL_ "GenSigTimeoutTime" BU_SG_REL_ SDC1 SG_ 1714 Kombi_02_alt 5000;
BA_REL_ "GenSigTimeoutTime" BU_SG_REL_ SDC2 SG_ 1714 Kombi_02_alt 5000;
BA_REL_ "GenSigTimeoutTime" BU_SG_REL_ ABT_1_MIB_ab_Gen3 SG_ 1714 Uhrzeit_01_alt 5000;
BA_REL_ "GenSigTimeoutTime" BU_SG_REL_ ExBox SG_ 1714 Uhrzeit_01_alt 5000;
BA_REL_ "GenSigTimeoutTime" BU_SG_REL_ SCC1 SG_ 1714 Uhrzeit_01_alt 5000;
BA_REL_ "GenSigTimeoutTime" BU_SG_REL_ SCC2 SG_ 1714 Uhrzeit_01_alt 5000;
BA_REL_ "GenSigTimeoutTime" BU_SG_REL_ SDC1 SG_ 1714 Uhrzeit_01_alt 5000;
BA_REL_ "GenSigTimeoutTime" BU_SG_REL_ SDC2 SG_ 1714 Uhrzeit_01_alt 5000;
BA_REL_ "GenSigTimeoutTime" BU_SG_REL_ ABT_1_MIB_ab_Gen3 SG_ 1520 DI_KL_58xd 2000;
BA_REL_ "GenSigTimeoutTime" BU_SG_REL_ ABT_1_MQB SG_ 1520 DI_KL_58xd 2000;
BA_REL_ "GenSigTimeoutTime" BU_SG_REL_ BT_1_MQB SG_ 1520 DI_KL_58xd 2000;
BA_REL_ "GenSigTimeoutTime" BU_SG_REL_ DU_1_MQB SG_ 1520 DI_KL_58xd 2000;
BA_REL_ "GenSigTimeoutTime" BU_SG_REL_ DU_2 SG_ 1520 DI_KL_58xd 2000;
BA_REL_ "GenSigTimeoutTime" BU_SG_REL_ DU_3 SG_ 1520 DI_KL_58xd 2000;
BA_REL_ "GenSigTimeoutTime" BU_SG_REL_ DU_4 SG_ 1520 DI_KL_58xd 2000;
BA_REL_ "GenSigTimeoutTime" BU_SG_REL_ ExBox SG_ 1520 DI_KL_58xd 2000;
BA_REL_ "GenSigTimeoutTime" BU_SG_REL_ LSR_1 SG_ 1520 DI_KL_58xd 2000;
BA_REL_ "GenSigTimeoutTime" BU_SG_REL_ SDC1 SG_ 1520 DI_KL_58xd 2000;
BA_REL_ "GenSigTimeoutTime" BU_SG_REL_ SDC2 SG_ 1520 DI_KL_58xd 2000;
BA_REL_ "GenSigTimeoutTime" BU_SG_REL_ ABT_1_MIB_ab_Gen3 SG_ 1520 DI_KL_58xs 2000;
BA_REL_ "GenSigTimeoutTime" BU_SG_REL_ ABT_1_MQB SG_ 1520 DI_KL_58xs 2000;
BA_REL_ "GenSigTimeoutTime" BU_SG_REL_ BT_1_MQB SG_ 1520 DI_KL_58xs 2000;
BA_REL_ "GenSigTimeoutTime" BU_SG_REL_ DU_1_MQB SG_ 1520 DI_KL_58xs 2000;
BA_REL_ "GenSigTimeoutTime" BU_SG_REL_ DU_2 SG_ 1520 DI_KL_58xs 2000;
BA_REL_ "GenSigTimeoutTime" BU_SG_REL_ DU_3 SG_ 1520 DI_KL_58xs 2000;
BA_REL_ "GenSigTimeoutTime" BU_SG_REL_ DU_4 SG_ 1520 DI_KL_58xs 2000;
BA_REL_ "GenSigTimeoutTime" BU_SG_REL_ ExBox SG_ 1520 DI_KL_58xs 2000;
BA_REL_ "GenSigTimeoutTime" BU_SG_REL_ LSR_1 SG_ 1520 DI_KL_58xs 2000;
BA_REL_ "GenSigTimeoutTime" BU_SG_REL_ SDC1 SG_ 1520 DI_KL_58xs 2000;
BA_REL_ "GenSigTimeoutTime" BU_SG_REL_ SDC2 SG_ 1520 DI_KL_58xs 2000;
BA_REL_ "GenSigTimeoutTime" BU_SG_REL_ DU_2 SG_ 1520 DI_Display_Nachtdesign 2000;
BA_REL_ "GenSigTimeoutTime" BU_SG_REL_ DU_3 SG_ 1520 DI_Display_Nachtdesign 2000;
BA_REL_ "GenSigTimeoutTime" BU_SG_REL_ DU_4 SG_ 1520 DI_Display_Nachtdesign 2000;
BA_REL_ "GenSigTimeoutTime" BU_SG_REL_ ExBox SG_ 1520 DI_Display_Nachtdesign 2000;
BA_REL_ "GenSigTimeoutTime" BU_SG_REL_ ZR_Entry SG_ 1142 DU_State 5000;
BA_REL_ "GenSigTimeoutTime" BU_SG_REL_ ZR_High SG_ 1142 DU_State 5000;
BA_REL_ "GenSigTimeoutTime" BU_SG_REL_ ZR_High_Korea SG_ 1142 DU_State 5000;
BA_REL_ "GenSigTimeoutTime" BU_SG_REL_ ZR_High_TT3 SG_ 1142 DU_State 5000;
BA_REL_ "GenSigTimeoutTime" BU_SG_REL_ ZR_MIB_OPTION_ab_Gen3 SG_ 1142 DU_State 5000;
BA_REL_ "GenSigTimeoutTime" BU_SG_REL_ ZR_MIB_TOP_ab_Gen3 SG_ 1142 DU_State 5000;
BA_REL_ "GenSigTimeoutTime" BU_SG_REL_ ZR_Standard SG_ 1142 DU_State 5000;
BA_REL_ "GenSigTimeoutTime" BU_SG_REL_ ZR_Entry SG_ 1142 SystemMode 5000;
BA_REL_ "GenSigTimeoutTime" BU_SG_REL_ ZR_High SG_ 1142 SystemMode 5000;
BA_REL_ "GenSigTimeoutTime" BU_SG_REL_ ZR_High_Korea SG_ 1142 SystemMode 5000;
BA_REL_ "GenSigTimeoutTime" BU_SG_REL_ ZR_High_TT3 SG_ 1142 SystemMode 5000;
BA_REL_ "GenSigTimeoutTime" BU_SG_REL_ ZR_MIB_OPTION_ab_Gen3 SG_ 1142 SystemMode 5000;
BA_REL_ "GenSigTimeoutTime" BU_SG_REL_ ZR_MIB_TOP_ab_Gen3 SG_ 1142 SystemMode 5000;
BA_REL_ "GenSigTimeoutTime" BU_SG_REL_ ZR_Standard SG_ 1142 SystemMode 5000;
BA_REL_ "GenSigTimeoutTime" BU_SG_REL_ ZR_Entry SG_ 1142 DU_Temp_Fehler 5000;
BA_REL_ "GenSigTimeoutTime" BU_SG_REL_ ZR_High SG_ 1142 DU_Temp_Fehler 5000;
BA_REL_ "GenSigTimeoutTime" BU_SG_REL_ ZR_High_Korea SG_ 1142 DU_Temp_Fehler 5000;
BA_REL_ "GenSigTimeoutTime" BU_SG_REL_ ZR_High_TT3 SG_ 1142 DU_Temp_Fehler 5000;
BA_REL_ "GenSigTimeoutTime" BU_SG_REL_ ZR_MIB_OPTION_ab_Gen3 SG_ 1142 DU_Temp_Fehler 5000;
BA_REL_ "GenSigTimeoutTime" BU_SG_REL_ ZR_MIB_TOP_ab_Gen3 SG_ 1142 DU_Temp_Fehler 5000;
BA_REL_ "GenSigTimeoutTime" BU_SG_REL_ ZR_Standard SG_ 1142 DU_Temp_Fehler 5000;
BA_REL_ "GenSigTimeoutTime" BU_SG_REL_ ZR_Entry SG_ 1142 DU_KL30_Uebersp_Fehler 5000;
BA_REL_ "GenSigTimeoutTime" BU_SG_REL_ ZR_High SG_ 1142 DU_KL30_Uebersp_Fehler 5000;
BA_REL_ "GenSigTimeoutTime" BU_SG_REL_ ZR_High_Korea SG_ 1142 DU_KL30_Uebersp_Fehler 5000;
BA_REL_ "GenSigTimeoutTime" BU_SG_REL_ ZR_High_TT3 SG_ 1142 DU_KL30_Uebersp_Fehler 5000;
BA_REL_ "GenSigTimeoutTime" BU_SG_REL_ ZR_MIB_OPTION_ab_Gen3 SG_ 1142 DU_KL30_Uebersp_Fehler 5000;
BA_REL_ "GenSigTimeoutTime" BU_SG_REL_ ZR_MIB_TOP_ab_Gen3 SG_ 1142 DU_KL30_Uebersp_Fehler 5000;
BA_REL_ "GenSigTimeoutTime" BU_SG_REL_ ZR_Standard SG_ 1142 DU_KL30_Uebersp_Fehler 5000;
BA_REL_ "GenSigTimeoutTime" BU_SG_REL_ ZR_Entry SG_ 1142 DU_KL30_Untersp_Fehler 5000;
BA_REL_ "GenSigTimeoutTime" BU_SG_REL_ ZR_High SG_ 1142 DU_KL30_Untersp_Fehler 5000;
BA_REL_ "GenSigTimeoutTime" BU_SG_REL_ ZR_High_Korea SG_ 1142 DU_KL30_Untersp_Fehler 5000;
BA_REL_ "GenSigTimeoutTime" BU_SG_REL_ ZR_High_TT3 SG_ 1142 DU_KL30_Untersp_Fehler 5000;
BA_REL_ "GenSigTimeoutTime" BU_SG_REL_ ZR_MIB_OPTION_ab_Gen3 SG_ 1142 DU_KL30_Untersp_Fehler 5000;
BA_REL_ "GenSigTimeoutTime" BU_SG_REL_ ZR_MIB_TOP_ab_Gen3 SG_ 1142 DU_KL30_Untersp_Fehler 5000;
BA_REL_ "GenSigTimeoutTime" BU_SG_REL_ ZR_Standard SG_ 1142 DU_KL30_Untersp_Fehler 5000;
BA_REL_ "GenSigTimeoutTime" BU_SG_REL_ DU_2 SG_ 1142 DU_DispDerating 5000;
BA_REL_ "GenSigTimeoutTime" BU_SG_REL_ DU_4 SG_ 1142 DU_DispDerating 5000;
BA_REL_ "GenSigTimeoutTime" BU_SG_REL_ ZR_Entry SG_ 1142 DU_DispDerating 5000;
BA_REL_ "GenSigTimeoutTime" BU_SG_REL_ ZR_High SG_ 1142 DU_DispDerating 5000;
BA_REL_ "GenSigTimeoutTime" BU_SG_REL_ ZR_High_Korea SG_ 1142 DU_DispDerating 5000;
BA_REL_ "GenSigTimeoutTime" BU_SG_REL_ ZR_High_TT3 SG_ 1142 DU_DispDerating 5000;
BA_REL_ "GenSigTimeoutTime" BU_SG_REL_ ZR_MIB_OPTION_ab_Gen3 SG_ 1142 DU_DispDerating 5000;
BA_REL_ "GenSigTimeoutTime" BU_SG_REL_ ZR_MIB_TOP_ab_Gen3 SG_ 1142 DU_DispDerating 5000;
BA_REL_ "GenSigTimeoutTime" BU_SG_REL_ ZR_Standard SG_ 1142 DU_DispDerating 5000;
BA_REL_ "GenSigTimeoutTime" BU_SG_REL_ ZR_Entry SG_ 1142 DU_KL_30F 5000;
BA_REL_ "GenSigTimeoutTime" BU_SG_REL_ ZR_High SG_ 1142 DU_KL_30F 5000;
BA_REL_ "GenSigTimeoutTime" BU_SG_REL_ ZR_High_Korea SG_ 1142 DU_KL_30F 5000;
BA_REL_ "GenSigTimeoutTime" BU_SG_REL_ ZR_High_TT3 SG_ 1142 DU_KL_30F 5000;
BA_REL_ "GenSigTimeoutTime" BU_SG_REL_ ZR_MIB_OPTION_ab_Gen3 SG_ 1142 DU_KL_30F 5000;
BA_REL_ "GenSigTimeoutTime" BU_SG_REL_ ZR_MIB_TOP_ab_Gen3 SG_ 1142 DU_KL_30F 5000;
BA_REL_ "GenSigTimeoutTime" BU_SG_REL_ ZR_Standard SG_ 1142 DU_KL_30F 5000;
BA_REL_ "GenSigTimeoutTime" BU_SG_REL_ BT_1_MQB SG_ 1142 DU_TempSens 5000;
BA_REL_ "GenSigTimeoutTime" BU_SG_REL_ ZR_Entry SG_ 1142 DU_TempSens 5000;
BA_REL_ "GenSigTimeoutTime" BU_SG_REL_ ZR_High SG_ 1142 DU_TempSens 5000;
BA_REL_ "GenSigTimeoutTime" BU_SG_REL_ ZR_High_Korea SG_ 1142 DU_TempSens 5000;
BA_REL_ "GenSigTimeoutTime" BU_SG_REL_ ZR_High_TT3 SG_ 1142 DU_TempSens 5000;
BA_REL_ "GenSigTimeoutTime" BU_SG_REL_ ZR_MIB_OPTION_ab_Gen3 SG_ 1142 DU_TempSens 5000;
BA_REL_ "GenSigTimeoutTime" BU_SG_REL_ ZR_MIB_TOP_ab_Gen3 SG_ 1142 DU_TempSens 5000;
BA_REL_ "GenSigTimeoutTime" BU_SG_REL_ ZR_Standard SG_ 1142 DU_TempSens 5000;
BA_REL_ "GenSigTimeoutTime" BU_SG_REL_ ZR_Entry SG_ 1142 DU_TempSensMax 5000;
BA_REL_ "GenSigTimeoutTime" BU_SG_REL_ ZR_High SG_ 1142 DU_TempSensMax 5000;
BA_REL_ "GenSigTimeoutTime" BU_SG_REL_ ZR_High_Korea SG_ 1142 DU_TempSensMax 5000;
BA_REL_ "GenSigTimeoutTime" BU_SG_REL_ ZR_High_TT3 SG_ 1142 DU_TempSensMax 5000;
BA_REL_ "GenSigTimeoutTime" BU_SG_REL_ ZR_MIB_OPTION_ab_Gen3 SG_ 1142 DU_TempSensMax 5000;
BA_REL_ "GenSigTimeoutTime" BU_SG_REL_ ZR_MIB_TOP_ab_Gen3 SG_ 1142 DU_TempSensMax 5000;
BA_REL_ "GenSigTimeoutTime" BU_SG_REL_ ZR_Standard SG_ 1142 DU_TempSensMax 5000;
BA_REL_ "GenSigTimeoutTime" BU_SG_REL_ BT_1_MQB SG_ 1142 DU_Variant 5000;
BA_REL_ "GenSigTimeoutTime" BU_SG_REL_ ZR_Entry SG_ 1142 DU_Variant 5000;
BA_REL_ "GenSigTimeoutTime" BU_SG_REL_ ZR_High SG_ 1142 DU_Variant 5000;
BA_REL_ "GenSigTimeoutTime" BU_SG_REL_ ZR_High_Korea SG_ 1142 DU_Variant 5000;
BA_REL_ "GenSigTimeoutTime" BU_SG_REL_ ZR_High_TT3 SG_ 1142 DU_Variant 5000;
BA_REL_ "GenSigTimeoutTime" BU_SG_REL_ ZR_MIB_OPTION_ab_Gen3 SG_ 1142 DU_Variant 5000;
BA_REL_ "GenSigTimeoutTime" BU_SG_REL_ ZR_MIB_TOP_ab_Gen3 SG_ 1142 DU_Variant 5000;
BA_REL_ "GenSigTimeoutTime" BU_SG_REL_ ZR_Standard SG_ 1142 DU_Variant 5000;
BA_REL_ "GenSigTimeoutTime" BU_SG_REL_ ZR_Entry SG_ 1142 DU_Zulieferer 5000;
BA_REL_ "GenSigTimeoutTime" BU_SG_REL_ ZR_High SG_ 1142 DU_Zulieferer 5000;
BA_REL_ "GenSigTimeoutTime" BU_SG_REL_ ZR_High_Korea SG_ 1142 DU_Zulieferer 5000;
BA_REL_ "GenSigTimeoutTime" BU_SG_REL_ ZR_High_TT3 SG_ 1142 DU_Zulieferer 5000;
BA_REL_ "GenSigTimeoutTime" BU_SG_REL_ ZR_MIB_OPTION_ab_Gen3 SG_ 1142 DU_Zulieferer 5000;
BA_REL_ "GenSigTimeoutTime" BU_SG_REL_ ZR_MIB_TOP_ab_Gen3 SG_ 1142 DU_Zulieferer 5000;
BA_REL_ "GenSigTimeoutTime" BU_SG_REL_ ZR_Standard SG_ 1142 DU_Zulieferer 5000;
BA_REL_ "GenSigTimeoutTime" BU_SG_REL_ ZR_High SG_ 1142 HU_Fotosensor 5000;
BA_REL_ "GenSigTimeoutTime" BU_SG_REL_ ZR_MIB_OPTION_ab_Gen3 SG_ 1142 HU_Fotosensor 5000;
BA_REL_ "GenSigTimeoutTime" BU_SG_REL_ ZR_MIB_TOP_ab_Gen3 SG_ 1142 HU_Fotosensor 5000;
BA_REL_ "GenSigTimeoutTime" BU_SG_REL_ ZR_Standard SG_ 1142 HU_Fotosensor 5000;
BA_REL_ "GenSigTimeoutTime" BU_SG_REL_ ZR_Entry SG_ 1143 DU_Betriebsdauer_min 5000;
BA_REL_ "GenSigTimeoutTime" BU_SG_REL_ ZR_High SG_ 1143 DU_Betriebsdauer_min 5000;
BA_REL_ "GenSigTimeoutTime" BU_SG_REL_ ZR_High_Korea SG_ 1143 DU_Betriebsdauer_min 5000;
BA_REL_ "GenSigTimeoutTime" BU_SG_REL_ ZR_High_TT3 SG_ 1143 DU_Betriebsdauer_min 5000;
BA_REL_ "GenSigTimeoutTime" BU_SG_REL_ ZR_MIB_OPTION_ab_Gen3 SG_ 1143 DU_Betriebsdauer_min 5000;
BA_REL_ "GenSigTimeoutTime" BU_SG_REL_ ZR_MIB_TOP_ab_Gen3 SG_ 1143 DU_Betriebsdauer_min 5000;
BA_REL_ "GenSigTimeoutTime" BU_SG_REL_ ZR_Standard SG_ 1143 DU_Betriebsdauer_min 5000;
BA_REL_ "GenSigTimeoutTime" BU_SG_REL_ ZR_Entry SG_ 1143 DU_Betriebsdauer_std 5000;
BA_REL_ "GenSigTimeoutTime" BU_SG_REL_ ZR_High SG_ 1143 DU_Betriebsdauer_std 5000;
BA_REL_ "GenSigTimeoutTime" BU_SG_REL_ ZR_High_Korea SG_ 1143 DU_Betriebsdauer_std 5000;
BA_REL_ "GenSigTimeoutTime" BU_SG_REL_ ZR_High_TT3 SG_ 1143 DU_Betriebsdauer_std 5000;
BA_REL_ "GenSigTimeoutTime" BU_SG_REL_ ZR_MIB_OPTION_ab_Gen3 SG_ 1143 DU_Betriebsdauer_std 5000;
BA_REL_ "GenSigTimeoutTime" BU_SG_REL_ ZR_MIB_TOP_ab_Gen3 SG_ 1143 DU_Betriebsdauer_std 5000;
BA_REL_ "GenSigTimeoutTime" BU_SG_REL_ ZR_Standard SG_ 1143 DU_Betriebsdauer_std 5000;
BA_REL_ "GenSigTimeoutTime" BU_SG_REL_ ZR_Entry SG_ 1143 DU_HintGrdBelKurzschl 5000;
BA_REL_ "GenSigTimeoutTime" BU_SG_REL_ ZR_High SG_ 1143 DU_HintGrdBelKurzschl 5000;
BA_REL_ "GenSigTimeoutTime" BU_SG_REL_ ZR_High_Korea SG_ 1143 DU_HintGrdBelKurzschl 5000;
BA_REL_ "GenSigTimeoutTime" BU_SG_REL_ ZR_High_TT3 SG_ 1143 DU_HintGrdBelKurzschl 5000;
BA_REL_ "GenSigTimeoutTime" BU_SG_REL_ ZR_MIB_OPTION_ab_Gen3 SG_ 1143 DU_HintGrdBelKurzschl 5000;
BA_REL_ "GenSigTimeoutTime" BU_SG_REL_ ZR_MIB_TOP_ab_Gen3 SG_ 1143 DU_HintGrdBelKurzschl 5000;
BA_REL_ "GenSigTimeoutTime" BU_SG_REL_ ZR_Standard SG_ 1143 DU_HintGrdBelKurzschl 5000;
BA_REL_ "GenSigTimeoutTime" BU_SG_REL_ ZR_Entry SG_ 1143 DU_HintGrdBelUnterbr 5000;
BA_REL_ "GenSigTimeoutTime" BU_SG_REL_ ZR_High SG_ 1143 DU_HintGrdBelUnterbr 5000;
BA_REL_ "GenSigTimeoutTime" BU_SG_REL_ ZR_High_Korea SG_ 1143 DU_HintGrdBelUnterbr 5000;
BA_REL_ "GenSigTimeoutTime" BU_SG_REL_ ZR_High_TT3 SG_ 1143 DU_HintGrdBelUnterbr 5000;
BA_REL_ "GenSigTimeoutTime" BU_SG_REL_ ZR_MIB_OPTION_ab_Gen3 SG_ 1143 DU_HintGrdBelUnterbr 5000;
BA_REL_ "GenSigTimeoutTime" BU_SG_REL_ ZR_MIB_TOP_ab_Gen3 SG_ 1143 DU_HintGrdBelUnterbr 5000;
BA_REL_ "GenSigTimeoutTime" BU_SG_REL_ ZR_Standard SG_ 1143 DU_HintGrdBelUnterbr 5000;
BA_REL_ "GenSigTimeoutTime" BU_SG_REL_ ZR_Entry SG_ 1143 EEPROM_Fehler 5000;
BA_REL_ "GenSigTimeoutTime" BU_SG_REL_ ZR_High SG_ 1143 EEPROM_Fehler 5000;
BA_REL_ "GenSigTimeoutTime" BU_SG_REL_ ZR_High_Korea SG_ 1143 EEPROM_Fehler 5000;
BA_REL_ "GenSigTimeoutTime" BU_SG_REL_ ZR_High_TT3 SG_ 1143 EEPROM_Fehler 5000;
BA_REL_ "GenSigTimeoutTime" BU_SG_REL_ ZR_MIB_OPTION_ab_Gen3 SG_ 1143 EEPROM_Fehler 5000;
BA_REL_ "GenSigTimeoutTime" BU_SG_REL_ ZR_MIB_TOP_ab_Gen3 SG_ 1143 EEPROM_Fehler 5000;
BA_REL_ "GenSigTimeoutTime" BU_SG_REL_ ZR_Standard SG_ 1143 EEPROM_Fehler 5000;
BA_REL_ "GenSigTimeoutTime" BU_SG_REL_ ZR_Entry SG_ 1143 DU1_SW_inkonsistent 5000;
BA_REL_ "GenSigTimeoutTime" BU_SG_REL_ ZR_High SG_ 1143 DU1_SW_inkonsistent 5000;
BA_REL_ "GenSigTimeoutTime" BU_SG_REL_ ZR_High_Korea SG_ 1143 DU1_SW_inkonsistent 5000;
BA_REL_ "GenSigTimeoutTime" BU_SG_REL_ ZR_High_TT3 SG_ 1143 DU1_SW_inkonsistent 5000;
BA_REL_ "GenSigTimeoutTime" BU_SG_REL_ ZR_MIB_OPTION_ab_Gen3 SG_ 1143 DU1_SW_inkonsistent 5000;
BA_REL_ "GenSigTimeoutTime" BU_SG_REL_ ZR_MIB_TOP_ab_Gen3 SG_ 1143 DU1_SW_inkonsistent 5000;
BA_REL_ "GenSigTimeoutTime" BU_SG_REL_ ZR_Standard SG_ 1143 DU1_SW_inkonsistent 5000;
BA_REL_ "GenSigTimeoutTime" BU_SG_REL_ ZR_Entry SG_ 1143 DU1_HDCP_Status 5000;
BA_REL_ "GenSigTimeoutTime" BU_SG_REL_ ZR_High SG_ 1143 DU1_HDCP_Status 5000;
BA_REL_ "GenSigTimeoutTime" BU_SG_REL_ ZR_High_Korea SG_ 1143 DU1_HDCP_Status 5000;
BA_REL_ "GenSigTimeoutTime" BU_SG_REL_ ZR_High_TT3 SG_ 1143 DU1_HDCP_Status 5000;
BA_REL_ "GenSigTimeoutTime" BU_SG_REL_ ZR_MIB_OPTION_ab_Gen3 SG_ 1143 DU1_HDCP_Status 5000;
BA_REL_ "GenSigTimeoutTime" BU_SG_REL_ ZR_MIB_TOP_ab_Gen3 SG_ 1143 DU1_HDCP_Status 5000;
BA_REL_ "GenSigTimeoutTime" BU_SG_REL_ ZR_Standard SG_ 1143 DU1_HDCP_Status 5000;
BA_REL_ "GenSigTimeoutTime" BU_SG_REL_ ZR_Entry SG_ 1143 LVDS_Status 5000;
BA_REL_ "GenSigTimeoutTime" BU_SG_REL_ ZR_High SG_ 1143 LVDS_Status 5000;
BA_REL_ "GenSigTimeoutTime" BU_SG_REL_ ZR_High_Korea SG_ 1143 LVDS_Status 5000;
BA_REL_ "GenSigTimeoutTime" BU_SG_REL_ ZR_High_TT3 SG_ 1143 LVDS_Status 5000;
BA_REL_ "GenSigTimeoutTime" BU_SG_REL_ ZR_MIB_OPTION_ab_Gen3 SG_ 1143 LVDS_Status 5000;
BA_REL_ "GenSigTimeoutTime" BU_SG_REL_ ZR_MIB_TOP_ab_Gen3 SG_ 1143 LVDS_Status 5000;
BA_REL_ "GenSigTimeoutTime" BU_SG_REL_ ZR_Standard SG_ 1143 LVDS_Status 5000;
BA_REL_ "GenSigTimeoutTime" BU_SG_REL_ ZR_Entry SG_ 1143 DU1_Touch_Fehlerstatus 5000;
BA_REL_ "GenSigTimeoutTime" BU_SG_REL_ ZR_High SG_ 1143 DU1_Touch_Fehlerstatus 5000;
BA_REL_ "GenSigTimeoutTime" BU_SG_REL_ ZR_High_Korea SG_ 1143 DU1_Touch_Fehlerstatus 5000;
BA_REL_ "GenSigTimeoutTime" BU_SG_REL_ ZR_High_TT3 SG_ 1143 DU1_Touch_Fehlerstatus 5000;
BA_REL_ "GenSigTimeoutTime" BU_SG_REL_ ZR_MIB_OPTION_ab_Gen3 SG_ 1143 DU1_Touch_Fehlerstatus 5000;
BA_REL_ "GenSigTimeoutTime" BU_SG_REL_ ZR_MIB_TOP_ab_Gen3 SG_ 1143 DU1_Touch_Fehlerstatus 5000;
BA_REL_ "GenSigTimeoutTime" BU_SG_REL_ ZR_Standard SG_ 1143 DU1_Touch_Fehlerstatus 5000;
BA_REL_ "GenSigTimeoutTime" BU_SG_REL_ ZR_Entry SG_ 1143 DU1_Haptik_Fehlerstatus 5000;
BA_REL_ "GenSigTimeoutTime" BU_SG_REL_ ZR_High SG_ 1143 DU1_Haptik_Fehlerstatus 5000;
BA_REL_ "GenSigTimeoutTime" BU_SG_REL_ ZR_High_Korea SG_ 1143 DU1_Haptik_Fehlerstatus 5000;
BA_REL_ "GenSigTimeoutTime" BU_SG_REL_ ZR_High_TT3 SG_ 1143 DU1_Haptik_Fehlerstatus 5000;
BA_REL_ "GenSigTimeoutTime" BU_SG_REL_ ZR_MIB_OPTION_ab_Gen3 SG_ 1143 DU1_Haptik_Fehlerstatus 5000;
BA_REL_ "GenSigTimeoutTime" BU_SG_REL_ ZR_MIB_TOP_ab_Gen3 SG_ 1143 DU1_Haptik_Fehlerstatus 5000;
BA_REL_ "GenSigTimeoutTime" BU_SG_REL_ ZR_Standard SG_ 1143 DU1_Haptik_Fehlerstatus 5000;
BA_REL_ "GenSigTimeoutTime" BU_SG_REL_ ZR_Entry SG_ 1143 DU1_LVDS_Splitter_Fehlerstatus 5000;
BA_REL_ "GenSigTimeoutTime" BU_SG_REL_ ZR_High SG_ 1143 DU1_LVDS_Splitter_Fehlerstatus 5000;
BA_REL_ "GenSigTimeoutTime" BU_SG_REL_ ZR_High_Korea SG_ 1143 DU1_LVDS_Splitter_Fehlerstatus 5000;
BA_REL_ "GenSigTimeoutTime" BU_SG_REL_ ZR_High_TT3 SG_ 1143 DU1_LVDS_Splitter_Fehlerstatus 5000;
BA_REL_ "GenSigTimeoutTime" BU_SG_REL_ ZR_MIB_OPTION_ab_Gen3 SG_ 1143 DU1_LVDS_Splitter_Fehlerstatus 5000;
BA_REL_ "GenSigTimeoutTime" BU_SG_REL_ ZR_MIB_TOP_ab_Gen3 SG_ 1143 DU1_LVDS_Splitter_Fehlerstatus 5000;
BA_REL_ "GenSigTimeoutTime" BU_SG_REL_ ZR_Standard SG_ 1143 DU1_LVDS_Splitter_Fehlerstatus 5000;
BA_REL_ "GenSigTimeoutTime" BU_SG_REL_ ZR_MIB_OPTION_ab_Gen3 SG_ 561 DU1_KS_aktiv_anderer_Grund 2000;
BA_REL_ "GenSigTimeoutTime" BU_SG_REL_ ZR_MIB_OPTION_ab_Gen3 SG_ 561 DU1_KS_aktiv_falsche_Auth 2000;
BA_REL_ "GenSigTimeoutTime" BU_SG_REL_ ZR_MIB_OPTION_ab_Gen3 SG_ 561 DU1_KS_aktiv_Manipulationsschutz 2000;
BA_REL_ "GenSigTimeoutTime" BU_SG_REL_ ZR_MIB_OPTION_ab_Gen3 SG_ 561 DU1_KS_FIS_unplausibel 2000;
BA_REL_ "GenSigTimeoutTime" BU_SG_REL_ ZR_MIB_OPTION_ab_Gen3 SG_ 561 DU1_KS_keine_Grundeinstellung 2000;
BA_REL_ "GenSigTimeoutTime" BU_SG_REL_ ZR_MIB_OPTION_ab_Gen3 SG_ 561 DU1_KS_SHE_keine_Grundeinst 2000;
BA_REL_ "GenSigTimeoutTime" BU_SG_REL_ ZR_High SG_ 1144 DU2_State 5000;
BA_REL_ "GenSigTimeoutTime" BU_SG_REL_ ZR_MIB_OPTION_ab_Gen3 SG_ 1144 DU2_State 5000;
BA_REL_ "GenSigTimeoutTime" BU_SG_REL_ ZR_MIB_TOP_ab_Gen3 SG_ 1144 DU2_State 5000;
BA_REL_ "GenSigTimeoutTime" BU_SG_REL_ ZR_Standard SG_ 1144 DU2_State 5000;
BA_REL_ "GenSigTimeoutTime" BU_SG_REL_ ZR_High SG_ 1144 DU2_SystemMode 5000;
BA_REL_ "GenSigTimeoutTime" BU_SG_REL_ ZR_MIB_OPTION_ab_Gen3 SG_ 1144 DU2_SystemMode 5000;
BA_REL_ "GenSigTimeoutTime" BU_SG_REL_ ZR_MIB_TOP_ab_Gen3 SG_ 1144 DU2_SystemMode 5000;
BA_REL_ "GenSigTimeoutTime" BU_SG_REL_ ZR_Standard SG_ 1144 DU2_SystemMode 5000;
BA_REL_ "GenSigTimeoutTime" BU_SG_REL_ ZR_High SG_ 1144 DU2_Temp_Fehler 5000;
BA_REL_ "GenSigTimeoutTime" BU_SG_REL_ ZR_MIB_OPTION_ab_Gen3 SG_ 1144 DU2_Temp_Fehler 5000;
BA_REL_ "GenSigTimeoutTime" BU_SG_REL_ ZR_MIB_TOP_ab_Gen3 SG_ 1144 DU2_Temp_Fehler 5000;
BA_REL_ "GenSigTimeoutTime" BU_SG_REL_ ZR_Standard SG_ 1144 DU2_Temp_Fehler 5000;
BA_REL_ "GenSigTimeoutTime" BU_SG_REL_ ZR_High SG_ 1144 DU2_KL30_Uebersp_Fehler 5000;
BA_REL_ "GenSigTimeoutTime" BU_SG_REL_ ZR_MIB_OPTION_ab_Gen3 SG_ 1144 DU2_KL30_Uebersp_Fehler 5000;
BA_REL_ "GenSigTimeoutTime" BU_SG_REL_ ZR_MIB_TOP_ab_Gen3 SG_ 1144 DU2_KL30_Uebersp_Fehler 5000;
BA_REL_ "GenSigTimeoutTime" BU_SG_REL_ ZR_Standard SG_ 1144 DU2_KL30_Uebersp_Fehler 5000;
BA_REL_ "GenSigTimeoutTime" BU_SG_REL_ ZR_High SG_ 1144 DU2_KL30_Untersp_Fehler 5000;
BA_REL_ "GenSigTimeoutTime" BU_SG_REL_ ZR_MIB_OPTION_ab_Gen3 SG_ 1144 DU2_KL30_Untersp_Fehler 5000;
BA_REL_ "GenSigTimeoutTime" BU_SG_REL_ ZR_MIB_TOP_ab_Gen3 SG_ 1144 DU2_KL30_Untersp_Fehler 5000;
BA_REL_ "GenSigTimeoutTime" BU_SG_REL_ ZR_Standard SG_ 1144 DU2_KL30_Untersp_Fehler 5000;
BA_REL_ "GenSigTimeoutTime" BU_SG_REL_ ZR_High SG_ 1144 DU2_FB_Mode 5000;
BA_REL_ "GenSigTimeoutTime" BU_SG_REL_ ZR_MIB_OPTION_ab_Gen3 SG_ 1144 DU2_FB_Mode 5000;
BA_REL_ "GenSigTimeoutTime" BU_SG_REL_ ZR_MIB_TOP_ab_Gen3 SG_ 1144 DU2_FB_Mode 5000;
BA_REL_ "GenSigTimeoutTime" BU_SG_REL_ ZR_Standard SG_ 1144 DU2_FB_Mode 5000;
BA_REL_ "GenSigTimeoutTime" BU_SG_REL_ DU_1_MQB SG_ 1144 DU2_DispDerating 5000;
BA_REL_ "GenSigTimeoutTime" BU_SG_REL_ ZR_High SG_ 1144 DU2_DispDerating 5000;
BA_REL_ "GenSigTimeoutTime" BU_SG_REL_ ZR_MIB_OPTION_ab_Gen3 SG_ 1144 DU2_DispDerating 5000;
BA_REL_ "GenSigTimeoutTime" BU_SG_REL_ ZR_MIB_TOP_ab_Gen3 SG_ 1144 DU2_DispDerating 5000;
BA_REL_ "GenSigTimeoutTime" BU_SG_REL_ ZR_Standard SG_ 1144 DU2_DispDerating 5000;
BA_REL_ "GenSigTimeoutTime" BU_SG_REL_ ZR_High SG_ 1144 DU2_KL_30F 5000;
BA_REL_ "GenSigTimeoutTime" BU_SG_REL_ ZR_MIB_OPTION_ab_Gen3 SG_ 1144 DU2_KL_30F 5000;
BA_REL_ "GenSigTimeoutTime" BU_SG_REL_ ZR_MIB_TOP_ab_Gen3 SG_ 1144 DU2_KL_30F 5000;
BA_REL_ "GenSigTimeoutTime" BU_SG_REL_ ZR_Standard SG_ 1144 DU2_KL_30F 5000;
BA_REL_ "GenSigTimeoutTime" BU_SG_REL_ ZR_High SG_ 1144 DU2_TempSens 5000;
BA_REL_ "GenSigTimeoutTime" BU_SG_REL_ ZR_MIB_OPTION_ab_Gen3 SG_ 1144 DU2_TempSens 5000;
BA_REL_ "GenSigTimeoutTime" BU_SG_REL_ ZR_MIB_TOP_ab_Gen3 SG_ 1144 DU2_TempSens 5000;
BA_REL_ "GenSigTimeoutTime" BU_SG_REL_ ZR_Standard SG_ 1144 DU2_TempSens 5000;
BA_REL_ "GenSigTimeoutTime" BU_SG_REL_ ZR_High SG_ 1144 DU2_TempSensMax 5000;
BA_REL_ "GenSigTimeoutTime" BU_SG_REL_ ZR_MIB_OPTION_ab_Gen3 SG_ 1144 DU2_TempSensMax 5000;
BA_REL_ "GenSigTimeoutTime" BU_SG_REL_ ZR_MIB_TOP_ab_Gen3 SG_ 1144 DU2_TempSensMax 5000;
BA_REL_ "GenSigTimeoutTime" BU_SG_REL_ ZR_Standard SG_ 1144 DU2_TempSensMax 5000;
BA_REL_ "GenSigTimeoutTime" BU_SG_REL_ ZR_High SG_ 1144 DU2_Variant 5000;
BA_REL_ "GenSigTimeoutTime" BU_SG_REL_ ZR_MIB_OPTION_ab_Gen3 SG_ 1144 DU2_Variant 5000;
BA_REL_ "GenSigTimeoutTime" BU_SG_REL_ ZR_MIB_TOP_ab_Gen3 SG_ 1144 DU2_Variant 5000;
BA_REL_ "GenSigTimeoutTime" BU_SG_REL_ ZR_Standard SG_ 1144 DU2_Variant 5000;
BA_REL_ "GenSigTimeoutTime" BU_SG_REL_ ZR_High SG_ 1144 DU2_Zulieferer 5000;
BA_REL_ "GenSigTimeoutTime" BU_SG_REL_ ZR_MIB_OPTION_ab_Gen3 SG_ 1144 DU2_Zulieferer 5000;
BA_REL_ "GenSigTimeoutTime" BU_SG_REL_ ZR_MIB_TOP_ab_Gen3 SG_ 1144 DU2_Zulieferer 5000;
BA_REL_ "GenSigTimeoutTime" BU_SG_REL_ ZR_Standard SG_ 1144 DU2_Zulieferer 5000;
BA_REL_ "GenSigTimeoutTime" BU_SG_REL_ ZR_High SG_ 1144 DU2_HU_Fotosensor 5000;
BA_REL_ "GenSigTimeoutTime" BU_SG_REL_ ZR_MIB_OPTION_ab_Gen3 SG_ 1144 DU2_HU_Fotosensor 5000;
BA_REL_ "GenSigTimeoutTime" BU_SG_REL_ ZR_MIB_TOP_ab_Gen3 SG_ 1144 DU2_HU_Fotosensor 5000;
BA_REL_ "GenSigTimeoutTime" BU_SG_REL_ ZR_Standard SG_ 1144 DU2_HU_Fotosensor 5000;
BA_REL_ "GenSigTimeoutTime" BU_SG_REL_ ZR_High SG_ 1145 DU2_Betriebsdauer_min 5000;
BA_REL_ "GenSigTimeoutTime" BU_SG_REL_ ZR_MIB_OPTION_ab_Gen3 SG_ 1145 DU2_Betriebsdauer_min 5000;
BA_REL_ "GenSigTimeoutTime" BU_SG_REL_ ZR_MIB_TOP_ab_Gen3 SG_ 1145 DU2_Betriebsdauer_min 5000;
BA_REL_ "GenSigTimeoutTime" BU_SG_REL_ ZR_Standard SG_ 1145 DU2_Betriebsdauer_min 5000;
BA_REL_ "GenSigTimeoutTime" BU_SG_REL_ ZR_High SG_ 1145 DU2_Betriebsdauer_std 5000;
BA_REL_ "GenSigTimeoutTime" BU_SG_REL_ ZR_MIB_OPTION_ab_Gen3 SG_ 1145 DU2_Betriebsdauer_std 5000;
BA_REL_ "GenSigTimeoutTime" BU_SG_REL_ ZR_MIB_TOP_ab_Gen3 SG_ 1145 DU2_Betriebsdauer_std 5000;
BA_REL_ "GenSigTimeoutTime" BU_SG_REL_ ZR_Standard SG_ 1145 DU2_Betriebsdauer_std 5000;
BA_REL_ "GenSigTimeoutTime" BU_SG_REL_ ZR_High SG_ 1145 DU2_HintGrdBelKurzschl 5000;
BA_REL_ "GenSigTimeoutTime" BU_SG_REL_ ZR_MIB_OPTION_ab_Gen3 SG_ 1145 DU2_HintGrdBelKurzschl 5000;
BA_REL_ "GenSigTimeoutTime" BU_SG_REL_ ZR_MIB_TOP_ab_Gen3 SG_ 1145 DU2_HintGrdBelKurzschl 5000;
BA_REL_ "GenSigTimeoutTime" BU_SG_REL_ ZR_Standard SG_ 1145 DU2_HintGrdBelKurzschl 5000;
BA_REL_ "GenSigTimeoutTime" BU_SG_REL_ ZR_High SG_ 1145 DU2_HintGrdBelUnterbr 5000;
BA_REL_ "GenSigTimeoutTime" BU_SG_REL_ ZR_MIB_OPTION_ab_Gen3 SG_ 1145 DU2_HintGrdBelUnterbr 5000;
BA_REL_ "GenSigTimeoutTime" BU_SG_REL_ ZR_MIB_TOP_ab_Gen3 SG_ 1145 DU2_HintGrdBelUnterbr 5000;
BA_REL_ "GenSigTimeoutTime" BU_SG_REL_ ZR_Standard SG_ 1145 DU2_HintGrdBelUnterbr 5000;
BA_REL_ "GenSigTimeoutTime" BU_SG_REL_ ZR_High SG_ 1145 DU2_EEPROM_Fehler 5000;
BA_REL_ "GenSigTimeoutTime" BU_SG_REL_ ZR_MIB_OPTION_ab_Gen3 SG_ 1145 DU2_EEPROM_Fehler 5000;
BA_REL_ "GenSigTimeoutTime" BU_SG_REL_ ZR_MIB_TOP_ab_Gen3 SG_ 1145 DU2_EEPROM_Fehler 5000;
BA_REL_ "GenSigTimeoutTime" BU_SG_REL_ ZR_Standard SG_ 1145 DU2_EEPROM_Fehler 5000;
BA_REL_ "GenSigTimeoutTime" BU_SG_REL_ ZR_High SG_ 1145 DU2_SW_inkonsistent 5000;
BA_REL_ "GenSigTimeoutTime" BU_SG_REL_ ZR_MIB_OPTION_ab_Gen3 SG_ 1145 DU2_SW_inkonsistent 5000;
BA_REL_ "GenSigTimeoutTime" BU_SG_REL_ ZR_MIB_TOP_ab_Gen3 SG_ 1145 DU2_SW_inkonsistent 5000;
BA_REL_ "GenSigTimeoutTime" BU_SG_REL_ ZR_Standard SG_ 1145 DU2_SW_inkonsistent 5000;
BA_REL_ "GenSigTimeoutTime" BU_SG_REL_ ZR_High SG_ 1145 DU2_HDCP_Status 5000;
BA_REL_ "GenSigTimeoutTime" BU_SG_REL_ ZR_MIB_OPTION_ab_Gen3 SG_ 1145 DU2_HDCP_Status 5000;
BA_REL_ "GenSigTimeoutTime" BU_SG_REL_ ZR_MIB_TOP_ab_Gen3 SG_ 1145 DU2_HDCP_Status 5000;
BA_REL_ "GenSigTimeoutTime" BU_SG_REL_ ZR_Standard SG_ 1145 DU2_HDCP_Status 5000;
BA_REL_ "GenSigTimeoutTime" BU_SG_REL_ ZR_High SG_ 1145 DU2_LVDS_Status 5000;
BA_REL_ "GenSigTimeoutTime" BU_SG_REL_ ZR_MIB_OPTION_ab_Gen3 SG_ 1145 DU2_LVDS_Status 5000;
BA_REL_ "GenSigTimeoutTime" BU_SG_REL_ ZR_MIB_TOP_ab_Gen3 SG_ 1145 DU2_LVDS_Status 5000;
BA_REL_ "GenSigTimeoutTime" BU_SG_REL_ ZR_Standard SG_ 1145 DU2_LVDS_Status 5000;
BA_REL_ "GenSigTimeoutTime" BU_SG_REL_ ZR_High SG_ 1145 DU2_ZR_Lenkerpos_Status 5000;
BA_REL_ "GenSigTimeoutTime" BU_SG_REL_ ZR_MIB_OPTION_ab_Gen3 SG_ 1145 DU2_ZR_Lenkerpos_Status 5000;
BA_REL_ "GenSigTimeoutTime" BU_SG_REL_ ZR_MIB_TOP_ab_Gen3 SG_ 1145 DU2_ZR_Lenkerpos_Status 5000;
BA_REL_ "GenSigTimeoutTime" BU_SG_REL_ ZR_Standard SG_ 1145 DU2_ZR_Lenkerpos_Status 5000;
BA_REL_ "GenSigTimeoutTime" BU_SG_REL_ ZR_High SG_ 1145 DU2_Touch_Fehlerstatus 5000;
BA_REL_ "GenSigTimeoutTime" BU_SG_REL_ ZR_MIB_OPTION_ab_Gen3 SG_ 1145 DU2_Touch_Fehlerstatus 5000;
BA_REL_ "GenSigTimeoutTime" BU_SG_REL_ ZR_MIB_TOP_ab_Gen3 SG_ 1145 DU2_Touch_Fehlerstatus 5000;
BA_REL_ "GenSigTimeoutTime" BU_SG_REL_ ZR_Standard SG_ 1145 DU2_Touch_Fehlerstatus 5000;
BA_REL_ "GenSigTimeoutTime" BU_SG_REL_ ZR_High SG_ 1145 DU2_Haptik_Fehlerstatus 5000;
BA_REL_ "GenSigTimeoutTime" BU_SG_REL_ ZR_MIB_OPTION_ab_Gen3 SG_ 1145 DU2_Haptik_Fehlerstatus 5000;
BA_REL_ "GenSigTimeoutTime" BU_SG_REL_ ZR_MIB_TOP_ab_Gen3 SG_ 1145 DU2_Haptik_Fehlerstatus 5000;
BA_REL_ "GenSigTimeoutTime" BU_SG_REL_ ZR_Standard SG_ 1145 DU2_Haptik_Fehlerstatus 5000;
BA_REL_ "GenSigTimeoutTime" BU_SG_REL_ ZR_High SG_ 1145 DU2_LVDS_Splitter_Fehlerstatus 5000;
BA_REL_ "GenSigTimeoutTime" BU_SG_REL_ ZR_MIB_OPTION_ab_Gen3 SG_ 1145 DU2_LVDS_Splitter_Fehlerstatus 5000;
BA_REL_ "GenSigTimeoutTime" BU_SG_REL_ ZR_MIB_TOP_ab_Gen3 SG_ 1145 DU2_LVDS_Splitter_Fehlerstatus 5000;
BA_REL_ "GenSigTimeoutTime" BU_SG_REL_ ZR_Standard SG_ 1145 DU2_LVDS_Splitter_Fehlerstatus 5000;
BA_REL_ "GenSigTimeoutTime" BU_SG_REL_ ZR_High SG_ 2589283758 DU3_State 5000;
BA_REL_ "GenSigTimeoutTime" BU_SG_REL_ ZR_MIB_TOP_ab_Gen3 SG_ 2589283758 DU3_State 5000;
BA_REL_ "GenSigTimeoutTime" BU_SG_REL_ ZR_High SG_ 2589283758 DU3_SystemMode 5000;
BA_REL_ "GenSigTimeoutTime" BU_SG_REL_ ZR_MIB_TOP_ab_Gen3 SG_ 2589283758 DU3_SystemMode 5000;
BA_REL_ "GenSigTimeoutTime" BU_SG_REL_ ZR_High SG_ 2589283758 DU3_Temp_Fehler 5000;
BA_REL_ "GenSigTimeoutTime" BU_SG_REL_ ZR_MIB_TOP_ab_Gen3 SG_ 2589283758 DU3_Temp_Fehler 5000;
BA_REL_ "GenSigTimeoutTime" BU_SG_REL_ ZR_High SG_ 2589283758 DU3_KL30_Uebersp_Fehler 5000;
BA_REL_ "GenSigTimeoutTime" BU_SG_REL_ ZR_MIB_TOP_ab_Gen3 SG_ 2589283758 DU3_KL30_Uebersp_Fehler 5000;
BA_REL_ "GenSigTimeoutTime" BU_SG_REL_ ZR_High SG_ 2589283758 DU3_KL30_Untersp_Fehler 5000;
BA_REL_ "GenSigTimeoutTime" BU_SG_REL_ ZR_MIB_TOP_ab_Gen3 SG_ 2589283758 DU3_KL30_Untersp_Fehler 5000;
BA_REL_ "GenSigTimeoutTime" BU_SG_REL_ ZR_High SG_ 2589283758 DU3_FB_Mode 5000;
BA_REL_ "GenSigTimeoutTime" BU_SG_REL_ ZR_MIB_TOP_ab_Gen3 SG_ 2589283758 DU3_FB_Mode 5000;
BA_REL_ "GenSigTimeoutTime" BU_SG_REL_ ZR_High SG_ 2589283758 DU3_DispDerating 5000;
BA_REL_ "GenSigTimeoutTime" BU_SG_REL_ ZR_MIB_TOP_ab_Gen3 SG_ 2589283758 DU3_DispDerating 5000;
BA_REL_ "GenSigTimeoutTime" BU_SG_REL_ ZR_High SG_ 2589283758 DU3_KL_30F 5000;
BA_REL_ "GenSigTimeoutTime" BU_SG_REL_ ZR_MIB_TOP_ab_Gen3 SG_ 2589283758 DU3_KL_30F 5000;
BA_REL_ "GenSigTimeoutTime" BU_SG_REL_ ZR_High SG_ 2589283758 DU3_TempSens 5000;
BA_REL_ "GenSigTimeoutTime" BU_SG_REL_ ZR_MIB_TOP_ab_Gen3 SG_ 2589283758 DU3_TempSens 5000;
BA_REL_ "GenSigTimeoutTime" BU_SG_REL_ ZR_High SG_ 2589283758 DU3_TempSensMax 5000;
BA_REL_ "GenSigTimeoutTime" BU_SG_REL_ ZR_MIB_TOP_ab_Gen3 SG_ 2589283758 DU3_TempSensMax 5000;
BA_REL_ "GenSigTimeoutTime" BU_SG_REL_ ZR_High SG_ 2589283758 DU3_Variant 5000;
BA_REL_ "GenSigTimeoutTime" BU_SG_REL_ ZR_MIB_TOP_ab_Gen3 SG_ 2589283758 DU3_Variant 5000;
BA_REL_ "GenSigTimeoutTime" BU_SG_REL_ ZR_High SG_ 2589283758 DU3_Zulieferer 5000;
BA_REL_ "GenSigTimeoutTime" BU_SG_REL_ ZR_MIB_TOP_ab_Gen3 SG_ 2589283758 DU3_Zulieferer 5000;
BA_REL_ "GenSigTimeoutTime" BU_SG_REL_ ZR_High SG_ 2589283758 DU3_HU_Fotosensor 5000;
BA_REL_ "GenSigTimeoutTime" BU_SG_REL_ ZR_MIB_TOP_ab_Gen3 SG_ 2589283758 DU3_HU_Fotosensor 5000;
BA_REL_ "GenSigTimeoutTime" BU_SG_REL_ ZR_High SG_ 2589283758 DU3_Schatter_Fehlerstatus 5000;
BA_REL_ "GenSigTimeoutTime" BU_SG_REL_ ZR_MIB_TOP_ab_Gen3 SG_ 2589283758 DU3_Schatter_Fehlerstatus 5000;
VAL_ 2527679645 NFC_MiKo_NFC_Device_gekoppelt 1 "NFC_Device_gekoppelt" 0 "Init_kein_NFC_Device_gekoppelt" ;
VAL_ 2527679645 NFC_MiKo_Laden_unterbrechen 1 "Laden_unterbrechen" 0 "Init_keine_Unterbrechung" ;
VAL_ 2527679645 NFC_MiKo_Fehler 16 "Ueberhitzung" 8 "Ueberspannung" 4 "Unterspannung" 2 "Antenne_defekt" 1 "SG_defekt" 0 "SG_iO" ;
VAL_ 2527679645 NFC_MiKo_ESM_aktiv 1 "ESM_aktiv" 0 "Init_kein_ESM" ;
VAL_ 1139 BT_Variant 0 "Init" 1 "BT_Low_TONE/CAR" 2 "BT_Low_NAV/TEL" 3 "BT_Low+_TONE/CAR" 4 "BT_Low+_NAV/TEL" 5 "BT_Touchwheel" 6 "BT_AllInTouch" ;
VAL_ 1139 SystemMode 0 "Bootloader" 1 "Applikation" ;
VAL_ 1139 BT_DKM_Kurzschluss_GND 0 "normal" 1 "Fehler" ;
VAL_ 1139 BT_DKM_Kurzschluss_Ubat 0 "normal" 1 "Fehler" ;
VAL_ 1139 BT_DKM_Unterbrechung 0 "normal" 1 "Fehler" ;
VAL_ 1139 BT_DKM_k_Hallsignal 0 "normal" 1 "Fehler" ;
VAL_ 1139 BT_DKM_Ueberlastung 0 "normal" 1 "Fehler" ;
VAL_ 1139 BT_DKM_Mech_Flauf 0 "normal" 1 "Fehler" ;
VAL_ 1139 BT_KBD_TP_Fehler 0 "kein_Fehler" ;
VAL_ 1139 BT_DKM_EL_Fehler 0 "normal" 1 "Fehler" ;
VAL_ 1139 BT_DKM_Manual_Operation 0 "Display_in_Ruhe" 1 "Display_per_Hand_geschlossen" 2 "Display_per_Hand_geoeffnet" 3 "reserviert" ;
VAL_ 1139 BT_LIN1_Unterbrechung 0 "normal" 1 "Fehler" ;
VAL_ 1139 BT_LIN2_Unterbrechung 0 "normal" 1 "Fehler" ;
VAL_ 1139 BT_DKM_Mech_Flauf_2 0 "normal" 1 "Fehler" ;
VAL_ 1635 BEM_02_Abschaltstufen 0 "Stufe 0 (keine Einschraenkungen)" 1 "Stufe 1" 2 "Stufe 2" 3 "Stufe 3" 4 "Transportmodus" 7 "Ruhestrommessmodus" ;
VAL_ 1635 BEM_STH_Zielzeit 14 "Init" 15 "Fehler" ;
VAL_ 1635 BEM_MMI_Vorwarnung 0 "keine Anzeige" 1 "Anzeige MMI-Vorwarnung" ;
VAL_ 1635 NVEM_Freigabe_ZusBatt_Laden 0 "keine_Freigabe_Laderelais" 1 "Freigabe_Laderelais_schliessen" ;
VAL_ 1635 NVEM_Anf_SD_schalten 0 "Anf_SD_Nachlauf_nicht_aktiv" 1 "Anf_SD_Nachlauf_aktiv" ;
VAL_ 1635 BEM_Generatordiagnose 0 "keine Anzeige" 1 "Ladekontrollanzeige ein (Vorhalt)" 2 "rotes Batteriesymbol und Text (Generator defekt)" 3 "Hybrid_DCDC_Wandler_defekt" ;
VAL_ 1635 BEM_Red_Innengeblaese 0 "keine Reduzierung" 1 "Reduzierung Stufe 1" 2 "Reduzierung Stufe 2" 3 "Reduzierung Stufe 2 und Abschaltung Kompressor" ;
VAL_ 1635 BEM_STH_Einschaltverbot 0 "volle Verfuegbarkeit Standheizung/-lueftung" 1 "Standheizung/-lueftung nicht aktivierbar" ;
VAL_ 1635 BEM_HL_Regelung_Status 0 "HL_Regelung_inaktiv_(vor_und_waehrend_Motorstart)" 1 "HL_Regelung_Stufe_1" 2 "HL_Regelung_Stufe_2" 3 "HL_Regelung_Stufe_3" 4 "Verbrauchernotabschaltung_(VNA)" 5 "HL_Regelung_Stufe_5" 7 "Default" ;
VAL_ 1635 BEM_Ladezustand 14 "Init" 15 "Fehler" ;
VAL_ 1635 BEM_Batteriediagnose 0 "keine_Anzeige" 1 "nicht_belegt" 2 "Anzeige_aberkannte_Batterie" 3 "Anzeige_schwache_Batterie" 4 "Anzeige_Batterie_OK" 5 "Anzeige_Batterie_Laden" 6 "Anzeige_Batterie_Pruefen" 7 "Fehler" ;
VAL_ 1635 MIB_Stromsparmodus 0 "inaktiv" 1 "aktiv" ;
VAL_ 1635 BEM_REK_aktiv 0 "keine_Rekuperationsfreigabe" 1 "Rekuperationsfreigabe" ;
VAL_ 1635 BEM_EMLIN_ungueltig 0 "Signale_gueltig" 1 "Signale_ungueltig" ;
VAL_ 1635 BEM_Batt_Ab 0 "verbunden" 1 "nicht_verbunden" ;
VAL_ 1635 BEM_UBDM 0 "Init" 255 "Fehler" ;
VAL_ 1635 BEM_Anf_KL15_schalten 0 "Keine_Einschraenkung_Kl15" 1 "Empfehlung_auto_Abschaltung_Kl15" 2 "Veto_auto_Abschaltung_Kl15" 3 "Veto_auto_Abschaltung_Fahrtbetrieb" ;
VAL_ 1635 NVEM_Batterie_Service 0 "kein_Service" 1 "Service_Information1" 2 "Service_Information2" 3 "Service_Information3" ;
VAL_ 1635 NVEM_Freigabe_OnlineUpdate 0 "keine_Freigabe" 1 "Freigabe" ;
VAL_ 2617219605 ZR_KL_30F 254 "Init" 255 "Fehler" ;
VAL_ 2617219605 ZR_TempSens 254 "Init" 255 "Fehler" ;
VAL_ 2617219605 Reset_Counter 254 "Init" 255 "Fehler" ;
VAL_ 2617219605 MMI_State 0 "MMI_OFF" 1 "MMI_IOC" 2 "MMI_STDBY" 3 "MMI_ON" 4 "MMI_STDBY_PWR_SAVE" 5 "MMI_STDBY_RESTR" 6 "MMI_ON_DIAG" 7 "MMI_ON_TEL" 8 "MMI_ON_SWDL" 9 "MMI_ON_CUST_SWDL" 10 "MMI_STDBY_PWR_SAVE_1" 11 "MMI_STDBY_PWR_SAVE_2" 12 "MMI_STANDBY_CUST_SWDL" 13 "MMI_ONLINE_IOC" 14 "MMI_ONLINE" 15 "MMI_PHONE_IOC" 16 "MMI_PHONE" 17 "MMI_RTC" 18 "MMI_DCI" ;
VAL_ 2617219605 Tel_aktiv 0 "inaktiv" 1 "aktiv" ;
VAL_ 2617219605 Routeg_aktiv 0 "inaktiv" 1 "aktiv" ;
VAL_ 2617219605 SI_MOST_Status 0 "MOST_sleep_(Licht_AUS)" 1 "MOST_aktiv_(Kommunikation_moeglich)" ;
VAL_ 2617219605 ZR_State_DU_1 0 "Disp_Off" 1 "Disp_On" 2 "LowPow" ;
VAL_ 2617219605 Tel_SIM_aktiv 0 "inaktiv" 1 "aktiv" ;
VAL_ 1714 DGN_Verlernzaehler 255 "ungültiger Zählerstand oder kein gültiger Fahrzyklus" ;
VAL_ 1714 KBI_Kilometerstand 1048574 "Init" 1048575 "Fehler" ;
VAL_ 1714 UH_Monat 0 "Init" 14 "Relatives_Datum" 15 "Fehler" ;
VAL_ 1714 UH_Tag 0 "Init" ;
VAL_ 1714 Vehicle_Driving_Cycle 0 "kein_Driving_Cycle_erkannt" 1 "Driving_Cycle_erkannt" ;
VAL_ 1714 Kombi_02_alt 0 "aktuell" 1 "veraltet" ;
VAL_ 1714 Uhrzeit_01_alt 0 "aktuell" 1 "veraltet" ;
VAL_ 1520 DI_KL_58xd 254 "Init" 255 "Fehler" ;
VAL_ 1520 DI_KL_58xs 126 "Init" 127 "Fehler" ;
VAL_ 1520 DI_KL_58xt 126 "Init" 127 "Fehler" ;
VAL_ 1520 BCM1_Stellgroesse_Kl_58s 125 "Nicht_verbaut" 126 "Init" 127 "Fehler" ;
VAL_ 1142 DU_State 0 "Disp_Off" 1 "Disp_On" 2 "LowPow" ;
VAL_ 1142 SystemMode 0 "Bootloader" 1 "Applikation" ;
VAL_ 1142 DU_Temp_Fehler 0 "normal" 1 "Fehler" ;
VAL_ 1142 DU_KL30_Uebersp_Fehler 0 "normal" 1 "Fehler" ;
VAL_ 1142 DU_KL30_Untersp_Fehler 0 "normal" 1 "Fehler" ;
VAL_ 1142 FB_Mode 0 "inaktiv" 1 "aktiv" ;
VAL_ 1142 DU_DispDerating 254 "Init" 255 "Fehler" ;
VAL_ 1142 DU_KL_30F 254 "Init" 255 "Fehler" ;
VAL_ 1142 DU_TempSens 254 "Init" 255 "Fehler" ;
VAL_ 1142 DU_TempSensMax 254 "Init" 255 "Fehler" ;
VAL_ 1142 DU_Variant 254 "Init" ;
VAL_ 1142 HU_Fotosensor 0 "Sensor unbeleuchtet" 510 "Initialwert" 511 "Fehler" ;
VAL_ 1143 DU_Betriebsdauer_min 255 "Fehler" ;
VAL_ 1143 DU_Betriebsdauer_std 65535 "Fehler" ;
VAL_ 1143 DU_HintGrdBelKurzschl 0 "normal" 1 "Fehler" ;
VAL_ 1143 DU_HintGrdBelUnterbr 0 "normal" 1 "Fehler" ;
VAL_ 1143 EEPROM_Fehler 0 "normal" 1 "Fehler" ;
VAL_ 1143 DU1_SW_inkonsistent 0 "kein_Fehler" 1 "Fehler" ;
VAL_ 1143 DU1_HDCP_Status 0 "kein_Fehler" 1 "Fehler" ;
VAL_ 1143 LVDS_Status 0 "LVDS_Unlocked" 1 "LVDS_Lock" ;
VAL_ 1143 ZR_Lenkerpos_Status 0 "links" 1 "rechts" ;
VAL_ 1143 DU1_Touch_Fehlerstatus 0 "kein_Fehler" 1 "SW_Fehler" 2 "HW_Fehler" ;
VAL_ 1143 DU1_Haptik_Fehlerstatus 0 "kein_Fehler" 1 "SW_Fehler" 2 "HW_Fehler" ;
VAL_ 1143 DU1_LVDS_Splitter_Fehlerstatus 0 "kein_Fehler" 1 "SW_Fehler" 2 "HW_Fehler" ;
VAL_ 561 DU1_KS_aktiv_anderer_Grund 0 "kein_Fehler" 1 "Fehler" ;
VAL_ 561 DU1_KS_aktiv_falsche_Auth 0 "kein_Fehler" 1 "Fehler" ;
VAL_ 561 DU1_KS_aktiv_Manipulationsschutz 0 "kein_Fehler" 1 "Fehler" ;
VAL_ 561 DU1_KS_FIS_unplausibel 0 "kein_Fehler" 1 "Fehler" ;
VAL_ 561 DU1_KS_keine_Grundeinstellung 0 "kein_Fehler" 1 "Fehler" ;
VAL_ 561 DU1_KS_SHE_keine_Grundeinst 0 "kein_Fehler" 1 "Fehler" ;
VAL_ 561 DU1_Touchstatus 0 "NoTouch" 1 "Touch" 2 "Release" ;
VAL_ 561 DU1_Fehlerstatus 0 "NoError" 1 "Backlight_defect" 2 "Backlight_off" ;
VAL_ 561 DU1_Slider_Locked 0 "unlocked" 1 "locked" ;
VAL_ 1144 DU2_State 0 "Disp_Off" 1 "Disp_On" 2 "LowPow" ;
VAL_ 1144 DU2_SystemMode 0 "Bootloader" 1 "Applikation" ;
VAL_ 1144 DU2_Temp_Fehler 0 "normal" 1 "Fehler" ;
VAL_ 1144 DU2_KL30_Uebersp_Fehler 0 "normal" 1 "Fehler" ;
VAL_ 1144 DU2_KL30_Untersp_Fehler 0 "normal" 1 "Fehler" ;
VAL_ 1144 DU2_FB_Mode 0 "inaktiv" 1 "aktiv" ;
VAL_ 1144 DU2_DispDerating 254 "Init" 255 "Fehler" ;
VAL_ 1144 DU2_KL_30F 254 "Init" 255 "Fehler" ;
VAL_ 1144 DU2_TempSens 254 "Init" 255 "Fehler" ;
VAL_ 1144 DU2_TempSensMax 254 "Init" 255 "Fehler" ;
VAL_ 1144 DU2_Variant 254 "Init" ;
VAL_ 1144 DU2_HU_Fotosensor 0 "Sensor unbeleuchtet" 510 "Initialwert" 511 "Fehler" ;
VAL_ 1145 DU2_Betriebsdauer_min 255 "Fehler" ;
VAL_ 1145 DU2_Betriebsdauer_std 65535 "Fehler" ;
VAL_ 1145 DU2_HintGrdBelKurzschl 0 "normal" 1 "Fehler" ;
VAL_ 1145 DU2_HintGrdBelUnterbr 0 "normal" 1 "Fehler" ;
VAL_ 1145 DU2_EEPROM_Fehler 0 "normal" 1 "Fehler" ;
VAL_ 1145 DU2_SW_inkonsistent 0 "kein_Fehler" 1 "Fehler" ;
VAL_ 1145 DU2_HDCP_Status 0 "kein_Fehler" 1 "Fehler" ;
VAL_ 1145 DU2_LVDS_Status 0 "LVDS_Unlocked" 1 "LVDS_Lock" ;
VAL_ 1145 DU2_ZR_Lenkerpos_Status 0 "links" 1 "rechts" ;
VAL_ 1145 DU2_Touch_Fehlerstatus 0 "kein_Fehler" 1 "SW_Fehler" 2 "HW_Fehler" ;
VAL_ 1145 DU2_Haptik_Fehlerstatus 0 "kein_Fehler" 1 "SW_Fehler" 2 "HW_Fehler" ;
VAL_ 1145 DU2_LVDS_Splitter_Fehlerstatus 0 "kein_Fehler" 1 "SW_Fehler" 2 "HW_Fehler" ;
VAL_ 2589283758 DU3_State 0 "Disp_Off" 1 "Disp_On" 2 "LowPow" ;
VAL_ 2589283758 DU3_SystemMode 0 "Bootloader" 1 "Applikation" ;
VAL_ 2589283758 DU3_Temp_Fehler 0 "normal" 1 "Fehler" ;
VAL_ 2589283758 DU3_KL30_Uebersp_Fehler 0 "normal" 1 "Fehler" ;
VAL_ 2589283758 DU3_KL30_Untersp_Fehler 0 "normal" 1 "Fehler" ;
VAL_ 2589283758 DU3_FB_Mode 0 "inaktiv" 1 "aktiv" ;
VAL_ 2589283758 DU3_DispDerating 254 "Init" 255 "Fehler" ;
VAL_ 2589283758 DU3_KL_30F 254 "Init" 255 "Fehler" ;
VAL_ 2589283758 DU3_TempSens 254 "Init" 255 "Fehler" ;
VAL_ 2589283758 DU3_TempSensMax 254 "Init" 255 "Fehler" ;
VAL_ 2589283758 DU3_Variant 254 "Init" ;
VAL_ 2589283758 DU3_HU_Fotosensor 0 "Sensor unbeleuchtet" 510 "Initialwert" 511 "Fehler" ;
VAL_ 2589283758 DU3_Schatter_Fehlerstatus 0 "Kein_Fehler_Erkant" 1 "SW_Fehler_erkannt" 2 "HW_Fehler_erkannt" ;
